VERSION ""

NS_ :

BS_:
BU_: Receiver ChassisBus VehicleBus PartyBus apb ui app aps bms gtwu odin cc cmp cp das dif dir di epas3p epas3s epbl epbr esp fc gtw hvp ibst ocs1p park pcs pmf pmr pm ptc radc rcm2 rcm sccm scm scs tas tpms umc vcfront vcleft vcright vcsec GTW

BO_ 905 ID389DAS_status2: 8 ChassisBus
   SG_ DAS_ACC_report : 26|5@1+ (1,0) [0|24] "" Receiver
   SG_ DAS_accSpeedLimit : 0|10@1+ (0.2,0) [0|204.6] "mph" Receiver
   SG_ DAS_activationFailureStatus : 14|2@1+ (1,0) [0|2] "" Receiver
   SG_ DAS_csaState : 32|2@1+ (1,0) [0|3] "" Receiver
   SG_ DAS_driverInteractionLevel : 38|2@1+ (1,0) [0|2] "" Receiver
   SG_ DAS_longCollisionWarning : 48|4@1+ (1,0) [0|15] "" Receiver
   SG_ DAS_pmmCameraFaultReason : 24|2@1+ (1,0) [0|2] "" Receiver
   SG_ DAS_pmmLoggingRequest : 13|1@1+ (1,0) [0|1] "" Receiver
   SG_ DAS_pmmObstacleSeverity : 10|3@1+ (1,0) [0|7] "" Receiver
   SG_ DAS_pmmRadarFaultReason : 19|2@1+ (1,0) [0|2] "" Receiver
   SG_ DAS_pmmSysFaultReason : 21|3@1+ (1,0) [0|7] "" Receiver
   SG_ DAS_pmmUltrasonicsFaultReason : 16|3@1+ (1,0) [0|4] "" Receiver
   SG_ DAS_ppOffsetDesiredRamp : 40|8@1+ (0.01,-1.28) [-1.28|1.27] "m" Receiver
   SG_ DAS_radarTelemetry : 34|2@1+ (1,0) [0|2] "" Receiver
   SG_ DAS_relaxCruiseLimits : 31|1@1+ (1,0) [0|1] "" Receiver
   SG_ DAS_robState : 36|2@1+ (1,0) [0|3] "" Receiver
   SG_ DAS_status2Checksum : 56|8@1+ (1,0) [0|255] "" Receiver
   SG_ DAS_status2Counter : 52|4@1+ (1,0) [0|15] "" Receiver

BO_ 921 ID399DAS_status: 8 ChassisBus
   SG_ DAS_autoLaneChangeState : 46|5@1+ (1,0) [0|31] "" Receiver
   SG_ DAS_autoParked : 25|1@1+ (1,0) [0|1] "" Receiver
   SG_ DAS_autoparkReady : 24|1@1+ (1,0) [0|1] "" Receiver
   SG_ DAS_autoparkWaitingForBrake : 26|1@1+ (1,0) [0|1] "" Receiver
   SG_ DAS_autopilotHandsOnState : 42|4@1+ (1,0) [0|15] "" Receiver
   SG_ DAS_autopilotState : 0|4@1+ (1,0) [0|15] "" Receiver
   SG_ DAS_blindSpotRearLeft : 4|2@1+ (1,0) [0|3] "" Receiver
   SG_ DAS_blindSpotRearRight : 6|2@1+ (1,0) [0|3] "" Receiver
   SG_ DAS_fleetSpeedState : 40|2@1+ (1,0) [0|3] "" Receiver
   SG_ DAS_forwardCollisionWarning : 22|2@1+ (1,0) [0|3] "" Receiver
   SG_ DAS_fusedSpeedLimit : 8|5@1+ (5,0) [0|150] "kph/mph" Receiver
   SG_ DAS_heaterState : 21|1@1+ (1,0) [0|1] "" Receiver
   SG_ DAS_laneDepartureWarning : 37|3@1+ (1,0) [0|5] "" Receiver
   SG_ DAS_lssState : 29|3@1+ (1,0) [0|7] "" Receiver
   SG_ DAS_sideCollisionAvoid : 32|2@1+ (1,0) [0|3] "" Receiver
   SG_ DAS_sideCollisionInhibit : 36|1@1+ (1,0) [0|1] "" Receiver
   SG_ DAS_sideCollisionWarning : 34|2@1+ (1,0) [0|3] "" Receiver
   SG_ DAS_statusChecksum : 56|8@1+ (1,0) [0|255] "" Receiver
   SG_ DAS_statusCounter : 52|4@1+ (1,0) [0|15] "" Receiver
   SG_ DAS_summonAvailable : 51|1@1+ (1,0) [0|1] "" Receiver
   SG_ DAS_summonClearedGate : 15|1@1+ (1,0) [0|1] "" Receiver
   SG_ DAS_summonFwdLeashReached : 27|1@1+ (1,0) [0|1] "" Receiver
   SG_ DAS_summonObstacle : 14|1@1+ (1,0) [0|1] "" Receiver
   SG_ DAS_summonRvsLeashReached : 28|1@1+ (1,0) [0|1] "" Receiver
   SG_ DAS_suppressSpeedWarning : 13|1@1+ (1,0) [0|1] "" Receiver
   SG_ DAS_visionOnlySpeedLimit : 16|5@1+ (5,0) [0|150] "kph/mph" Receiver

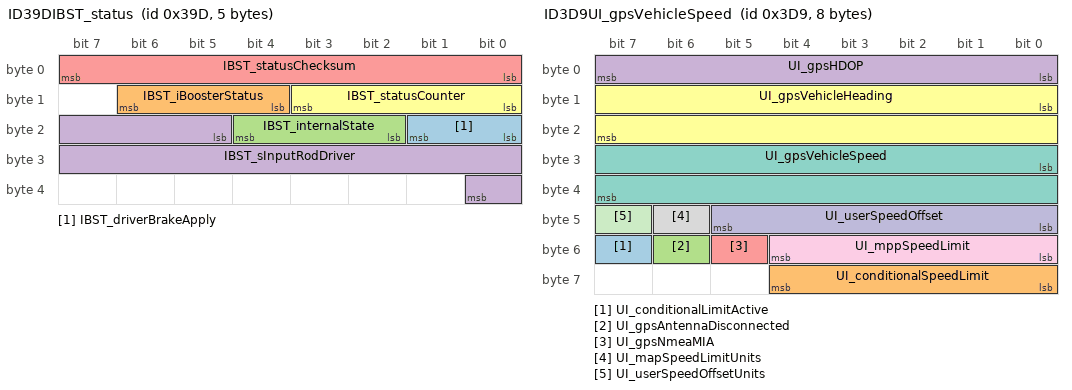
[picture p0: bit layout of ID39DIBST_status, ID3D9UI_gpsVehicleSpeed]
BO_ 925 ID39DIBST_status: 5 ChassisBus
   SG_ IBST_driverBrakeApply : 16|2@1+ (1,0) [0|3] "" Receiver
   SG_ IBST_iBoosterStatus : 12|3@1+ (1,0) [0|6] "" Receiver
   SG_ IBST_internalState : 18|3@1+ (1,0) [0|6] "" Receiver
   SG_ IBST_sInputRodDriver : 21|12@1+ (0.015625,-5) [-5|47] "mm" Receiver
   SG_ IBST_statusChecksum : 0|8@1+ (1,0) [0|255] "" Receiver
   SG_ IBST_statusCounter : 8|4@1+ (1,0) [0|15] "" Receiver

BO_ 929 ID3A1VCFRONT_vehicleStatus: 8 VehicleBus
   SG_ VCFRONT_12vStatusForDrive : 14|2@1+ (1,0) [0|2] "" Receiver
   SG_ VCFRONT_2RowCenterUnbuckled : 38|2@1+ (1,0) [0|2] "" Receiver
   SG_ VCFRONT_2RowLeftUnbuckled : 36|2@1+ (1,0) [0|2] "" Receiver
   SG_ VCFRONT_2RowRightUnbuckled : 40|2@1+ (1,0) [0|2] "" Receiver
   SG_ VCFRONT_APGlassHeaterState : 2|3@1+ (1,0) [0|4] "" Receiver
   SG_ VCFRONT_accPlusAvailable : 9|1@1+ (1,0) [0|1] "" Receiver
   SG_ VCFRONT_batterySupportRequest : 27|1@1+ (1,0) [0|1] "" Receiver
   SG_ VCFRONT_bmsHvChargeEnable : 0|1@1+ (1,0) [0|1] "" Receiver
   SG_ VCFRONT_diPowerOnState : 10|3@1+ (1,0) [0|4] "" Receiver
   SG_ VCFRONT_driverBuckleStatus : 30|1@1+ (1,0) [0|1] "" Receiver
   SG_ VCFRONT_driverDoorStatus : 31|1@1+ (1,0) [0|1] "" Receiver
   SG_ VCFRONT_driverIsLeaving : 28|1@1+ (1,0) [0|1] "" Receiver
   SG_ VCFRONT_driverIsLeavingAnySpeed : 13|1@1+ (1,0) [0|1] "" Receiver
   SG_ VCFRONT_driverPresent : 7|1@1+ (1,0) [0|1] "" Receiver
   SG_ VCFRONT_driverUnbuckled : 32|2@1+ (1,0) [0|2] "" Receiver
   SG_ VCFRONT_ota12VSupportRequest : 29|1@1+ (1,0) [0|1] "" Receiver
   SG_ VCFRONT_passengerPresent : 8|1@1+ (1,0) [0|1] "" Receiver
   SG_ VCFRONT_passengerUnbuckled : 34|2@1+ (1,0) [0|2] "" Receiver
   SG_ VCFRONT_pcs12vVoltageTarget : 16|11@1+ (0.01,0) [0|16] "V" Receiver
   SG_ VCFRONT_pcsEFuseVoltage : 42|10@1+ (0.1,0) [0|102.2] "V" Receiver
   SG_ VCFRONT_preconditionRequest : 1|1@1+ (1,0) [0|1] "" Receiver
   SG_ VCFRONT_standbySupplySupported : 6|1@1+ (1,0) [0|1] "" Receiver
   SG_ VCFRONT_thermalSystemType : 5|1@1+ (1,0) [0|1] "" Receiver
   SG_ VCFRONT_vehicleStatusChecksum : 56|8@1+ (1,0) [0|255] "" Receiver
   SG_ VCFRONT_vehicleStatusCounter : 52|4@1+ (1,0) [0|15] "" Receiver

BO_ 985 ID3D9UI_gpsVehicleSpeed: 8 ChassisBus
   SG_ UI_conditionalLimitActive : 55|1@1+ (1,0) [0|1] "" Receiver
   SG_ UI_conditionalSpeedLimit : 56|5@1+ (5,0) [0|155] "kph/mph" Receiver
   SG_ UI_gpsAntennaDisconnected : 54|1@1+ (1,0) [0|1] "" Receiver
   SG_ UI_gpsHDOP : 0|8@1+ (0.1,0) [0|25.5] "" Receiver
   SG_ UI_gpsNmeaMIA : 53|1@1+ (1,0) [0|1] "" Receiver
   SG_ UI_gpsVehicleHeading : 8|16@1+ (0.0078125,0) [0|511.992] "deg" Receiver
   SG_ UI_gpsVehicleSpeed : 24|16@1+ (0.00390625,0) [0|250.996] "kph" Receiver
   SG_ UI_mapSpeedLimitUnits : 46|1@1+ (1,0) [0|1] "" Receiver
   SG_ UI_mppSpeedLimit : 48|5@1+ (5,0) [0|155] "kph/mph" Receiver
   SG_ UI_userSpeedOffset : 40|6@1+ (1,-30) [-30|33] "kph/mph" Receiver
   SG_ UI_userSpeedOffsetUnits : 47|1@1+ (1,0) [0|1] "" Receiver

BO_ 994 ID3E2VCLEFT_lightStatus: 7 VehicleBus
   SG_ VCLEFT_FLMapLightStatus : 6|2@1+ (1,0) [0|3] "" Receiver
   SG_ VCLEFT_FLMapLightSwitchPressed : 14|1@1+ (1,0) [0|1] "" Receiver
   SG_ VCLEFT_FRMapLightStatus : 8|2@1+ (1,0) [0|3] "" Receiver
   SG_ VCLEFT_FRMapLightSwitchPressed : 15|1@1+ (1,0) [0|1] "" Receiver
   SG_ VCLEFT_RLMapLightStatus : 10|2@1+ (1,0) [0|3] "" Receiver
   SG_ VCLEFT_RLMapLightSwitchPressed : 16|1@1+ (1,0) [0|1] "" Receiver
   SG_ VCLEFT_RRMapLightStatus : 12|2@1+ (1,0) [0|3] "" Receiver
   SG_ VCLEFT_RRMapLightSwitchPressed : 17|1@1+ (1,0) [0|1] "" Receiver
   SG_ VCLEFT_brakeLightStatus : 0|2@1+ (1,0) [0|3] "" Receiver
   SG_ VCLEFT_brakeTrailerLightStatus : 22|2@1+ (1,0) [0|3] "" Receiver
   SG_ VCLEFT_dynamicBrakeLightStatus : 44|2@1+ (1,0) [0|2] "" Receiver
   SG_ VCLEFT_fogTrailerLightStatus : 26|2@1+ (1,0) [0|3] "" Receiver
   SG_ VCLEFT_frontRideHeight : 28|8@1- (1,0) [-127|127] "mm" Receiver
   SG_ VCLEFT_leftTurnTrailerLightStatu : 18|2@1+ (1,0) [0|3] "" Receiver
   SG_ VCLEFT_rearRideHeight : 36|8@1- (1,0) [-127|127] "mm" Receiver
   SG_ VCLEFT_reverseTrailerLightStatus : 49|2@1+ (1,0) [0|3] "" Receiver
   SG_ VCLEFT_rideHeightSensorFault : 48|1@1+ (1,0) [0|1] "" Receiver
   SG_ VCLEFT_rightTrnTrailerLightStatu : 20|2@1+ (1,0) [0|3] "" Receiver
   SG_ VCLEFT_tailLightStatus : 2|2@1+ (1,0) [0|3] "" Receiver
   SG_ VCLEFT_tailTrailerLightStatus : 24|2@1+ (1,0) [0|3] "" Receiver
   SG_ VCLEFT_trailerDetected : 46|2@1+ (1,0) [0|3] "" Receiver
   SG_ VCLEFT_turnSignalStatus : 4|2@1+ (1,0) [0|3] "" Receiver

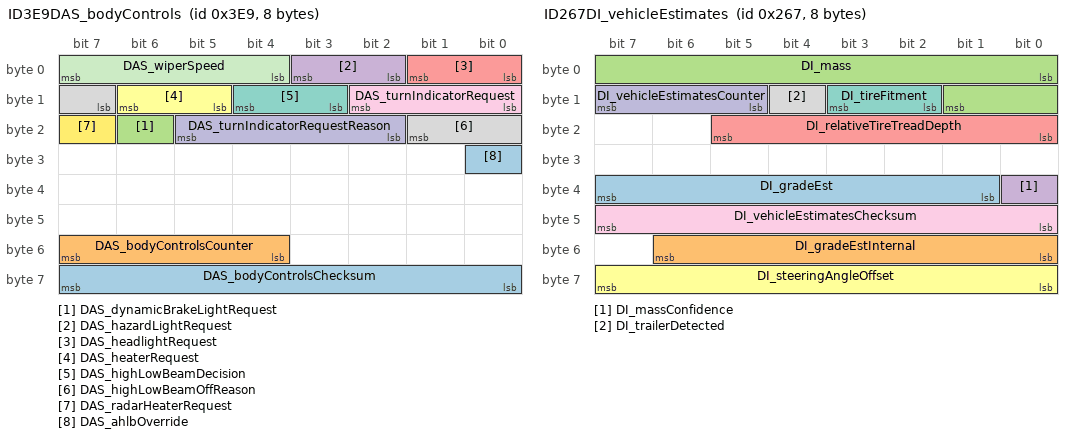
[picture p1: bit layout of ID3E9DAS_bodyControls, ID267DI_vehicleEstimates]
BO_ 1001 ID3E9DAS_bodyControls: 8 VehicleBus
   SG_ DAS_bodyControlsChecksum : 56|8@1+ (1,0) [0|255] "" Receiver
   SG_ DAS_bodyControlsCounter : 52|4@1+ (1,0) [0|15] "" Receiver
   SG_ DAS_dynamicBrakeLightRequest : 22|1@1+ (1,0) [0|1] "" Receiver
   SG_ DAS_hazardLightRequest : 2|2@1+ (1,0) [0|3] "" Receiver
   SG_ DAS_headlightRequest : 0|2@1+ (1,0) [0|3] "" Receiver
   SG_ DAS_heaterRequest : 13|2@1+ (1,0) [0|2] "" Receiver
   SG_ DAS_highLowBeamDecision : 11|2@1+ (1,0) [0|3] "" Receiver
   SG_ DAS_highLowBeamOffReason : 15|3@1+ (1,0) [0|5] "" Receiver
   SG_ DAS_turnIndicatorRequest : 8|3@1+ (1,0) [0|4] "" Receiver
   SG_ DAS_turnIndicatorRequestReason : 18|4@1+ (1,0) [0|12] "" Receiver
   SG_ DAS_wiperSpeed : 4|4@1+ (1,0) [0|15] "" Receiver
   SG_ DAS_radarHeaterRequest : 23|1@1+ (1,0) [0|1] "" Receiver
   SG_ DAS_ahlbOverride : 24|1@1+ (1,0) [0|1] "" Receiver

BO_ 1011 ID3F3UI_odo: 3 ChassisBus
   SG_ UI_odometer : 0|24@1+ (0.1,0) [0|1.67772e+06] "km" Receiver

BO_ 1013 ID3F5VCFRONT_lighting: 8 VehicleBus
   SG_ VCFRONT_DRLLeftStatus : 36|2@1+ (1,0) [0|3] "" Receiver
   SG_ VCFRONT_DRLRightStatus : 38|2@1+ (1,0) [0|3] "" Receiver
   SG_ VCFRONT_ambientLightingBrightnes : 8|8@1+ (0.5,0) [0|127] "%" Receiver
   SG_ VCFRONT_approachLightingRequest : 25|1@1+ (1,0) [0|1] "" Receiver
   SG_ VCFRONT_courtesyLightingRequest : 24|1@1+ (1,0) [0|1] "" Receiver
   SG_ VCFRONT_fogLeftStatus : 40|2@1+ (1,0) [0|3] "" Receiver
   SG_ VCFRONT_fogRightStatus : 42|2@1+ (1,0) [0|3] "" Receiver
   SG_ VCFRONT_hazardLightRequest : 4|4@1+ (1,0) [0|8] "" Receiver
   SG_ VCFRONT_hazardSwitchBacklight : 27|1@1+ (1,0) [0|1] "" Receiver
   SG_ VCFRONT_highBeamLeftStatus : 32|2@1+ (1,0) [0|3] "" Receiver
   SG_ VCFRONT_highBeamRightStatus : 34|2@1+ (1,0) [0|3] "" Receiver
   SG_ VCFRONT_highBeamSwitchActive : 58|1@1+ (1,0) [0|1] "" Receiver
   SG_ VCFRONT_indicatorLeftRequest : 0|2@1+ (1,0) [0|2] "" Receiver
   SG_ VCFRONT_indicatorRightRequest : 2|2@1+ (1,0) [0|2] "" Receiver
   SG_ VCFRONT_lowBeamLeftStatus : 28|2@1+ (1,0) [0|3] "" Receiver
   SG_ VCFRONT_lowBeamRightStatus : 30|2@1+ (1,0) [0|3] "" Receiver
   SG_ VCFRONT_lowBeamsCalibrated : 62|1@1+ (1,0) [0|1] "" Receiver
   SG_ VCFRONT_lowBeamsOnForDRL : 61|1@1+ (1,0) [0|1] "" Receiver
   SG_ VCFRONT_parkLeftStatus : 54|2@1+ (1,0) [0|3] "" Receiver
   SG_ VCFRONT_parkRightStatus : 56|2@1+ (1,0) [0|3] "" Receiver
   SG_ VCFRONT_seeYouHomeLightingReq : 26|1@1+ (1,0) [0|1] "" Receiver
   SG_ VCFRONT_sideMarkersStatus : 44|2@1+ (1,0) [0|3] "" Receiver
   SG_ VCFRONT_sideRepeaterLeftStatus : 46|2@1+ (1,0) [0|3] "" Receiver
   SG_ VCFRONT_sideRepeaterRightStatus : 48|2@1+ (1,0) [0|3] "" Receiver
   SG_ VCFRONT_simLatchingStalk : 59|2@1+ (1,0) [0|3] "" Receiver
   SG_ VCFRONT_switchLightingBrightness : 16|8@1+ (0.5,0) [0|127] "%" Receiver
   SG_ VCFRONT_turnSignalLeftStatus : 50|2@1+ (1,0) [0|3] "" Receiver
   SG_ VCFRONT_turnSignalRightStatus : 52|2@1+ (1,0) [0|3] "" Receiver

BO_ 1016 ID3F8UI_driverAssistControl: 8 ChassisBus
   SG_ UI_accFollowDistanceSetting : 45|3@1+ (1,0) [0|7] "" Receiver
   SG_ UI_adaptiveSetSpeedEnable : 39|1@1+ (1,0) [0|1] "" Receiver
   SG_ UI_alcOffHighwayEnable : 56|1@1+ (1,0) [0|1] "" Receiver
   SG_ UI_autoSummonEnable : 10|1@1+ (1,0) [0|1] "" Receiver
   SG_ UI_autopilotControlRequest : 0|1@1+ (1,0) [0|1] "" Receiver
   SG_ UI_coastToCoast : 9|1@1+ (1,0) [0|1] "" Receiver
   SG_ UI_curvSpeedAdaptDisable : 4|1@1+ (1,0) [0|1] "" Receiver
   SG_ UI_curvatureDatabaseOnly : 22|1@1+ (1,0) [0|1] "" Receiver
   SG_ UI_dasDeveloper : 5|1@1+ (1,0) [0|1] "" Receiver
   SG_ UI_driveOnMapsEnable : 13|1@1+ (1,0) [0|1] "" Receiver
   SG_ UI_drivingSide : 40|2@1+ (1,0) [0|2] "" Receiver
   SG_ UI_enableBrakeLightPulse : 63|1@1+ (1,0) [0|1] "" Receiver
   SG_ UI_enableClipTelemetry : 42|1@1+ (1,0) [0|1] "" Receiver
   SG_ UI_enableRoadSegmentTelemetry : 44|1@1+ (1,0) [0|1] "" Receiver
   SG_ UI_enableTripTelemetry : 43|1@1+ (1,0) [0|1] "" Receiver
   SG_ UI_enableVinAssociation : 6|1@1+ (1,0) [0|1] "" Receiver
   SG_ UI_enableVisionOnlyStops : 60|1@1+ (1,0) [0|1] "" Receiver
   SG_ UI_exceptionListEnable : 11|1@1+ (1,0) [0|1] "" Receiver
   SG_ UI_followNavRouteEnable : 49|1@1+ (1,0) [0|1] "" Receiver
   SG_ UI_fuseHPPDisable : 17|1@1+ (1,0) [0|1] "" Receiver
   SG_ UI_fuseLanesDisable : 16|1@1+ (1,0) [0|1] "" Receiver
   SG_ UI_fuseVehiclesDisable : 18|1@1+ (1,0) [0|1] "" Receiver
   SG_ UI_handsOnRequirementDisable : 14|1@1+ (1,0) [0|1] "" Receiver
   SG_ UI_hasDriveOnNav : 48|1@1+ (1,0) [0|1] "" Receiver
   SG_ UI_lssElkEnabled : 23|1@1+ (1,0) [0|1] "" Receiver
   SG_ UI_lssLdwEnabled : 8|1@1+ (1,0) [0|1] "" Receiver
   SG_ UI_lssLkaEnabled : 7|1@1+ (1,0) [0|1] "" Receiver
   SG_ UI_roadCheckDisable : 12|1@1+ (1,0) [0|1] "" Receiver
   SG_ UI_selfParkRequest : 28|4@1+ (1,0) [0|15] "" Receiver
   SG_ UI_smartSummonType : 58|2@1+ (1,0) [0|2] "" Receiver
   SG_ UI_source3D : 61|2@1+ (1,0) [0|2] "" Receiver
   SG_ UI_summonEntryType : 26|2@1+ (1,0) [0|3] "" Receiver
   SG_ UI_summonExitType : 24|2@1+ (1,0) [0|3] "" Receiver
   SG_ UI_summonHeartbeat : 2|2@1+ (1,0) [0|3] "" Receiver
   SG_ UI_summonReverseDist : 32|6@1+ (1,0) [0|63] "" Receiver
   SG_ UI_ulcBlindSpotConfig : 52|2@1+ (1,0) [0|2] "" Receiver
   SG_ UI_ulcOffHighway : 15|1@1+ (1,0) [0|1] "" Receiver
   SG_ UI_ulcSpeedConfig : 50|2@1+ (1,0) [0|3] "" Receiver
   SG_ UI_ulcStalkConfirm : 1|1@1+ (1,0) [0|1] "" Receiver
   SG_ UI_undertakeAssistEnable : 38|1@1+ (1,0) [0|1] "" Receiver
   SG_ UI_validationLoop : 57|1@1+ (1,0) [0|1] "" Receiver
   SG_ UI_visionSpeedType : 20|2@1+ (1,0) [0|3] "" Receiver

BO_ 1021 ID3FDUI_autopilotControl: 8 ChassisBus
   SG_ UI_autopilotControlIndex M : 0|3@1+ (1,0) [0|7] "" Receiver
   SG_ UI_apmv3Branch m1 : 40|3@1+ (1,0) [0|5] "" Receiver
   SG_ UI_applyEceR79 m1 : 19|1@1+ (1,0) [0|1] "" Receiver
   SG_ UI_blindspotDistance m0 : 15|3@1+ (1,0) [0|5] "" Receiver
   SG_ UI_blindspotMinSpeed m0 : 11|4@1+ (1,0) [0|10] "" Receiver
   SG_ UI_blindspotTTC m0 : 18|3@1+ (1,0) [0|7] "" Receiver
   SG_ UI_disableBackup m1 : 30|1@1+ (1,0) [0|1] "" Receiver
   SG_ UI_disableFisheye m1 : 25|1@1+ (1,0) [0|1] "" Receiver
   SG_ UI_disableLeftPillar m1 : 26|1@1+ (1,0) [0|1] "" Receiver
   SG_ UI_disableLeftRepeater m1 : 28|1@1+ (1,0) [0|1] "" Receiver
   SG_ UI_disableMain m1 : 23|1@1+ (1,0) [0|1] "" Receiver
   SG_ UI_disableNarrow m1 : 24|1@1+ (1,0) [0|1] "" Receiver
   SG_ UI_disableRadar m1 : 31|1@1+ (1,0) [0|1] "" Receiver
   SG_ UI_disableRightPillar m1 : 27|1@1+ (1,0) [0|1] "" Receiver
   SG_ UI_disableRightRepeater m1 : 29|1@1+ (1,0) [0|1] "" Receiver
   SG_ UI_donAlcProgGoreAbortThres m0 : 29|4@1+ (1,0) [0|9] "" Receiver
   SG_ UI_donDisableAutoWiperDuration m0 : 4|3@1+ (1,0) [0|6] "" Receiver
   SG_ UI_donDisableCutin m0 : 24|1@1+ (1,0) [0|1] "" Receiver
   SG_ UI_donDisableOnAutoWiperSpeed m0 : 7|4@1+ (1,0) [0|15] "" Receiver
   SG_ UI_donMinGoreWidthForAbortMap m0 : 25|4@1+ (1,0) [0|11] "" Receiver
   SG_ UI_donMinGoreWidthForAbortNotMap m0 : 33|4@1+ (1,0) [0|11] "" Receiver
   SG_ UI_donStopEndOfRampBuffer m0 : 21|3@1+ (1,0) [0|4] "" Receiver
   SG_ UI_driverMonitorConfirmation m1 : 17|1@1+ (1,0) [0|1] "" Receiver
   SG_ UI_enableAutopilotStopWarning m1 : 44|1@1+ (1,0) [0|1] "" Receiver
   SG_ UI_enableCabinCamera m1 : 43|1@1+ (1,0) [0|1] "" Receiver
   SG_ UI_enableCabinCameraTelemetry m1 : 48|1@1+ (1,0) [0|1] "" Receiver
   SG_ UI_enableMapStops m1 : 20|1@1+ (1,0) [0|1] "" Receiver
   SG_ UI_factorySummonEnable m1 : 39|1@1+ (1,0) [0|1] "" Receiver
   SG_ UI_fsdStopsControlEnabled m0 : 38|1@1+ (1,0) [0|1] "" Receiver
   SG_ UI_fsdVisualizationEnabled m0 : 37|1@1+ (1,0) [0|1] "" Receiver
   SG_ UI_hardCoreSummon m1 : 47|1@1+ (1,0) [0|1] "" Receiver
   SG_ UI_homelinkNearby m0 : 45|1@1+ (1,0) [0|1] "" Receiver
   SG_ UI_hovEnabled m0 : 3|1@1+ (1,0) [0|1] "" Receiver
   SG_ UI_noStalkConfirmAlertChime m1 : 37|1@1+ (1,0) [0|1] "" Receiver
   SG_ UI_noStalkConfirmAlertHaptic m1 : 32|1@1+ (1,0) [0|1] "" Receiver
   SG_ UI_showLaneGraph m1 : 45|1@1+ (1,0) [0|1] "" Receiver
   SG_ UI_showTrackLabels m1 : 46|1@1+ (1,0) [0|1] "" Receiver
   SG_ UI_ulcSnooze m1 : 36|1@1+ (1,0) [0|1] "" Receiver

BO_ 611 ID263VCRIGHT_logging10Hz: 8 VehicleBus
   SG_ VCRIGHT_logging10HzIndex M : 0|3@1+ (1,0) [0|4] "" Receiver
   SG_ VCRIGHT_EvapPulldownBias m3 : 8|8@1+ (0.4,0) [0|100] "%" Receiver
   SG_ VCRIGHT_EvapPulldownBiasActive m3 : 16|1@1+ (1,0) [0|1] "" Receiver
   SG_ VCRIGHT_hvacCabinHumidityLevel m2 : 55|8@1+ (1,0) [0|100] "%" Receiver
   SG_ VCRIGHT_hvacEstimateWindshieldRH m2 : 39|8@1+ (1,0) [0|150] "%" Receiver
   SG_ VCRIGHT_hvacFilterLifeDetectActi m2 : 3|1@1+ (1,0) [0|1] "" Receiver
   SG_ VCRIGHT_hvacFlashFoggingDetected m2 : 63|1@1+ (1,0) [0|1] "" Receiver
   SG_ VCRIGHT_hvacFoggingRiskLevel m2 : 47|8@1+ (1,0) [0|100] "%" Receiver
   SG_ VCRIGHT_hvacIntakeActuatorState m2 : 24|2@1+ (1,0) [0|2] "" Receiver
   SG_ VCRIGHT_hvacIntakeOperationMode m2 : 10|1@1+ (1,0) [0|1] "" Receiver
   SG_ VCRIGHT_hvacIntakePosition m1 : 56|8@1+ (0.4,0) [0|100] "%" Receiver
   SG_ VCRIGHT_hvacIntakeTarget m0 : 56|8@1+ (0.4,0) [0|100] "%" Receiver
   SG_ VCRIGHT_hvacLHBleedActuatorState m2 : 11|2@1+ (1,0) [0|2] "" Receiver
   SG_ VCRIGHT_hvacLHBleedOperationMode m2 : 4|1@1+ (1,0) [0|1] "" Receiver
   SG_ VCRIGHT_hvacLHBleedPosition m1 : 8|8@1+ (0.4,0) [0|100] "%" Receiver
   SG_ VCRIGHT_hvacLHBleedTarget m0 : 8|8@1+ (0.4,0) [0|100] "%" Receiver
   SG_ VCRIGHT_hvacLHVaneActuatorState m2 : 16|2@1+ (1,0) [0|2] "" Receiver
   SG_ VCRIGHT_hvacLHVaneOperationMode m2 : 6|1@1+ (1,0) [0|1] "" Receiver
   SG_ VCRIGHT_hvacLHVanePosition m1 : 24|8@1+ (0.4,0) [0|100] "%" Receiver
   SG_ VCRIGHT_hvacLHVaneTarget m0 : 24|8@1+ (0.4,0) [0|100] "%" Receiver
   SG_ VCRIGHT_hvacLowerModeActState m2 : 22|2@1+ (1,0) [0|2] "" Receiver
   SG_ VCRIGHT_hvacLowerModeOpMode m2 : 9|1@1+ (1,0) [0|1] "" Receiver
   SG_ VCRIGHT_hvacLowerModePosition m1 : 48|8@1+ (0.4,0) [0|100] "%" Receiver
   SG_ VCRIGHT_hvacLowerModeTarget m0 : 48|8@1+ (0.4,0) [0|100] "%" Receiver
   SG_ VCRIGHT_hvacRHBleedActuatorState m2 : 13|2@1+ (1,0) [0|2] "" Receiver
   SG_ VCRIGHT_hvacRHBleedOperationMode m2 : 5|1@1+ (1,0) [0|1] "" Receiver
   SG_ VCRIGHT_hvacRHBleedPosition m1 : 16|8@1+ (0.4,0) [0|100] "%" Receiver
   SG_ VCRIGHT_hvacRHBleedTarget m0 : 16|8@1+ (0.4,0) [0|100] "%" Receiver
   SG_ VCRIGHT_hvacRHVaneActuatorState m2 : 18|2@1+ (1,0) [0|2] "" Receiver
   SG_ VCRIGHT_hvacRHVaneOperationMode m2 : 7|1@1+ (1,0) [0|1] "" Receiver
   SG_ VCRIGHT_hvacRHVanePosition m1 : 32|8@1+ (0.4,0) [0|100] "%" Receiver
   SG_ VCRIGHT_hvacRHVaneTarget m0 : 32|8@1+ (0.4,0) [0|100] "%" Receiver
   SG_ VCRIGHT_hvacUpperModeActState m2 : 20|2@1+ (1,0) [0|2] "" Receiver
   SG_ VCRIGHT_hvacUpperModeOpMode m2 : 8|1@1+ (1,0) [0|1] "" Receiver
   SG_ VCRIGHT_hvacUpperModePosition m1 : 40|8@1+ (0.4,0) [0|100] "%" Receiver
   SG_ VCRIGHT_hvacUpperModeTarget m0 : 40|8@1+ (0.4,0) [0|100] "%" Receiver
   SG_ VCRIGHT_timeLeftToCabinModelInit m2 : 32|7@1+ (1,0) [0|127] "" Receiver

BO_ 615 ID267DI_vehicleEstimates: 8 VehicleBus
   SG_ DI_gradeEst : 33|7@1- (1,0) [-40|40] "%" Receiver
   SG_ DI_gradeEstInternal : 48|7@1- (1,0) [-40|40] "%" Receiver
   SG_ DI_mass : 0|10@1+ (5,1900) [1900|7010] "kg" Receiver
   SG_ DI_massConfidence : 32|1@1+ (1,0) [0|1] "" Receiver
   SG_ DI_relativeTireTreadDepth : 16|6@1- (0.2,0) [-6.2|6.2] "mm" Receiver
   SG_ DI_steeringAngleOffset : 56|8@1- (0.2,0) [-25.6|25.4] "Deg" Receiver
   SG_ DI_tireFitment : 10|2@1+ (1,0) [0|3] "" Receiver
   SG_ DI_trailerDetected : 12|1@1+ (1,0) [0|1] "" Receiver
   SG_ DI_vehicleEstimatesChecksum : 40|8@1+ (1,0) [0|255] "" Receiver
   SG_ DI_vehicleEstimatesCounter : 13|3@1+ (1,0) [0|7] "" Receiver

BO_ 642 ID282VCLEFT_hvacBlowerFeedback: 8 VehicleBus
   SG_ VCLEFT_blowerIndex M : 0|2@1+ (1,0) [0|1] "" Receiver
   SG_ VCLEFT_hvacBlowerCBCCtrlState m1 : 58|3@1+ (1,0) [0|4] "" Receiver
   SG_ VCLEFT_hvacBlowerCBCEstState m1 : 54|4@1+ (1,0) [0|14] "" Receiver
   SG_ VCLEFT_hvacBlowerEnabled m0 : 2|1@1+ (1,0) [0|1] "" Receiver
   SG_ VCLEFT_hvacBlowerFETTemp m0 : 44|7@1+ (1.5,-40) [-40|149] "C" Receiver
   SG_ VCLEFT_hvacBlowerFault m0 : 59|1@1+ (1,0) [0|1] "" Receiver
   SG_ VCLEFT_hvacBlowerIPhase0 m1 : 10|8@1+ (0.2,0) [0|50] "A" Receiver
   SG_ VCLEFT_hvacBlowerIPhase1 m1 : 18|8@1+ (0.2,0) [0|50] "A" Receiver
   SG_ VCLEFT_hvacBlowerIPhase2 m1 : 26|8@1+ (0.2,0) [0|50] "A" Receiver
   SG_ VCLEFT_hvacBlowerITerm m0 : 51|7@1+ (0.05,-1.5) [-1.5|4.5] "Nm" Receiver
   SG_ VCLEFT_hvacBlowerInitd m0 : 58|1@1+ (1,0) [0|1] "" Receiver
   SG_ VCLEFT_hvacBlowerLimitFETTemps m0 : 60|1@1+ (1,0) [0|1] "" Receiver
   SG_ VCLEFT_hvacBlowerOutputDuty m0 : 3|7@1+ (1,0) [0|100] "%" Receiver
   SG_ VCLEFT_hvacBlowerPowerOn m0 : 61|1@1+ (1,0) [0|1] "" Receiver
   SG_ VCLEFT_hvacBlowerRPMActual m0 : 20|10@1+ (10,0) [0|10000] "rpm" Receiver
   SG_ VCLEFT_hvacBlowerRPMTarget m0 : 10|10@1+ (10,0) [0|10000] "rpm" Receiver
   SG_ VCLEFT_hvacBlowerRs m1 : 2|8@1+ (0.25,0) [0|60] "mOhm" Receiver
   SG_ VCLEFT_hvacBlowerRsOnlineActive m1 : 61|1@1+ (1,0) [0|1] "" Receiver
   SG_ VCLEFT_hvacBlowerSpiError m0 : 62|1@1+ (1,0) [0|1] "" Receiver
   SG_ VCLEFT_hvacBlowerTorque m0 : 34|10@1+ (0.006,-1.5) [-1.5|4.5] "Nm" Receiver
   SG_ VCLEFT_hvacBlower_IO_CBC_HEAD m1 : 34|4@1+ (1,0) [0|15] "" Receiver
   SG_ VCLEFT_hvacBlower_IO_CBC_Status m1 : 43|1@1+ (1,0) [0|1] "" Receiver
   SG_ VCLEFT_hvacBlower_IO_CBC_TAIL m1 : 38|4@1+ (1,0) [0|15] "" Receiver
   SG_ VCLEFT_hvacBlower_IO_CBC_TAIL_va m1 : 42|1@1+ (1,0) [0|1] "" Receiver
   SG_ VCLEFT_hvacBlower_IO_CBC_numUart m1 : 46|8@1+ (1,0) [0|255] "" Receiver

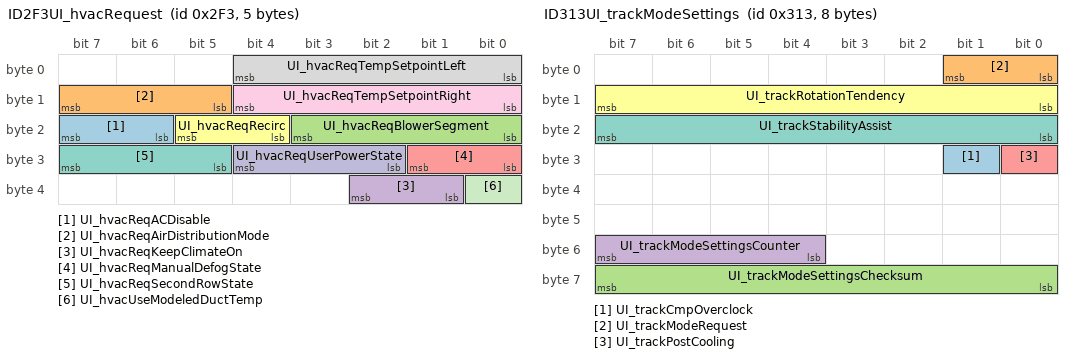
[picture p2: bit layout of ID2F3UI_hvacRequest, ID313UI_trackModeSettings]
BO_ 755 ID2F3UI_hvacRequest: 5 VehicleBus
   SG_ UI_hvacReqACDisable : 22|2@1+ (1,0) [0|2] "" Receiver
   SG_ UI_hvacReqAirDistributionMode : 13|3@1+ (1,0) [0|7] "" Receiver
   SG_ UI_hvacReqBlowerSegment : 16|4@1+ (1,0) [0|11] "" Receiver
   SG_ UI_hvacReqKeepClimateOn : 33|2@1+ (1,0) [0|3] "" Receiver
   SG_ UI_hvacReqManualDefogState : 24|2@1+ (1,0) [0|2] "" Receiver
   SG_ UI_hvacReqRecirc : 20|2@1+ (1,0) [0|2] "" Receiver
   SG_ UI_hvacReqSecondRowState : 29|3@1+ (1,0) [0|4] "" Receiver
   SG_ UI_hvacReqTempSetpointLeft : 0|5@1+ (0.5,15) [15|28] "C" Receiver
   SG_ UI_hvacReqTempSetpointRight : 8|5@1+ (0.5,15) [15|28] "C" Receiver
   SG_ UI_hvacReqUserPowerState : 26|3@1+ (1,0) [0|4] "" Receiver
   SG_ UI_hvacUseModeledDuctTemp : 32|1@1+ (1,0) [0|1] "" Receiver

BO_ 787 ID313UI_trackModeSettings: 8 VehicleBus
   SG_ UI_trackCmpOverclock : 25|1@1+ (1,0) [0|1] "" Receiver
   SG_ UI_trackModeRequest : 0|2@1+ (1,0) [0|2] "" Receiver
   SG_ UI_trackModeSettingsChecksum : 56|8@1+ (1,0) [0|255] "" Receiver
   SG_ UI_trackModeSettingsCounter : 52|4@1+ (1,0) [0|15] "" Receiver
   SG_ UI_trackPostCooling : 24|1@1+ (1,0) [0|1] "" Receiver
   SG_ UI_trackRotationTendency : 8|8@1+ (0.5,0) [0|100] "%" Receiver
   SG_ UI_trackStabilityAssist : 16|8@1+ (0.5,0) [0|100] "%" Receiver

BO_ 821 ID335RearDIinfo: 8 VehicleBus
   SG_ DIR_infoIndex M : 0|8@1+ (1,0) [0|255] "" Receiver
   SG_ DIR_FPGA_version m16 : 48|8@1+ (1,0) [0|255] "" Receiver
   SG_ DIR_appGitHash m17 : 8|56@1+ (1,0) [0|7.20576e+16] "" Receiver
   SG_ DIR_applicationCrc m13 : 32|32@1+ (1,0) [0|4.29497e+09] "" Receiver
   SG_ DIR_assemblyId m11 : 24|8@1+ (1,0) [0|255] "" Receiver
   SG_ DIR_bootGitHash m18 : 8|56@1+ (1,0) [0|7.20576e+16] "" Receiver
   SG_ DIR_bootloaderCrc m20 : 32|32@1+ (1,0) [0|4.29497e+09] "" Receiver
   SG_ DIR_buildConfigurationId m10 : 16|16@1+ (1,0) [0|65535] "" Receiver
   SG_ DIR_buildType m10 : 8|3@1+ (1,0) [0|4] "" Receiver
   SG_ DIR_componentId m10 : 48|16@1+ (1,0) [0|65535] "" Receiver
   SG_ DIR_hardwareId m10 : 32|8@1+ (1,0) [0|252] "" Receiver
   SG_ DIR_infoBootLdUdsProtocolVersion m20 : 8|8@1+ (1,0) [0|255] "" Receiver
   SG_ DIR_oilPumpAppCrc m16 : 16|32@1+ (1,0) [0|4.29497e+09] "" Receiver
   SG_ DIR_oilPumpBuildType m16 : 8|3@1+ (1,0) [0|4] "" Receiver
   SG_ DIR_pcbaId m11 : 16|8@1+ (1,0) [0|255] "" Receiver
   SG_ DIR_platformTyp m19 : 8|8@1+ (1,0) [0|255] "" Receiver
   SG_ DIR_subUsageId m11 : 48|16@1+ (1,0) [0|65535] "" Receiver
   SG_ DIR_subcomponentGitHash m31 : 8|56@1+ (1,0) [0|7.20576e+16] "" Receiver
   SG_ DIR_usageId m11 : 32|16@1+ (1,0) [0|65535] "" Receiver

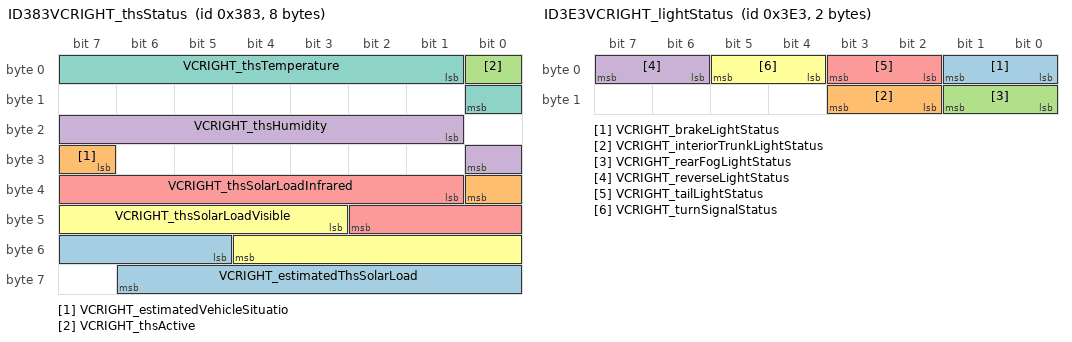
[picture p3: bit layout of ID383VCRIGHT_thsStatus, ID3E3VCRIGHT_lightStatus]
BO_ 899 ID383VCRIGHT_thsStatus: 8 VehicleBus
   SG_ VCRIGHT_estimatedThsSolarLoad : 53|10@1+ (1,0) [0|1022] "W/m2" Receiver
   SG_ VCRIGHT_estimatedVehicleSituatio : 31|2@1+ (1,0) [0|2] "" Receiver
   SG_ VCRIGHT_thsActive : 0|1@1+ (1,0) [0|1] "" Receiver
   SG_ VCRIGHT_thsHumidity : 17|8@1+ (1,0) [0|100] "%" Receiver
   SG_ VCRIGHT_thsSolarLoadInfrared : 33|10@1+ (1,0) [0|1022] "W/m2" Receiver
   SG_ VCRIGHT_thsSolarLoadVisible : 43|10@1+ (1,0) [0|1022] "W/m2" Receiver
   SG_ VCRIGHT_thsTemperature : 1|8@1- (1,-40) [-40|150] "C" Receiver

BO_ 915 ID393VCRIGHT_epbmDebug: 8 VehicleBus
   SG_ VCRIGHT_epbmDebugIndex M : 0|1@1+ (1,0) [0|1] "" Receiver
   SG_ VCRIGHT_cdpEnumDummy m1 : 24|2@1+ (1,0) [0|2] "" Receiver
   SG_ VCRIGHT_epbFaultStatus m0 : 58|2@1+ (1,0) [0|3] "" Receiver
   SG_ VCRIGHT_epbMotorCurrent m0 : 5|11@1+ (0.01,0) [0|20.47] "A" Receiver
   SG_ VCRIGHT_epbSummonState m0 : 45|3@1+ (1,0) [0|6] "" Receiver
   SG_ VCRIGHT_epbUnitStatus m0 : 51|5@1+ (1,0) [0|22] "" Receiver
   SG_ VCRIGHT_epbmApplyVoltage m0 : 16|11@1+ (0.01,0) [0|20.47] "A" Receiver
   SG_ VCRIGHT_epbmCaliperState m0 : 1|3@1+ (1,0) [0|6] "" Receiver
   SG_ VCRIGHT_epbmDynApplyingAllowed m1 : 9|1@1+ (1,0) [0|1] "" Receiver
   SG_ VCRIGHT_epbmDynamicAllowed m1 : 2|1@1+ (1,0) [0|1] "" Receiver
   SG_ VCRIGHT_epbmFaultAllowed m1 : 11|1@1+ (1,0) [0|1] "" Receiver
   SG_ VCRIGHT_epbmFaultStatus m0 : 56|2@1+ (1,0) [0|3] "" ui
   SG_ VCRIGHT_epbmMotorEnabled m0 : 4|1@1+ (1,0) [0|1] "" Receiver
   SG_ VCRIGHT_epbmOpenAllowed m1 : 1|1@1+ (1,0) [0|1] "" Receiver
   SG_ VCRIGHT_epbmParkAllowed m1 : 3|1@1+ (1,0) [0|1] "" Receiver
   SG_ VCRIGHT_epbmParkingAllowed m1 : 8|1@1+ (1,0) [0|1] "" Receiver
   SG_ VCRIGHT_epbmReleaseVoltage m0 : 27|11@1+ (0.01,0) [0|20.47] "A" Receiver
   SG_ VCRIGHT_epbmReleasingAllowed m1 : 10|1@1+ (1,0) [0|1] "" Receiver
   SG_ VCRIGHT_epbmServiceAllowed m1 : 5|1@1+ (1,0) [0|1] "" Receiver
   SG_ VCRIGHT_epbmStartAllowed m1 : 4|1@1+ (1,0) [0|1] "" Receiver
   SG_ VCRIGHT_epbmSummonAllowed m1 : 12|1@1+ (1,0) [0|1] "" Receiver
   SG_ VCRIGHT_epbmSummonParkAllowed m1 : 13|1@1+ (1,0) [0|1] "" Receiver
   SG_ VCRIGHT_epbmSummonReleaseAllowed m1 : 14|1@1+ (1,0) [0|1] "" Receiver
   SG_ VCRIGHT_epbmSummonState m0 : 48|3@1+ (1,0) [0|6] "" Receiver
   SG_ VCRIGHT_epbmSystemStatus m0 : 60|4@1+ (1,0) [0|8] "" Receiver
   SG_ VCRIGHT_epbmUnknownAllowed m1 : 16|1@1+ (1,0) [0|1] "" Receiver
   SG_ VCRIGHT_epbmWinchAllowed m1 : 6|1@1+ (1,0) [0|1] "" Receiver
   SG_ VCRIGHT_epbmWinchReleaseAllowed m1 : 7|1@1+ (1,0) [0|1] "" Receiver
   SG_ VCRIGHT_summonActiveAllowed m1 : 19|1@1+ (1,0) [0|1] "" Receiver
   SG_ VCRIGHT_summonArmedAllowed m1 : 18|1@1+ (1,0) [0|1] "" Receiver
   SG_ VCRIGHT_summonCompleteAllowed m1 : 20|1@1+ (1,0) [0|1] "" Receiver
   SG_ VCRIGHT_summonFaultAllowed m1 : 21|1@1+ (1,0) [0|1] "" Receiver
   SG_ VCRIGHT_summonFaultReason m0 : 40|5@1+ (1,0) [0|28] "" Receiver
   SG_ VCRIGHT_summonIdleAllowed m1 : 17|1@1+ (1,0) [0|1] "" Receiver
   SG_ VCRIGHT_summonInitAllowed m1 : 15|1@1+ (1,0) [0|1] "" Receiver
   SG_ VCRIGHT_summonUnavailableAllowed m1 : 22|1@1+ (1,0) [0|1] "" Receiver

BO_ 947 ID3B3UI_vehicleControl2: 4 VehicleBus
   SG_ UI_PINToDriveEnabled : 6|1@1+ (1,0) [0|1] "" Receiver
   SG_ UI_PINToDrivePassed : 7|1@1+ (1,0) [0|1] "" Receiver
   SG_ UI_UMCUpdateInhibit : 2|1@1+ (1,0) [0|1] "" Receiver
   SG_ UI_VCLEFTFeature1 : 15|1@1+ (1,0) [0|1] "" Receiver
   SG_ UI_VCSECFeature1 : 14|1@1+ (1,0) [0|1] "" Receiver
   SG_ UI_WCUpdateInhibit : 3|1@1+ (1,0) [0|1] "" Receiver
   SG_ UI_alarmTriggerRequest : 13|1@1+ (1,0) [0|1] "" Receiver
   SG_ UI_autoRollWindowsOnLockEnable : 29|1@1+ (1,0) [0|1] "" Receiver
   SG_ UI_autopilotPowerStateRequest : 25|2@1+ (1,0) [0|2] "" Receiver
   SG_ UI_batteryPreconditioningRequest : 23|1@1+ (1,0) [0|1] "" Receiver
   SG_ UI_coastDownMode : 24|1@1+ (1,0) [0|1] "" Receiver
   SG_ UI_efuseMXResistanceEstArmed : 30|1@1+ (1,0) [0|1] "" Receiver
   SG_ UI_freeRollModeRequest : 19|1@1+ (1,0) [0|1] "" Receiver
   SG_ UI_gloveboxRequest : 0|1@1+ (1,0) [0|1] "" Receiver
   SG_ UI_lightSwitch : 9|3@1+ (1,0) [0|4] "" Receiver
   SG_ UI_locksPanelActive : 5|1@1+ (1,0) [0|1] "" Receiver
   SG_ UI_readyToAddKey : 12|1@1+ (1,0) [0|1] "" Receiver
   SG_ UI_shorted12VCellTestMode : 27|2@1+ (1,0) [0|2] "" Receiver
   SG_ UI_soundHornOnLock : 4|1@1+ (1,0) [0|1] "" Receiver
   SG_ UI_summonState : 16|2@1+ (1,0) [0|3] "" Receiver
   SG_ UI_trunkRequest : 1|1@1+ (1,0) [0|1] "" Receiver
   SG_ UI_userPresent : 18|1@1+ (1,0) [0|1] "" Receiver
   SG_ UI_windowRequest : 20|3@1+ (1,0) [0|4] "" Receiver

BO_ 963 ID3C3VCRIGHT_switchStatus: 7 VehicleBus
   SG_ VCRIGHT_2RowSeatReclineSwitch : 54|1@1+ (1,0) [0|1] "" Receiver
   SG_ VCRIGHT_btnWindowAutoDownRF : 27|1@1+ (1,0) [0|1] "" Receiver
   SG_ VCRIGHT_btnWindowAutoDownRR : 31|1@1+ (1,0) [0|1] "" Receiver
   SG_ VCRIGHT_btnWindowAutoUpRF : 25|1@1+ (1,0) [0|1] "" Receiver
   SG_ VCRIGHT_btnWindowAutoUpRR : 29|1@1+ (1,0) [0|1] "" Receiver
   SG_ VCRIGHT_btnWindowDownRF : 26|1@1+ (1,0) [0|1] "" Receiver
   SG_ VCRIGHT_btnWindowDownRR : 30|1@1+ (1,0) [0|1] "" Receiver
   SG_ VCRIGHT_btnWindowSwPackAutoDwnLF : 35|1@1+ (1,0) [0|1] "" Receiver
   SG_ VCRIGHT_btnWindowSwPackAutoDwnLR : 39|1@1+ (1,0) [0|1] "" Receiver
   SG_ VCRIGHT_btnWindowSwPackAutoDwnRR : 52|1@1+ (1,0) [0|1] "" Receiver
   SG_ VCRIGHT_btnWindowSwPackAutoUpLF : 33|1@1+ (1,0) [0|1] "" Receiver
   SG_ VCRIGHT_btnWindowSwPackAutoUpLR : 37|1@1+ (1,0) [0|1] "" Receiver
   SG_ VCRIGHT_btnWindowSwPackAutoUpRR : 50|1@1+ (1,0) [0|1] "" Receiver
   SG_ VCRIGHT_btnWindowSwPackDownLF : 34|1@1+ (1,0) [0|1] "" Receiver
   SG_ VCRIGHT_btnWindowSwPackDownLR : 38|1@1+ (1,0) [0|1] "" Receiver
   SG_ VCRIGHT_btnWindowSwPackDownRR : 51|1@1+ (1,0) [0|1] "" Receiver
   SG_ VCRIGHT_btnWindowSwPackUpLF : 32|1@1+ (1,0) [0|1] "" Receiver
   SG_ VCRIGHT_btnWindowSwPackUpLR : 36|1@1+ (1,0) [0|1] "" Receiver
   SG_ VCRIGHT_btnWindowSwPackUpRR : 49|1@1+ (1,0) [0|1] "" Receiver
   SG_ VCRIGHT_btnWindowUpRF : 24|1@1+ (1,0) [0|1] "" Receiver
   SG_ VCRIGHT_btnWindowUpRR : 28|1@1+ (1,0) [0|1] "" Receiver
   SG_ VCRIGHT_frontBuckleSwitch : 40|2@1+ (1,0) [0|3] "" Receiver
   SG_ VCRIGHT_frontOccupancySwitch : 42|2@1+ (1,0) [0|3] "" Receiver
   SG_ VCRIGHT_frontSeatBackrestBack : 12|2@1+ (1,0) [0|3] "" Receiver
   SG_ VCRIGHT_frontSeatBackrestForward : 14|2@1+ (1,0) [0|3] "" Receiver
   SG_ VCRIGHT_frontSeatLiftDown : 8|2@1+ (1,0) [0|3] "" Receiver
   SG_ VCRIGHT_frontSeatLiftUp : 10|2@1+ (1,0) [0|3] "" Receiver
   SG_ VCRIGHT_frontSeatLumbarDown : 16|2@1+ (1,0) [0|3] "" Receiver
   SG_ VCRIGHT_frontSeatLumbarIn : 20|2@1+ (1,0) [0|3] "" Receiver
   SG_ VCRIGHT_frontSeatLumbarOut : 22|2@1+ (1,0) [0|3] "" Receiver
   SG_ VCRIGHT_frontSeatLumbarUp : 18|2@1+ (1,0) [0|3] "" Receiver
   SG_ VCRIGHT_frontSeatTiltDown : 4|2@1+ (1,0) [0|3] "" Receiver
   SG_ VCRIGHT_frontSeatTiltUp : 6|2@1+ (1,0) [0|3] "" Receiver
   SG_ VCRIGHT_frontSeatTrackBack : 0|2@1+ (1,0) [0|3] "" Receiver
   SG_ VCRIGHT_frontSeatTrackForward : 2|2@1+ (1,0) [0|3] "" Receiver
   SG_ VCRIGHT_liftgateShutfaceSwitchPr : 53|1@1+ (1,0) [0|1] "" Receiver
   SG_ VCRIGHT_rearCenterBuckleSwitch : 44|2@1+ (1,0) [0|3] "" Receiver
   SG_ VCRIGHT_rearRightBuckleSwitch : 46|2@1+ (1,0) [0|3] "" Receiver
   SG_ VCRIGHT_trunkExtReleasePressed : 48|1@1+ (1,0) [0|1] "" Receiver

BO_ 995 ID3E3VCRIGHT_lightStatus: 2 VehicleBus
   SG_ VCRIGHT_brakeLightStatus : 0|2@1+ (1,0) [0|3] "" Receiver
   SG_ VCRIGHT_interiorTrunkLightStatus : 10|2@1+ (1,0) [0|3] "" Receiver
   SG_ VCRIGHT_rearFogLightStatus : 8|2@1+ (1,0) [0|3] "" Receiver
   SG_ VCRIGHT_reverseLightStatus : 6|2@1+ (1,0) [0|3] "" Receiver
   SG_ VCRIGHT_tailLightStatus : 2|2@1+ (1,0) [0|3] "" Receiver
   SG_ VCRIGHT_turnSignalStatus : 4|2@1+ (1,0) [0|3] "" Receiver

BO_ 1622 ID656FrontDIinfo: 8 VehicleBus
   SG_ DIF_infoIndex M : 0|8@1+ (1,0) [0|255] "" Receiver
   SG_ DIF_FPGA_version m16 : 48|8@1+ (1,0) [0|255] "" Receiver
   SG_ DIF_appGitHash m17 : 8|56@1+ (1,0) [0|7.20576e+16] "" Receiver
   SG_ DIF_applicationCrc m13 : 32|32@1+ (1,0) [0|4.29497e+09] "" Receiver
   SG_ DIF_assemblyId m11 : 24|8@1+ (1,0) [0|255] "" Receiver
   SG_ DIF_bootGitHash m18 : 8|56@1+ (1,0) [0|7.20576e+16] "" Receiver
   SG_ DIF_bootloaderCrc m20 : 32|32@1+ (1,0) [0|4.29497e+09] "" Receiver
   SG_ DIF_buildConfigurationId m10 : 16|16@1+ (1,0) [0|65535] "" Receiver
   SG_ DIF_buildType m10 : 8|3@1+ (1,0) [0|4] "" Receiver
   SG_ DIF_componentId m10 : 48|16@1+ (1,0) [0|65535] "" Receiver
   SG_ DIF_hardwareId m10 : 32|8@1+ (1,0) [0|252] "" Receiver
   SG_ DIF_infoBootLdUdsProtocolVersion m20 : 8|8@1+ (1,0) [0|255] "" Receiver
   SG_ DIF_oilPumpAppCrc m16 : 16|32@1+ (1,0) [0|4.29497e+09] "" Receiver
   SG_ DIF_oilPumpBuildType m16 : 8|3@1+ (1,0) [0|4] "" Receiver
   SG_ DIF_pcbaId m11 : 16|8@1+ (1,0) [0|255] "" Receiver
   SG_ DIF_platformTyp m19 : 8|8@1+ (1,0) [0|255] "" Receiver
   SG_ DIF_subUsageId m11 : 48|16@1+ (1,0) [0|65535] "" Receiver
   SG_ DIF_subcomponentGitHash m31 : 8|56@1+ (1,0) [0|7.20576e+16] "" Receiver
   SG_ DIF_usageId m11 : 32|16@1+ (1,0) [0|65535] "" Receiver

BO_ 768 ID300BMS_info: 8 VehicleBus
   SG_ BMS_infoIndex M : 0|8@1+ (1,0) [0|255] "" Receiver
   SG_ BMS_appCrc m13 : 32|32@1+ (1,0) [0|4.29497e+09] "" Receiver
   SG_ BMS_appGitHash m17 : 8|56@1+ (1,0) [0|7.20576e+16] "" Receiver
   SG_ BMS_assemblyId m11 : 24|8@1+ (1,0) [0|255] "" Receiver
   SG_ BMS_bootCrc m20 : 32|32@1+ (1,0) [0|4.29497e+09] "" Receiver
   SG_ BMS_bootGitHash m18 : 8|56@1+ (1,0) [0|7.20576e+16] "" Receiver
   SG_ BMS_bootUdsProtoVersion m20 : 8|8@1+ (1,0) [0|255] "" Receiver
   SG_ BMS_buildConfigId m10 : 16|16@1+ (1,0) [0|65535] "" Receiver
   SG_ BMS_buildType m10 : 8|3@1+ (1,0) [0|4] "" Receiver
   SG_ BMS_componentId m10 : 48|16@1+ (1,0) [0|65535] "" Receiver
   SG_ BMS_hardwareId m10 : 32|16@1+ (1,0) [0|65535] "" Receiver
   SG_ BMS_pcbaId m11 : 16|8@1+ (1,0) [0|255] "" Receiver
   SG_ BMS_platformType m13 : 8|8@1+ (1,0) [0|255] "" Receiver
   SG_ BMS_subUsageId m11 : 48|16@1+ (1,0) [0|65535] "" Receiver
   SG_ BMS_usageId m11 : 32|16@1+ (1,0) [0|65535] "" Receiver

BO_ 530 ID212BMS_status: 8 VehicleBus
   SG_ BMS_activeHeatingWorthwhile : 5|1@1+ (1,0) [0|1] "" Receiver
   SG_ BMS_chargeRequest : 29|1@1+ (1,0) [0|1] "" Receiver
   SG_ BMS_chargeRetryCount : 51|3@1+ (1,0) [0|7] "" Receiver
   SG_ BMS_chgPowerAvailable : 40|11@1+ (0.125,0) [0|255.75] "kW" Receiver
   SG_ BMS_contactorState : 8|3@1+ (1,0) [0|6] "" Receiver
   SG_ BMS_cpMiaOnHvs : 6|1@1+ (1,0) [0|1] "" Receiver
   SG_ BMS_diLimpRequest : 36|1@1+ (1,0) [0|1] "" Receiver
   SG_ BMS_ecuLogUploadRequest : 14|2@1+ (1,0) [0|3] "" Receiver
   SG_ BMS_hvState : 16|3@1+ (1,0) [0|6] "" Receiver
   SG_ BMS_hvacPowerRequest : 0|1@1+ (1,0) [0|1] "" Receiver
   SG_ BMS_isolationResistance : 19|10@1+ (10,0) [0|10000] "kOhm" Receiver
   SG_ BMS_keepWarmRequest : 30|1@1+ (1,0) [0|1] "" Receiver
   SG_ BMS_notEnoughPowerForDrive : 1|1@1+ (1,0) [0|1] "" Receiver
   SG_ BMS_notEnoughPowerForSupport : 2|1@1+ (1,0) [0|1] "" Receiver
   SG_ BMS_okToShipByAir : 37|1@1+ (1,0) [0|1] "" Receiver
   SG_ BMS_okToShipByLand : 38|1@1+ (1,0) [0|1] "" Receiver
   SG_ BMS_pcsPwmEnabled : 7|1@1+ (1,0) [0|1] "" Receiver
   SG_ BMS_preconditionAllowed : 3|1@1+ (1,0) [0|1] "" Receiver
   SG_ BMS_smStateRequest : 56|4@1+ (1,0) [0|9] "" Receiver
   SG_ BMS_state : 32|4@1+ (1,0) [0|10] "" Receiver
   SG_ BMS_uiChargeStatus : 11|3@1+ (1,0) [0|5] "" Receiver
   SG_ BMS_updateAllowed : 4|1@1+ (1,0) [0|1] "" Receiver

BO_ 946 ID3B2BMS_log2: 8 VehicleBus
   SG_ BMS_log2MuxId M : 0|5@1+ (1,0) [0|25] "" Receiver
   SG_ BMS_100HzTask_avgExecTime m9 : 6|14@1+ (1,0) [0|16383] "us" Receiver
   SG_ BMS_100HzTask_maxExecTime m9 : 32|14@1+ (1,0) [0|16383] "us" Receiver
   SG_ BMS_10HzTask_avgExecTime m8 : 6|17@1+ (1,0) [0|131071] "us" Receiver
   SG_ BMS_10HzTask_maxExecTime m8 : 32|17@1+ (1,0) [0|131071] "us" Receiver
   SG_ BMS_1HzTask_avgExecTime m7 : 6|20@1+ (1,0) [0|1.04858e+06] "us" Receiver
   SG_ BMS_1HzTask_maxExecTime m7 : 32|20@1+ (1,0) [0|1.04858e+06] "us" Receiver
   SG_ BMS_1kHzTask_avgExecTime m9 : 20|11@1+ (1,0) [0|2047] "us" Receiver
   SG_ BMS_1kHzTask_maxExecTime m9 : 48|11@1+ (1,0) [0|2047] "us" Receiver
   SG_ BMS_ahChargeTotal m6 : 8|24@1+ (0.1,0) [0|1.67772e+06] "Ah" Receiver
   SG_ BMS_ahDischargeTotal m6 : 32|24@1+ (0.1,0) [0|1.67772e+06] "Ah" Receiver
   SG_ BMS_cacAvg m0 : 6|13@1+ (0.1,0) [0|819.1] "Ah" Receiver
   SG_ BMS_cacMax m0 : 40|13@1+ (0.1,0) [0|819.1] "Ah" Receiver
   SG_ BMS_cacMaxBrickId m0 : 56|7@1+ (1,1) [1|128] "" Receiver
   SG_ BMS_cacMaxKalmanError m1 : 44|10@1+ (0.01,0) [0|10] "Ah" Receiver
   SG_ BMS_cacMin m0 : 19|13@1+ (0.1,0) [0|819.1] "Ah" Receiver
   SG_ BMS_cacMinBrickId m0 : 32|7@1+ (1,1) [1|128] "" Receiver
   SG_ BMS_cacMinDeltaAh m23 : 26|11@1- (0.5,0) [-512|511.5] "Ah" Receiver
   SG_ BMS_cacMinLowerBoundEst m1 : 5|13@1+ (0.1,0) [0|819.1] "Ah" Receiver
   SG_ BMS_cacMinRawEstimate m1 : 18|13@1+ (0.1,0) [0|819.1] "Ah" Receiver
   SG_ BMS_cacMinSocByOcvEnd m23 : 16|10@1+ (0.1,0) [0|100] "%" Receiver
   SG_ BMS_cacMinSocByOcvStart m23 : 6|10@1+ (0.1,0) [0|100] "%" Receiver
   SG_ BMS_cacMinUpdateAhError m23 : 37|9@1- (0.05,0) [-12.8|12.75] "Ah" Receiver
   SG_ BMS_cacMinUpperBoundEst m1 : 31|13@1+ (0.1,0) [0|819.1] "Ah" Receiver
   SG_ BMS_capacityImbalancePct m1 : 54|10@1+ (0.1,0) [0|102.3] "%" Receiver
   SG_ BMS_chargeCurrentLimitMode m5 : 32|3@1+ (1,0) [0|6] "" Receiver
   SG_ BMS_chargeNeededReason m5 : 35|3@1+ (1,0) [0|6] "" Receiver
   SG_ BMS_chgEndBatteryChargeRequest m3 : 28|1@1+ (1,0) [0|1] "" Receiver
   SG_ BMS_chgEndBmsHvChargeStatus m3 : 16|3@1+ (1,0) [0|7] "" Receiver
   SG_ BMS_chgEndChargeState m3 : 12|3@1+ (1,0) [0|7] "" Receiver
   SG_ BMS_chgEndCpHvChargeStatus m3 : 19|3@1+ (1,0) [0|6] "" Receiver
   SG_ BMS_chgEndCpShutdownRequest m3 : 24|2@1+ (1,0) [0|2] "" Receiver
   SG_ BMS_chgEndDcEvseCompatible m3 : 29|1@1+ (1,0) [0|1] "" Receiver
   SG_ BMS_chgEndDisableUnderFailure m3 : 30|1@1+ (1,0) [0|1] "" Receiver
   SG_ BMS_chgEndEvseChargeType m3 : 6|2@1+ (1,0) [0|2] "" Receiver
   SG_ BMS_chgEndPcsHvChargeStatus m3 : 22|2@1+ (1,0) [0|3] "" Receiver
   SG_ BMS_chgEndPcsShutdownRequest m3 : 26|2@1+ (1,0) [0|2] "" Receiver
   SG_ BMS_chgRequestTerminatedCount m3 : 8|4@1+ (1,0) [0|15] "" Receiver
   SG_ BMS_cpChargeStatus m5 : 60|3@1+ (1,0) [0|5] "" Receiver
   SG_ BMS_currentReg_targetI m5 : 49|11@1+ (0.5,0) [0|1023.5] "A" Receiver
   SG_ BMS_dynamicEnergyBuffer m22 : 30|10@1+ (0.1,0) [0|102.2] "KWh" Receiver
   SG_ BMS_energyReserveAvg m20 : 48|16@1+ (0.001,0) [0|65.535] "V" Receiver
   SG_ BMS_energyReserveMax m20 : 32|16@1+ (0.001,0) [0|65.535] "V" Receiver
   SG_ BMS_energyReserveMin m20 : 16|16@1+ (0.001,0) [0|65.535] "V" Receiver
   SG_ BMS_fcLinkTestDecayTime m21 : 8|10@1+ (2,0) [0|2044] "mS" Receiver
   SG_ BMS_fcLinkTestTimeSinceLastRun m21 : 18|12@1+ (0.0175824,0) [0|71.99] "Hours" Receiver
   SG_ BMS_floodPortState1 m2 : 10|3@1+ (1,0) [0|4] "" Receiver
   SG_ BMS_floodPortState2 m2 : 13|3@1+ (1,0) [0|4] "" Receiver
   SG_ BMS_floodPortV1 m2 : 16|16@1+ (0.001,0) [0|65.535] "V" Receiver
   SG_ BMS_floodPortV2 m2 : 32|16@1+ (0.001,0) [0|65.535] "V" Receiver
   SG_ BMS_hvChain_iLimit m19 : 9|14@1+ (0.128,0) [0|2096.9] "A" Receiver
   SG_ BMS_hvChain_limitingState m19 : 24|5@1+ (1,0) [0|31] "" Receiver
   SG_ BMS_hvChain_limitingStateTempera m19 : 32|16@1- (0.01,0) [-327.68|327.67] "C" Receiver
   SG_ BMS_hvChain_useLeakyBucket m19 : 8|1@1+ (1,0) [0|1] "" Receiver
   SG_ BMS_idealEnergyFloor m22 : 20|10@1+ (0.1,0) [0|102.2] "KWh" Receiver
   SG_ BMS_loadReg_output m5 : 6|11@1- (0.1,0) [-102.4|102.3] "A" Receiver
   SG_ BMS_maxDcCurrentAvailable m5 : 38|11@1+ (0.5,0) [0|1023.5] "A" Receiver
   SG_ BMS_negCtrCommonModeRejError m18 : 6|13@1- (2.44259e-05,0) [-0.1|0.1] "-" Receiver
   SG_ BMS_negCtrCommonModeRejErrorConf m18 : 19|13@1+ (1.221,0) [0|10000] "-" Receiver
   SG_ BMS_negCtrDeviationConfidenceMax m15 : 45|13@1+ (0.0001221,0) [0|1] "-" Receiver
   SG_ BMS_negCtrDeviationConfidenceMin m15 : 32|13@1+ (0.0001221,0) [0|1] "-" Receiver
   SG_ BMS_negCtrDeviationFiltConfMax m16 : 45|13@1+ (0.0001221,0) [0|1] "-" Receiver
   SG_ BMS_negCtrDeviationFiltConfMin m16 : 32|13@1+ (0.0001221,0) [0|1] "-" Receiver
   SG_ BMS_negCtrDeviationFiltMax m16 : 19|13@1- (0.0012213,0) [-5|5] "V" Receiver
   SG_ BMS_negCtrDeviationFiltMin m16 : 6|13@1- (0.0012213,0) [-5|5] "V" Receiver
   SG_ BMS_negCtrDeviationMax m15 : 19|13@1- (0.0012213,0) [-5|5] "V" Receiver
   SG_ BMS_negCtrDeviationMin m15 : 6|13@1- (0.0012213,0) [-5|5] "V" Receiver
   SG_ BMS_negCtrDropCorrectedFiltMax m17 : 45|13@1- (0.0012213,0) [-5|5] "V" Receiver
   SG_ BMS_negCtrDropCorrectedFiltMin m17 : 32|13@1- (0.0012213,0) [-5|5] "V" Receiver
   SG_ BMS_negCtrDropCorrectedMax m17 : 19|13@1- (0.0012213,0) [-5|5] "V" Receiver
   SG_ BMS_negCtrDropCorrectedMin m17 : 6|13@1- (0.0012213,0) [-5|5] "V" Receiver
   SG_ BMS_negCtrOffsetError m18 : 32|13@1- (0.0012213,0) [-5|5] "V" Receiver
   SG_ BMS_negCtrOffsetErrorConf m18 : 45|13@1+ (0.0001221,0) [0|1] "-" Receiver
   SG_ BMS_negCtrResistance m10 : 32|13@1- (2.4426e-06,0) [-0.01|0.01] "Ohm" Receiver
   SG_ BMS_negCtrResistanceConfidence m10 : 45|13@1+ (12.21,0) [0|100000] "-" Receiver
   SG_ BMS_offsetReg_output m5 : 17|14@1- (0.1,0) [-819.2|819.1] "A" Receiver
   SG_ BMS_packRestTime m22 : 8|12@1+ (0.0175824,0) [0|71.99] "Hours" Receiver
   SG_ BMS_pcsPrechargeRequestActive m21 : 30|1@1+ (1,0) [0|1] "" Receiver
   SG_ BMS_pcsPrechargeTargetVoltage m21 : 32|16@1- (0.1,0) [-3276.8|3276.7] "V" Receiver
   SG_ BMS_posCtrCommonModeRejError m14 : 6|13@1- (2.4426e-05,0) [-0.1|0.1] "-" Receiver
   SG_ BMS_posCtrCommonModeRejErrorConf m14 : 19|13@1+ (1.221,0) [0|10000] "-" Receiver
   SG_ BMS_posCtrDeviationConfidenceMax m11 : 45|13@1+ (0.0001221,0) [0|1] "-" Receiver
   SG_ BMS_posCtrDeviationConfidenceMin m11 : 32|13@1+ (0.0001221,0) [0|1] "-" Receiver
   SG_ BMS_posCtrDeviationFiltConfMax m12 : 45|13@1+ (0.0001221,0) [0|1] "-" Receiver
   SG_ BMS_posCtrDeviationFiltConfMin m12 : 32|13@1+ (0.0001221,0) [0|1] "-" Receiver
   SG_ BMS_posCtrDeviationFiltMax m12 : 19|13@1- (0.0012213,0) [-5|5] "V" Receiver
   SG_ BMS_posCtrDeviationFiltMin m12 : 6|13@1- (0.0012213,0) [-5|5] "V" Receiver
   SG_ BMS_posCtrDeviationMax m11 : 19|13@1- (0.0012213,0) [-5|5] "V" Receiver
   SG_ BMS_posCtrDeviationMin m11 : 6|13@1- (0.0012213,0) [-5|5] "V" Receiver
   SG_ BMS_posCtrDropCorrectedFiltMax m13 : 45|13@1- (0.0012213,0) [-5|5] "V" Receiver
   SG_ BMS_posCtrDropCorrectedFiltMin m13 : 32|13@1- (0.0012213,0) [-5|5] "V" Receiver
   SG_ BMS_posCtrDropCorrectedMax m13 : 19|13@1- (0.0012213,0) [-5|5] "V" Receiver
   SG_ BMS_posCtrDropCorrectedMin m13 : 6|13@1- (0.0012213,0) [-5|5] "V" Receiver
   SG_ BMS_posCtrOffsetError m14 : 32|13@1- (0.0012213,0) [-5|5] "V" Receiver
   SG_ BMS_posCtrOffsetErrorConf m14 : 45|13@1+ (0.0001221,0) [0|1] "-" Receiver
   SG_ BMS_posCtrResistance m10 : 6|13@1- (2.4426e-06,0) [-0.01|0.01] "Ohm" Receiver
   SG_ BMS_posCtrResistanceConfidence m10 : 19|13@1+ (12.21,0) [0|100000] "-" Receiver
   SG_ BMS_vChangeWindowChangeInitV m24 : 38|12@1+ (0.002,0) [0|5] "V" Receiver
   SG_ BMS_vChangeWindowChangeIsOutlier m24 : 50|1@1+ (1,0) [0|1] "" Receiver
   SG_ BMS_vChangeWindowMaxVChange m24 : 25|6@1+ (0.0025,0) [0|0.15] "V" Receiver
   SG_ BMS_vChangeWindowMaxVChangeId m24 : 31|7@1+ (1,1) [1|128] "" Receiver
   SG_ BMS_vChangeWindowMinBrickV m24 : 6|12@1+ (0.002,0) [0|5] "V" Receiver
   SG_ BMS_vChangeWindowMinBrickVId m24 : 18|7@1+ (1,1) [1|128] "" Receiver
   SG_ BMS_vChangeWindowNumOutlierChang m24 : 58|6@1+ (1,0) [0|63] "" Receiver
   SG_ BMS_vChangeWindowTimeAfterWake m24 : 51|7@1+ (0.1,0) [0|12] "sec" Receiver
   SG_ BMS_vshTestMaxDeltaV m4 : 16|8@1+ (0.002,0) [0|0.5] "V" Receiver
   SG_ BMS_vshTestMaxDeltaVBrickID m4 : 24|7@1+ (1,1) [1|128] "" Receiver
   SG_ BMS_vshTestMinDeltaV m4 : 32|8@1+ (0.002,0) [0|0.5] "V" Receiver
   SG_ BMS_vshTestMinDeltaVBrickID m4 : 40|7@1+ (1,1) [1|128] "" Receiver
   SG_ BMS_maxSocChange m25 : 5|11@1- (0.1,0) [-100|100] "%" Receiver
   SG_ BMS_maxSocChangeBrickId m25 : 16|7@1+ (1,1) [1|108] "" Receiver
   SG_ BMS_socChangeSocByOcvMax m25 : 34|10@1+ (0.1,0) [0|100] "%" Receiver
   SG_ BMS_socChangeSocByOcvMin m25 : 24|10@1+ (0.1,0) [0|100] "%" Receiver

BO_ 800 ID320BMS_alertMatrix: 8 VehicleBus
   SG_ BMS_matrixIndex M : 0|4@1+ (1,0) [0|15] "" Receiver
   SG_ BMS_a001_Pack_Config_Mismatch m0 : 4|1@1+ (1,0) [0|1] "" Receiver
   SG_ BMS_a007_SW_Slowed_Chg_Batt_Cold m0 : 10|1@1+ (1,0) [0|1] "" Receiver
   SG_ BMS_a016_Pack_Module_Id_Mismatch m0 : 19|1@1+ (1,0) [0|1] "" Receiver
   SG_ BMS_a017_SW_Brick_OV m0 : 20|1@1+ (1,0) [0|1] "" Receiver
   SG_ BMS_a018_SW_Brick_UV m0 : 21|1@1+ (1,0) [0|1] "" Receiver
   SG_ BMS_a019_SW_Module_OT m0 : 22|1@1+ (1,0) [0|1] "" Receiver
   SG_ BMS_a021_SW_Dr_Limits_Regulation m0 : 24|1@1+ (1,0) [0|1] "" Receiver
   SG_ BMS_a022_SW_Over_Current m0 : 25|1@1+ (1,0) [0|1] "" Receiver
   SG_ BMS_a023_SW_Stack_OV m0 : 26|1@1+ (1,0) [0|1] "" Receiver
   SG_ BMS_a024_SW_Islanded_Brick m0 : 27|1@1+ (1,0) [0|1] "" Receiver
   SG_ BMS_a025_SW_PwrBalance_Anomaly m0 : 28|1@1+ (1,0) [0|1] "" Receiver
   SG_ BMS_a026_SW_HFCurrent_Anomaly m0 : 29|1@1+ (1,0) [0|1] "" Receiver
   SG_ BMS_a034_SW_Passive_Isolation m0 : 37|1@1+ (1,0) [0|1] "" Receiver
   SG_ BMS_a035_SW_Isolation m0 : 38|1@1+ (1,0) [0|1] "" Receiver
   SG_ BMS_a036_SW_HvpHvilFault m0 : 39|1@1+ (1,0) [0|1] "" Receiver
   SG_ BMS_a037_SW_Flood_Port_Open m0 : 40|1@1+ (1,0) [0|1] "" Receiver
   SG_ BMS_a039_SW_DC_Link_Over_Voltage m0 : 42|1@1+ (1,0) [0|1] "" Receiver
   SG_ BMS_a040_SW_Watch_Dog_HW_Trigger m0 : 43|1@1+ (1,0) [0|1] "" Receiver
   SG_ BMS_a041_SW_Destructive_Reset_So m0 : 44|1@1+ (1,0) [0|1] "" Receiver
   SG_ BMS_a042_SW_MPU_Error m0 : 45|1@1+ (1,0) [0|1] "" Receiver
   SG_ BMS_a043_SW_Watch_Dog_Reset m0 : 46|1@1+ (1,0) [0|1] "" Receiver
   SG_ BMS_a044_SW_Assertion m0 : 47|1@1+ (1,0) [0|1] "" Receiver
   SG_ BMS_a045_SW_Exception m0 : 48|1@1+ (1,0) [0|1] "" Receiver
   SG_ BMS_a046_SW_Task_Stack_Usage m0 : 49|1@1+ (1,0) [0|1] "" Receiver
   SG_ BMS_a047_SW_Task_Stack_Overflow m0 : 50|1@1+ (1,0) [0|1] "" Receiver
   SG_ BMS_a048_SW_Log_Upload_Request m0 : 51|1@1+ (1,0) [0|1] "" Receiver
   SG_ BMS_a050_SW_Brick_Voltage_MIA m0 : 53|1@1+ (1,0) [0|1] "" Receiver
   SG_ BMS_a051_SW_HVC_Vref_Bad m0 : 54|1@1+ (1,0) [0|1] "" Receiver
   SG_ BMS_a052_SW_PCS_MIA m0 : 55|1@1+ (1,0) [0|1] "" Receiver
   SG_ BMS_a054_SW_Ver_Supply_Fault m0 : 57|1@1+ (1,0) [0|1] "" Receiver
   SG_ BMS_a055_SW_HvChain_Model_Fault m0 : 58|1@1+ (1,0) [0|1] "" Receiver
   SG_ BMS_a056_SW_Standby_Supply_Fault m0 : 59|1@1+ (1,0) [0|1] "" Receiver
   SG_ BMS_a057_SW_Bandolier_Model_Warn m0 : 60|1@1+ (1,0) [0|1] "" Receiver
   SG_ BMS_a058_SW_Bandolier_Model_Rese m0 : 61|1@1+ (1,0) [0|1] "" Receiver
   SG_ BMS_a059_SW_Pack_Voltage_Sensing m0 : 62|1@1+ (1,0) [0|1] "" Receiver
   SG_ BMS_a060_SW_Leakage_Test_Failure m0 : 63|1@1+ (1,0) [0|1] "" Receiver
   SG_ BMS_a061_SW_BrickV_Change m1 : 4|1@1+ (1,0) [0|1] "" Receiver
   SG_ BMS_a062_SW_BrickV_Imbalance m1 : 5|1@1+ (1,0) [0|1] "" Receiver
   SG_ BMS_a063_SW_ChargePort_Fault m1 : 6|1@1+ (1,0) [0|1] "" Receiver
   SG_ BMS_a064_SW_SOC_Imbalance m1 : 7|1@1+ (1,0) [0|1] "" Receiver
   SG_ BMS_a065_SW_CAC_Imbalance m1 : 8|1@1+ (1,0) [0|1] "" Receiver
   SG_ BMS_a069_SW_Low_Power m1 : 12|1@1+ (1,0) [0|1] "" Receiver
   SG_ BMS_a071_SW_SM_TransCon_Not_Met m1 : 14|1@1+ (1,0) [0|1] "" Receiver
   SG_ BMS_a075_SW_Chg_Disable_Failure m1 : 18|1@1+ (1,0) [0|1] "" Receiver
   SG_ BMS_a076_SW_Dch_While_Charging m1 : 19|1@1+ (1,0) [0|1] "" Receiver
   SG_ BMS_a077_SW_Charger_Regulation m1 : 20|1@1+ (1,0) [0|1] "" Receiver
   SG_ BMS_a080_SW_Pack_Ctr_Impedance m1 : 23|1@1+ (1,0) [0|1] "" Receiver
   SG_ BMS_a081_SW_Ctr_Close_Blocked m1 : 24|1@1+ (1,0) [0|1] "" Receiver
   SG_ BMS_a082_SW_Ctr_Force_Open m1 : 25|1@1+ (1,0) [0|1] "" Receiver
   SG_ BMS_a083_SW_Ctr_Close_Failure m1 : 26|1@1+ (1,0) [0|1] "" Receiver
   SG_ BMS_a084_SW_Sleep_Wake_Aborted m1 : 27|1@1+ (1,0) [0|1] "" Receiver
   SG_ BMS_a087_SW_Feim_Test_Blocked m1 : 30|1@1+ (1,0) [0|1] "" Receiver
   SG_ BMS_a088_SW_VcFront_MIA_InDrive m1 : 31|1@1+ (1,0) [0|1] "" Receiver
   SG_ BMS_a089_SW_VcFront_MIA m1 : 32|1@1+ (1,0) [0|1] "" Receiver
   SG_ BMS_a090_SW_Gateway_MIA m1 : 33|1@1+ (1,0) [0|1] "" Receiver
   SG_ BMS_a091_SW_ChargePort_MIA m1 : 34|1@1+ (1,0) [0|1] "" Receiver
   SG_ BMS_a092_SW_ChargePort_Mia_On_Hv m1 : 35|1@1+ (1,0) [0|1] "" Receiver
   SG_ BMS_a094_SW_Drive_Inverter_MIA m1 : 37|1@1+ (1,0) [0|1] "" Receiver
   SG_ BMS_a098_SW_BMB_Data_Integrity_L m1 : 41|1@1+ (1,0) [0|1] "" Receiver
   SG_ BMS_a099_SW_BMB_Communication m1 : 42|1@1+ (1,0) [0|1] "" Receiver
   SG_ BMS_a105_SW_One_Module_Tsense m1 : 48|1@1+ (1,0) [0|1] "" Receiver
   SG_ BMS_a106_SW_All_Module_Tsense m1 : 49|1@1+ (1,0) [0|1] "" Receiver
   SG_ BMS_a107_SW_Stack_Voltage_MIA m1 : 50|1@1+ (1,0) [0|1] "" Receiver
   SG_ BMS_a121_SW_NVRAM_Config_Error m2 : 4|1@1+ (1,0) [0|1] "" Receiver
   SG_ BMS_a122_SW_BMS_Therm_Irrational m2 : 5|1@1+ (1,0) [0|1] "" Receiver
   SG_ BMS_a123_SW_Internal_Isolation m2 : 6|1@1+ (1,0) [0|1] "" Receiver
   SG_ BMS_a126_SW_Thermistor_Failure m2 : 9|1@1+ (1,0) [0|1] "" Receiver
   SG_ BMS_a127_SW_shunt_SNA m2 : 10|1@1+ (1,0) [0|1] "" Receiver
   SG_ BMS_a128_SW_shunt_MIA m2 : 11|1@1+ (1,0) [0|1] "" Receiver
   SG_ BMS_a129_SW_VSH_Failure m2 : 12|1@1+ (1,0) [0|1] "" Receiver
   SG_ BMS_a130_IO_CAN_Error m2 : 13|1@1+ (1,0) [0|1] "" Receiver
   SG_ BMS_a131_Bleed_FET_Failure m2 : 14|1@1+ (1,0) [0|1] "" Receiver
   SG_ BMS_a132_HW_BMB_OTP_Uncorrctbl m2 : 15|1@1+ (1,0) [0|1] "" Receiver
   SG_ BMS_a134_SW_Delayed_Ctr_Off m2 : 17|1@1+ (1,0) [0|1] "" Receiver
   SG_ BMS_a135_HW_BMB_Diagnostics_Fail m2 : 18|1@1+ (1,0) [0|1] "" Receiver
   SG_ BMS_a136_SW_Module_OT_Warning m2 : 19|1@1+ (1,0) [0|1] "" Receiver
   SG_ BMS_a137_SW_Brick_UV_Warning m2 : 20|1@1+ (1,0) [0|1] "" Receiver
   SG_ BMS_a138_SW_Brick_OV_Warning m2 : 21|1@1+ (1,0) [0|1] "" Receiver
   SG_ BMS_a139_SW_DC_Link_V_Irrational m2 : 22|1@1+ (1,0) [0|1] "" Receiver
   SG_ BMS_a141_SW_BMB_Status_Warning m2 : 24|1@1+ (1,0) [0|1] "" Receiver
   SG_ BMS_a143_SW_CAC_Change m2 : 26|1@1+ (1,0) [0|1] "" Receiver
   SG_ BMS_a144_Hvp_Config_Mismatch m2 : 27|1@1+ (1,0) [0|1] "" Receiver
   SG_ BMS_a145_SW_SOC_Change m2 : 28|1@1+ (1,0) [0|1] "" Receiver
   SG_ BMS_a146_SW_Brick_Overdischarged m2 : 29|1@1+ (1,0) [0|1] "" Receiver
   SG_ BMS_a149_SW_Missing_Config_Block m2 : 32|1@1+ (1,0) [0|1] "" Receiver
   SG_ BMS_a151_SW_external_isolation m2 : 34|1@1+ (1,0) [0|1] "" Receiver
   SG_ BMS_a155_SW_Weak_short_impedence m2 : 38|1@1+ (1,0) [0|1] "" Receiver
   SG_ BMS_a156_SW_BMB_Vref_bad m2 : 39|1@1+ (1,0) [0|1] "" Receiver
   SG_ BMS_a158_SW_HVP_HVI_Comms m2 : 41|1@1+ (1,0) [0|1] "" Receiver
   SG_ BMS_a159_SW_HVP_ECU_Error m2 : 42|1@1+ (1,0) [0|1] "" Receiver
   SG_ BMS_a160_SW_FC_Ctr_Clean_Failed m2 : 43|1@1+ (1,0) [0|1] "" Receiver
   SG_ BMS_a161_SW_DI_Open_Request m2 : 44|1@1+ (1,0) [0|1] "" Receiver
   SG_ BMS_a162_SW_No_Power_For_Support m2 : 45|1@1+ (1,0) [0|1] "" Receiver
   SG_ BMS_a163_SW_Contactor_Mismatch m2 : 46|1@1+ (1,0) [0|1] "" Receiver
   SG_ BMS_a164_SW_Uncontrolled_Regen m2 : 47|1@1+ (1,0) [0|1] "" Receiver
   SG_ BMS_a165_SW_Pack_Partial_Weld m2 : 48|1@1+ (1,0) [0|1] "" Receiver
   SG_ BMS_a166_SW_Pack_Full_Weld m2 : 49|1@1+ (1,0) [0|1] "" Receiver
   SG_ BMS_a167_SW_FC_Partial_Weld m2 : 50|1@1+ (1,0) [0|1] "" Receiver
   SG_ BMS_a168_SW_FC_Full_Weld m2 : 51|1@1+ (1,0) [0|1] "" Receiver
   SG_ BMS_a169_SW_FC_Pack_Weld m2 : 52|1@1+ (1,0) [0|1] "" Receiver
   SG_ BMS_a170_SW_Limp_Mode m2 : 53|1@1+ (1,0) [0|1] "" Receiver
   SG_ BMS_a171_SW_Stack_Voltage_Sense m2 : 54|1@1+ (1,0) [0|1] "" Receiver
   SG_ BMS_a174_SW_Charge_Failure m2 : 57|1@1+ (1,0) [0|1] "" Receiver
   SG_ BMS_a176_SW_GracefulPowerOff m2 : 59|1@1+ (1,0) [0|1] "" Receiver
   SG_ BMS_a178_SW_Uncontrolled_Regen_P m2 : 61|1@1+ (1,0) [0|1] "" Receiver
   SG_ BMS_a179_SW_Hvp_12V_Fault m2 : 62|1@1+ (1,0) [0|1] "" Receiver
   SG_ BMS_a180_SW_ECU_reset_blocked m2 : 63|1@1+ (1,0) [0|1] "" Receiver

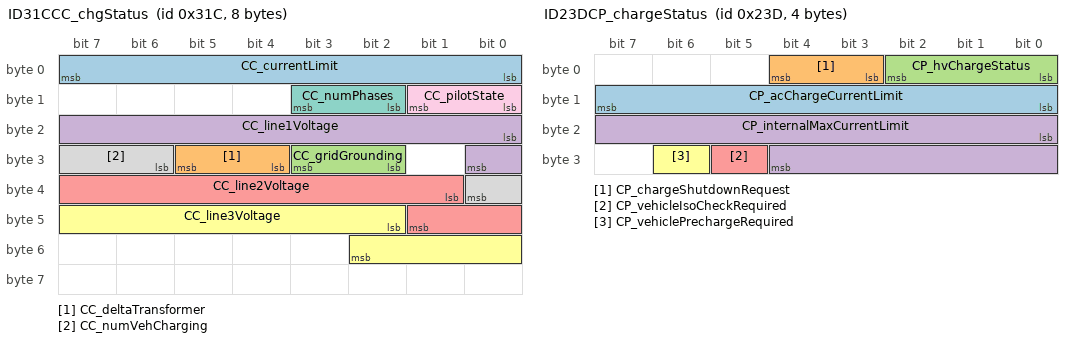
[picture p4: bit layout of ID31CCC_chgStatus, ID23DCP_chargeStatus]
BO_ 796 ID31CCC_chgStatus: 8 VehicleBus
   SG_ CC_currentLimit : 0|8@1+ (0.5,0) [0|127.5] "A" Receiver
   SG_ CC_deltaTransformer : 28|2@1+ (1,0) [0|3] "" Receiver
   SG_ CC_gridGrounding : 26|2@1+ (1,0) [0|2] "" Receiver
   SG_ CC_line1Voltage : 16|9@1+ (1,0) [0|511] "V" Receiver
   SG_ CC_line2Voltage : 33|9@1+ (1,0) [0|511] "V" Receiver
   SG_ CC_line3Voltage : 42|9@1+ (1,0) [0|511] "V" Receiver
   SG_ CC_numPhases : 10|2@1+ (1,0) [0|3] "" Receiver
   SG_ CC_numVehCharging : 30|3@1+ (1,0) [0|7] "" Receiver
   SG_ CC_pilotState : 8|2@1+ (1,0) [0|3] "" Receiver

BO_ 797 ID31DCC_chgStatus2: 8 VehicleBus
   SG_ CC_chgStatus2Index M : 0|8@1+ (1,0) [0|0] "" Receiver
   SG_ CC_buttonState m0 : 8|1@1+ (1,0) [0|1] "" Receiver

BO_ 812 ID32CCC_logData: 8 VehicleBus
   SG_ CC_logIndex M : 0|8@1+ (1,0) [0|13] "" Receiver
   SG_ CC_activeConnectorID m0 : 8|8@1+ (1,0) [0|255] "" Receiver
   SG_ CC_conn1Current m1 : 8|8@1+ (0.5,0) [0|127.5] "A" Receiver
   SG_ CC_conn2Current m2 : 8|8@1+ (0.5,0) [0|127.5] "A" Receiver
   SG_ CC_conn3Current m3 : 8|8@1+ (0.5,0) [0|127.5] "A" Receiver
   SG_ CC_conn4Current m4 : 8|8@1+ (0.5,0) [0|127.5] "A" Receiver
   SG_ CC_contactor1Closed m0 : 40|2@1+ (1,0) [0|3] "" Receiver
   SG_ CC_contactor2Closed m0 : 42|2@1+ (1,0) [0|3] "" Receiver
   SG_ CC_lifetimeAlertCount m12 : 8|28@1+ (1,0) [0|2.68435e+08] "" Receiver
   SG_ CC_lifetimeAvgStartupTemp m13 : 36|28@1- (0.1,0) [-1.34218e+07|1.34218e+07] "C" Receiver
   SG_ CC_lifetimeCtrCycles m11 : 8|28@1+ (1,0) [0|2.68435e+08] "" Receiver
   SG_ CC_lifetimeCtrCyclesLoaded m11 : 36|28@1+ (1,0) [0|2.68435e+08] "" Receiver
   SG_ CC_lifetimeThermalFoldbacks m12 : 36|28@1+ (1,0) [0|2.68435e+08] "" Receiver
   SG_ CC_lifetimei2t m10 : 32|32@1+ (0.1,0) [0|4.29497e+08] "A2h" Receiver
   SG_ CC_temperature1 m0 : 16|8@1- (1,88) [-40|215] "C" Receiver
   SG_ CC_temperature2 m0 : 24|8@1- (1,88) [-40|215] "C" Receiver
   SG_ CC_temperature3 m0 : 32|8@1- (1,88) [-40|215] "C" Receiver
   SG_ CC_temperature4 m0 : 44|8@1- (1,88) [-40|215] "C" Receiver

BO_ 573 ID23DCP_chargeStatus: 4 VehicleBus
   SG_ CP_acChargeCurrentLimit : 8|8@1+ (0.5,0) [0|127.5] "A" Receiver
   SG_ CP_chargeShutdownRequest : 3|2@1+ (1,0) [0|2] "" Receiver
   SG_ CP_hvChargeStatus : 0|3@1+ (1,0) [0|6] "" Receiver
   SG_ CP_internalMaxCurrentLimit : 16|13@1+ (0.146502,0) [0|1200] "A" Receiver
   SG_ CP_vehicleIsoCheckRequired : 29|1@1+ (1,0) [0|1] "" Receiver
   SG_ CP_vehiclePrechargeRequired : 30|1@1+ (1,0) [0|1] "" Receiver

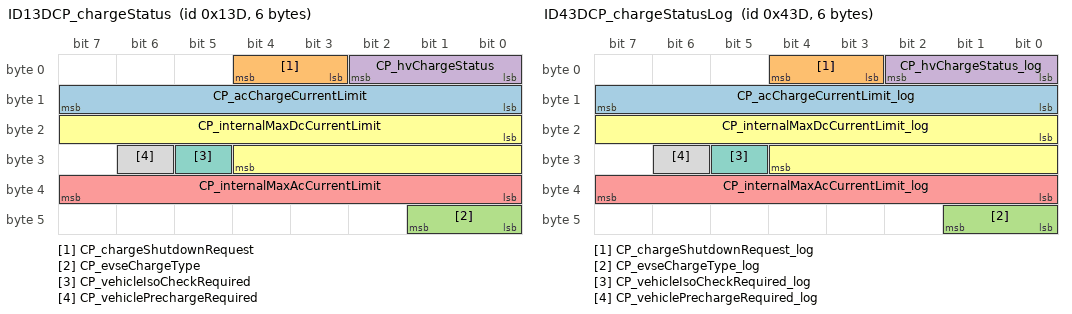
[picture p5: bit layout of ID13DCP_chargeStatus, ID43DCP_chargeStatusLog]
BO_ 317 ID13DCP_chargeStatus: 6 VehicleBus
   SG_ CP_acChargeCurrentLimit : 8|8@1+ (0.5,0) [0|127.5] "A" Receiver
   SG_ CP_chargeShutdownRequest : 3|2@1+ (1,0) [0|2] "" Receiver
   SG_ CP_evseChargeType : 40|2@1+ (1,0) [0|2] "" Receiver
   SG_ CP_hvChargeStatus : 0|3@1+ (1,0) [0|6] "" Receiver
   SG_ CP_internalMaxAcCurrentLimit : 32|8@1+ (0.5,0) [0|127.5] "A" Receiver
   SG_ CP_internalMaxDcCurrentLimit : 16|13@1+ (0.146502,0) [0|1200] "A" Receiver
   SG_ CP_vehicleIsoCheckRequired : 29|1@1+ (1,0) [0|1] "" Receiver
   SG_ CP_vehiclePrechargeRequired : 30|1@1+ (1,0) [0|1] "" Receiver

BO_ 1085 ID43DCP_chargeStatusLog: 6 VehicleBus
   SG_ CP_acChargeCurrentLimit_log : 8|8@1+ (0.5,0) [0|127.5] "A" Receiver
   SG_ CP_chargeShutdownRequest_log : 3|2@1+ (1,0) [0|2] "" Receiver
   SG_ CP_evseChargeType_log : 40|2@1+ (1,0) [0|2] "" Receiver
   SG_ CP_hvChargeStatus_log : 0|3@1+ (1,0) [0|6] "" Receiver
   SG_ CP_internalMaxAcCurrentLimit_log : 32|8@1+ (0.5,0) [0|127.5] "A" Receiver
   SG_ CP_internalMaxDcCurrentLimit_log : 16|13@1+ (0.146502,0) [0|1200] "A" Receiver
   SG_ CP_vehicleIsoCheckRequired_log : 29|1@1+ (1,0) [0|1] "" Receiver
   SG_ CP_vehiclePrechargeRequired_log : 30|1@1+ (1,0) [0|1] "" Receiver

BO_ 541 ID21DCP_evseStatus: 8 VehicleBus
   SG_ CP_acChargeState : 53|3@1+ (1,0) [0|6] "" Receiver
   SG_ CP_acNumRetries : 40|2@1+ (1,0) [0|3] "" Receiver
   SG_ CP_cableCurrentLimit : 24|7@1+ (1,0) [0|127] "A" Receiver
   SG_ CP_cableType : 16|3@1+ (1,0) [0|4] "" Receiver
   SG_ CP_digitalCommsAttempts : 32|2@1+ (1,0) [0|3] "" Receiver
   SG_ CP_digitalCommsEstablished : 37|1@1+ (1,0) [0|1] "" Receiver
   SG_ CP_evseAccept : 0|1@1+ (1,0) [0|1] "" Receiver
   SG_ CP_evseChargeType_UI : 38|2@1+ (1,0) [0|2] "" Receiver
   SG_ CP_evseRequest : 1|1@1+ (1,0) [0|1] "" Receiver
   SG_ CP_gbState : 42|4@1+ (1,0) [0|15] "" Receiver
   SG_ CP_gbdcChargeAttempts : 51|2@1+ (1,0) [0|3] "" Receiver
   SG_ CP_gbdcFailureReason : 49|2@1+ (1,0) [0|3] "" Receiver
   SG_ CP_gbdcStopChargeReason : 46|3@1+ (1,0) [0|7] "" Receiver
   SG_ CP_iecComboState : 60|4@1+ (1,0) [0|12] "" Receiver
   SG_ CP_pilot : 4|3@1+ (1,0) [0|7] "" Receiver
   SG_ CP_pilotCurrent : 8|8@1+ (0.5,0) [0|127.5] "A" Receiver
   SG_ CP_proximity : 2|2@1+ (1,0) [0|3] "" Receiver
   SG_ CP_teslaDcState : 56|4@1+ (1,0) [0|10] "" Receiver
   SG_ CP_teslaSwcanState : 34|3@1+ (1,0) [0|6] "" Receiver

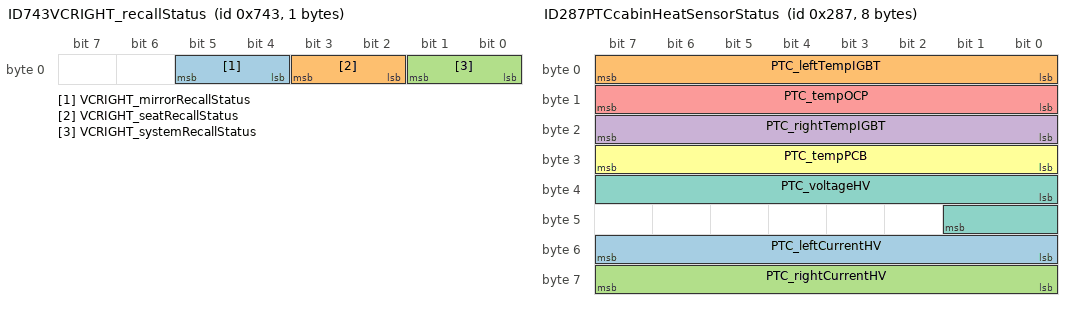
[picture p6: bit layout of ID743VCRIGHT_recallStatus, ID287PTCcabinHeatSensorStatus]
BO_ 1859 ID743VCRIGHT_recallStatus: 1 VehicleBus
   SG_ VCRIGHT_mirrorRecallStatus : 4|2@1+ (1,0) [0|3] "" Receiver
   SG_ VCRIGHT_seatRecallStatus : 2|2@1+ (1,0) [0|3] "" Receiver
   SG_ VCRIGHT_systemRecallStatus : 0|2@1+ (1,0) [0|3] "" Receiver

BO_ 1885 ID75DCP_sensorData: 8 VehicleBus
   SG_ CP_sensorDataSelect M : 0|4@1+ (1,0) [0|12] "" Receiver
   SG_ CP_UHF_chipState m6 : 4|3@1+ (1,0) [0|7] "" Receiver
   SG_ CP_UHF_fifoData m6 : 32|8@1+ (1,0) [0|255] "" Receiver
   SG_ CP_UHF_rssi m6 : 8|8@1+ (1,0) [0|255] "" Receiver
   SG_ CP_UHF_rxNumBytes m6 : 24|8@1+ (1,0) [0|255] "" Receiver
   SG_ CP_UHF_rxOverflow m6 : 16|1@1+ (1,0) [0|1] "" Receiver
   SG_ CP_UHF_selfTestRssi m6 : 40|8@1+ (1,0) [0|255] "" Receiver
   SG_ CP_backCover2Counts m5 : 32|16@1+ (0.0015259,0) [0|100] "%" Receiver
   SG_ CP_backCoverCounts m5 : 16|16@1+ (0.0015259,0) [0|100] "%" Receiver
   SG_ CP_boardTemperature m1 : 32|8@1+ (1.29412,-50) [-50|280] "C" Receiver
   SG_ CP_doorCountsDebounced m0 : 24|16@1+ (0.0015259,0) [0|100] "%" Receiver
   SG_ CP_doorCountsFiltered m0 : 8|16@1+ (0.0015259,0) [0|100] "%" Receiver
   SG_ CP_doorI m2 : 16|12@1+ (0.0025,0) [0|10.2375] "A" Receiver
   SG_ CP_doorLastRequestMaxI m2 : 28|12@1+ (0.0025,0) [0|10.2375] "A" Receiver
   SG_ CP_doorPot m2 : 4|12@1+ (0.025,0) [0|100] "%" Receiver
   SG_ CP_faultLineV m5 : 4|12@1+ (0.00114,0) [0|4.65524] "V" Receiver
   SG_ CP_inductiveSensor_raw m4 : 4|28@1+ (1,0) [0|2.68435e+08] "" Receiver
   SG_ CP_inlet1HarnessIdState m12 : 4|2@1+ (1,0) [0|2] "" Receiver
   SG_ CP_inlet1HarnessIdValue m12 : 8|3@1+ (1,0) [0|7] "" Receiver
   SG_ CP_inlet1HarnessV m12 : 16|14@1+ (0.001,0) [0|13.3] "V" Receiver
   SG_ CP_inlet2HarnessIdState m12 : 30|2@1+ (1,0) [0|2] "" Receiver
   SG_ CP_inlet2HarnessIdValue m12 : 32|3@1+ (1,0) [0|7] "" Receiver
   SG_ CP_inlet2HarnessV m12 : 40|14@1+ (0.001,0) [0|13.3] "V" Receiver
   SG_ CP_latch2I m3 : 16|12@1+ (0.0025,0) [0|10.2375] "A" Receiver
   SG_ CP_latchI m3 : 4|12@1+ (0.0025,0) [0|10.2375] "A" Receiver
   SG_ CP_pilotHighValue m9 : 40|12@1- (0.01,0) [-20.48|20.47] "V" Receiver
   SG_ CP_pilotHighValue_intervalMax10s m10 : 28|12@1- (0.01,0) [-20.48|20.47] "V" Receiver
   SG_ CP_pilotHighValue_intervalMin10s m10 : 40|12@1- (0.01,0) [-20.48|20.47] "V" Receiver
   SG_ CP_pilotLowValue m9 : 28|12@1- (0.01,0) [-20.48|20.47] "V" Receiver
   SG_ CP_pilotLowValue_intervalMax10s m10 : 4|12@1- (0.01,0) [-20.48|20.47] "V" Receiver
   SG_ CP_pilotLowValue_intervalMin10s m10 : 16|12@1- (0.01,0) [-20.48|20.47] "V" Receiver
   SG_ CP_pilotPeriod m9 : 16|12@1+ (1,0) [0|4095] "" Receiver
   SG_ CP_pilotPulseWidth m9 : 4|12@1+ (1,0) [0|4095] "" Receiver
   SG_ CP_pinTemperature1 m1 : 8|8@1+ (0.803922,-55) [-55|149.99] "C" Receiver
   SG_ CP_pinTemperature2 m1 : 16|8@1+ (0.803922,-55) [-55|149.99] "C" Receiver
   SG_ CP_pinTemperature3 m1 : 24|8@1+ (0.803922,-55) [-55|149.99] "C" Receiver
   SG_ CP_proxConn1Sense m8 : 56|1@1+ (1,0) [0|1] "" Receiver
   SG_ CP_proxEn m8 : 57|1@1+ (1,0) [0|1] "" Receiver
   SG_ CP_proximityV m8 : 8|16@1+ (0.0001,0) [0|6.5535] "V" Receiver
   SG_ CP_proximityV_GBCC1 m11 : 8|14@1+ (0.001,0) [0|13.3] "V" Receiver
   SG_ CP_proximityV_GBCC2 m11 : 24|14@1+ (0.001,0) [0|13.3] "V" Receiver
   SG_ CP_proximityV_intervalMax10s m8 : 40|16@1+ (0.0001,0) [0|6.5535] "V" Receiver
   SG_ CP_proximityV_intervalMin10s m8 : 24|16@1+ (0.0001,0) [0|6.5535] "V" Receiver
   SG_ CP_refVoltage m7 : 8|8@1+ (0.00705882,0) [0|1.8] "V" Receiver

BO_ 1962 ID7AAHVP_debugMessage: 8 VehicleBus
   SG_ HVP_debugMessageMultiplexer M : 0|4@1+ (1,0) [0|6] "" Receiver
   SG_ HVP_auxCurrentMia m0 : 57|1@1+ (1,0) [0|1] "" Receiver
   SG_ HVP_battery12V m5 : 36|12@1+ (0.1,0) [0|30] "V" Receiver
   SG_ HVP_currentSenseMia m0 : 58|1@1+ (1,0) [0|1] "" Receiver
   SG_ HVP_dcLinkNegativeV m3 : 8|16@1- (0.1,0) [-550|550] "V" Receiver
   SG_ HVP_dcLinkPositiveV m3 : 24|16@1- (0.1,0) [-550|550] "V" Receiver
   SG_ HVP_dcLinkVoltage m1 : 8|16@1- (0.1,0) [-3276.8|3276.7] "V" Receiver
   SG_ HVP_fcContCoilCurrent m4 : 4|12@1+ (0.1,0) [0|7.5] "A" Receiver
   SG_ HVP_fcContVoltage m4 : 16|12@1+ (0.1,0) [0|30] "V" Receiver
   SG_ HVP_fcLinkNegativeV m3 : 40|16@1- (0.1,0) [-550|550] "V" Receiver
   SG_ HVP_fcLinkPositiveV m5 : 8|16@1- (0.1,0) [-550|550] "V" Receiver
   SG_ HVP_fcLinkVoltage m1 : 40|16@1- (0.1,0) [-3276.8|3276.7] "V" Receiver
   SG_ HVP_gpioBmsEout m0 : 15|1@1+ (1,0) [0|1] "" Receiver
   SG_ HVP_gpioCpFaultIn m0 : 6|1@1+ (1,0) [0|1] "" Receiver
   SG_ HVP_gpioCpFaultOut m0 : 16|1@1+ (1,0) [0|1] "" Receiver
   SG_ HVP_gpioCpLatchEnable m0 : 21|1@1+ (1,0) [0|1] "" Receiver
   SG_ HVP_gpioCrashSignal m0 : 11|1@1+ (1,0) [0|1] "" Receiver
   SG_ HVP_gpioFcContNegAux m0 : 14|1@1+ (1,0) [0|1] "" Receiver
   SG_ HVP_gpioFcContPosAux m0 : 13|1@1+ (1,0) [0|1] "" Receiver
   SG_ HVP_gpioFcContPowerEnable m0 : 25|1@1+ (1,0) [0|1] "" Receiver
   SG_ HVP_gpioHvCablesOk m0 : 8|1@1+ (1,0) [0|1] "" Receiver
   SG_ HVP_gpioHvilEnable m0 : 26|1@1+ (1,0) [0|1] "" Receiver
   SG_ HVP_gpioHvpSelfEnable m0 : 9|1@1+ (1,0) [0|1] "" Receiver
   SG_ HVP_gpioHvpVerEn m0 : 19|1@1+ (1,0) [0|1] "" Receiver
   SG_ HVP_gpioLed m0 : 10|1@1+ (1,0) [0|1] "" Receiver
   SG_ HVP_gpioPackContPowerEn m0 : 7|1@1+ (1,0) [0|1] "" Receiver
   SG_ HVP_gpioPackCoontPosFlywheel m0 : 20|1@1+ (1,0) [0|1] "" Receiver
   SG_ HVP_gpioPassivePyroDepl m0 : 4|1@1+ (1,0) [0|1] "" Receiver
   SG_ HVP_gpioPcsChargePwmEnable m0 : 24|1@1+ (1,0) [0|1] "" Receiver
   SG_ HVP_gpioPcsDcdcPwmEnable m0 : 23|1@1+ (1,0) [0|1] "" Receiver
   SG_ HVP_gpioPcsEnable m0 : 22|1@1+ (1,0) [0|1] "" Receiver
   SG_ HVP_gpioPyroIsoEn m0 : 5|1@1+ (1,0) [0|1] "" Receiver
   SG_ HVP_gpioPyroPor m0 : 17|1@1+ (1,0) [0|1] "" Receiver
   SG_ HVP_gpioSecDrdy m0 : 27|1@1+ (1,0) [0|1] "" Receiver
   SG_ HVP_gpioShuntDataReady m0 : 12|1@1+ (1,0) [0|1] "" Receiver
   SG_ HVP_gpioShuntEn m0 : 18|1@1+ (1,0) [0|1] "" Receiver
   SG_ HVP_hvilInVoltage m4 : 28|12@1+ (0.1,0) [0|30] "V" Receiver
   SG_ HVP_hvilOutVoltage m4 : 40|12@1+ (0.1,0) [0|30] "V" Receiver
   SG_ HVP_hvp1v5Ref m0 : 28|12@1+ (0.1,0) [0|3] "V" Receiver
   SG_ HVP_packContCoilCurrent m5 : 24|12@1+ (0.1,0) [0|7.5] "A" Receiver
   SG_ HVP_packContVoltage m2 : 4|12@1+ (0.1,0) [0|30] "V" Receiver
   SG_ HVP_packCurrentMia m0 : 56|1@1+ (1,0) [0|1] "" Receiver
   SG_ HVP_packNegativeV m2 : 16|16@1- (0.1,0) [-550|550] "V" Receiver
   SG_ HVP_packPositiveV m2 : 32|16@1- (0.1,0) [-550|550] "V" Receiver
   SG_ HVP_packVoltage m1 : 24|16@1- (0.1,0) [-3276.8|3276.7] "V" Receiver
   SG_ HVP_pyroAnalog m2 : 48|12@1+ (0.1,0) [0|3] "V" Receiver
   SG_ HVP_shuntAsicTempDbg m6 : 40|16@1- (0.01,0) [-327.67|327.67] "C" Receiver
   SG_ HVP_shuntAsicTempStatus m6 : 60|2@1+ (1,0) [0|3] "" Receiver
   SG_ HVP_shuntAuxCurrentDbg m6 : 8|16@1- (0.1,0) [-3276.8|3276.7] "A" Receiver
   SG_ HVP_shuntAuxCurrentStatus m6 : 56|2@1+ (1,0) [0|3] "" Receiver
   SG_ HVP_shuntBarTempDbg m6 : 24|16@1- (0.01,0) [-327.67|327.67] "C" Receiver
   SG_ HVP_shuntBarTempStatus m6 : 58|2@1+ (1,0) [0|3] "" Receiver
   SG_ HVP_shuntCurrentDebug m0 : 40|16@1- (0.1,0) [-3276.8|3276.7] "A" Receiver
   SG_ HVP_shuntHwMia m0 : 61|1@1+ (1,0) [0|1] "" Receiver
   SG_ HVP_shuntRefVoltageDbg m5 : 48|16@1- (0.001,0) [-32.768|32.767] "V" Receiver
   SG_ HVP_shuntRefVoltageMismatch m0 : 59|1@1+ (1,0) [0|1] "" Receiver
   SG_ HVP_shuntThermistorMia m0 : 60|1@1+ (1,0) [0|1] "" Receiver

BO_ 647 ID287PTCcabinHeatSensorStatus: 8 VehicleBus
   SG_ PTC_leftCurrentHV : 48|8@1+ (0.2,0) [0|50] "A" Receiver
   SG_ PTC_leftTempIGBT : 0|8@1+ (1,-40) [-40|200] "C" Receiver
   SG_ PTC_rightCurrentHV : 56|8@1+ (0.2,0) [0|50] "A" Receiver
   SG_ PTC_rightTempIGBT : 16|8@1+ (1,-40) [-40|200] "C" Receiver
   SG_ PTC_tempOCP : 8|8@1+ (1,-40) [-40|200] "C" Receiver
   SG_ PTC_tempPCB : 24|8@1+ (1,-40) [-40|200] "C" Receiver
   SG_ PTC_voltageHV : 32|10@1+ (0.5,0) [0|511.5] "V" Receiver

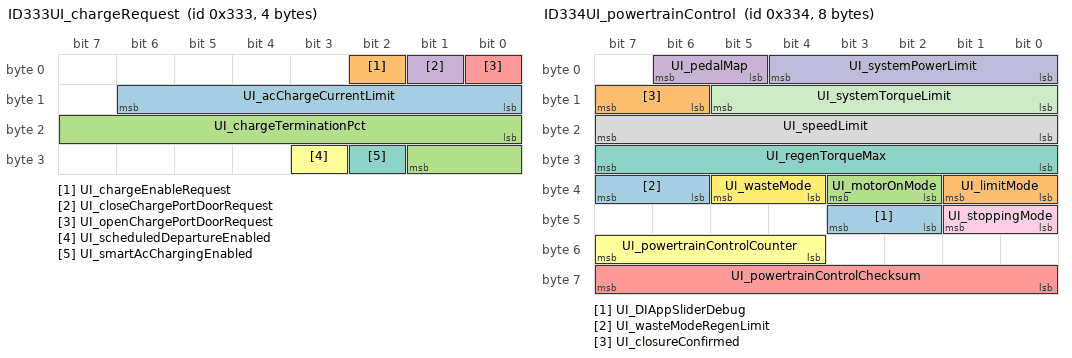
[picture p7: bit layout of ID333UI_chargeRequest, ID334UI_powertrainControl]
BO_ 819 ID333UI_chargeRequest: 4 VehicleBus
   SG_ UI_acChargeCurrentLimit : 8|7@1+ (1,0) [0|127] "A" Receiver
   SG_ UI_chargeEnableRequest : 2|1@1+ (1,0) [0|1] "" Receiver
   SG_ UI_chargeTerminationPct : 16|10@1+ (0.1,0) [25|100] "%" Receiver
   SG_ UI_closeChargePortDoorRequest : 1|1@1+ (1,0) [0|1] "" Receiver
   SG_ UI_openChargePortDoorRequest : 0|1@1+ (1,0) [0|1] "" Receiver
   SG_ UI_scheduledDepartureEnabled : 27|1@1+ (1,0) [0|1] "" Receiver
   SG_ UI_smartAcChargingEnabled : 26|1@1+ (1,0) [0|1] "" Receiver

BO_ 820 ID334UI_powertrainControl: 8 VehicleBus
   SG_ UI_DIAppSliderDebug : 42|2@1+ (1,0) [0|3] "" Receiver
   SG_ UI_limitMode : 32|2@1+ (1,0) [0|3] "" Receiver
   SG_ UI_motorOnMode : 34|2@1+ (1,0) [0|2] "" Receiver
   SG_ UI_pedalMap : 5|2@1+ (1,0) [0|2] "" Receiver
   SG_ UI_powertrainControlChecksum : 56|8@1+ (1,0) [0|255] "" Receiver
   SG_ UI_powertrainControlCounter : 52|4@1+ (1,0) [0|15] "" Receiver
   SG_ UI_regenTorqueMax : 24|8@1+ (0.5,0) [0|100] "%" Receiver
   SG_ UI_speedLimit : 16|8@1+ (1,50) [50|285] "kph" Receiver
   SG_ UI_stoppingMode : 40|2@1+ (1,0) [0|2] "" Receiver
   SG_ UI_systemPowerLimit : 0|5@1+ (20,20) [20|640] "kW" Receiver
   SG_ UI_systemTorqueLimit : 8|6@1+ (100,4000) [4000|10300] "Nm" Receiver
   SG_ UI_wasteMode : 36|2@1+ (1,0) [0|2] "" Receiver
   SG_ UI_wasteModeRegenLimit : 38|2@1+ (1,0) [0|3] "" Receiver
   SG_ UI_closureConfirmed : 14|2@1+ (1,0) [0|2] "" Receiver

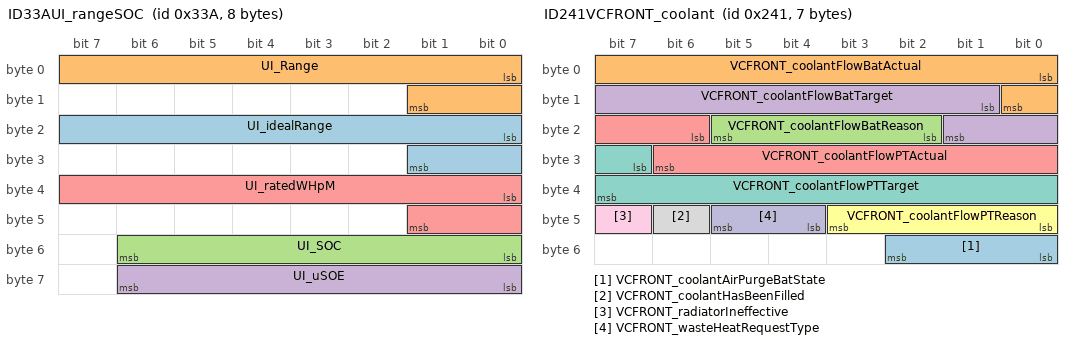
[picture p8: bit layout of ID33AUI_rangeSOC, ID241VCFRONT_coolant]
BO_ 826 ID33AUI_rangeSOC: 8 VehicleBus
   SG_ UI_idealRange : 16|10@1+ (1,0) [0|1023] "mi" Receiver
   SG_ UI_Range : 0|10@1+ (1,0) [0|1023] "mi" Receiver
   SG_ UI_SOC : 48|7@1+ (1,0) [0|127] "%" Receiver
   SG_ UI_uSOE : 56|7@1+ (1,0) [0|127] "%" Receiver
   SG_ UI_ratedWHpM : 32|10@1+ (1,0) [0|1023] "WHpM" Receiver

BO_ 577 ID241VCFRONT_coolant: 7 VehicleBus
   SG_ VCFRONT_coolantAirPurgeBatState : 48|3@1+ (1,0) [0|4] "" Receiver
   SG_ VCFRONT_coolantFlowBatActual : 0|9@1+ (0.1,0) [0|40] "LPM" Receiver
   SG_ VCFRONT_coolantFlowBatReason : 18|4@1+ (1,0) [0|14] "" Receiver
   SG_ VCFRONT_coolantFlowBatTarget : 9|9@1+ (0.1,0) [0|40] "LPM" Receiver
   SG_ VCFRONT_coolantFlowPTActual : 22|9@1+ (0.1,0) [0|40] "LPM" Receiver
   SG_ VCFRONT_coolantFlowPTReason : 40|4@1+ (1,0) [0|14] "" Receiver
   SG_ VCFRONT_coolantFlowPTTarget : 31|9@1+ (0.1,0) [0|40] "LPM" Receiver
   SG_ VCFRONT_coolantHasBeenFilled : 46|1@1+ (1,0) [0|1] "" Receiver
   SG_ VCFRONT_radiatorIneffective : 47|1@1+ (1,0) [0|1] "" Receiver
   SG_ VCFRONT_wasteHeatRequestType : 44|2@1+ (1,0) [0|2] "" Receiver

BO_ 708 ID2C4PCS_logging: 8 VehicleBus
   SG_ PCS_logMessageSelect M : 0|5@1+ (1,0) [0|26] "" Receiver
   SG_ PCS_1V2Max10s m9 : 43|11@1+ (0.001,0) [0|2.047] "V" Receiver
   SG_ PCS_1V2Min10s m9 : 32|11@1+ (0.001,0) [0|2.047] "V" Receiver
   SG_ PCS_1V5Max10s m9 : 19|11@1+ (0.001,0) [0|2.047] "V" Receiver
   SG_ PCS_1V5Min10s m9 : 8|11@1+ (0.001,0) [0|2.047] "V" Receiver
   SG_ PCS_5VNMax10s m9 : 54|10@1+ (0.01,0) [0|10.23] "V" Receiver
   SG_ PCS_acChargeSelfTestState m9 : 7|1@1+ (1,0) [0|1] "" Receiver
   SG_ PCS_chg5VL1Enable m5 : 61|1@1+ (1,0) [0|1] "" Receiver
   SG_ PCS_chgAcpwHeartbeatState m20 : 42|3@1+ (1,0) [0|4] "" Receiver
   SG_ PCS_chgCurrentSensorOutOfBandUs m20 : 32|10@1+ (0.01,0) [0|10.23] "us" Receiver
   SG_ PCS_chgInputFrequencyL1N m4 : 5|12@1+ (0.01,40) [40|80.95] "Hz" Receiver
   SG_ PCS_chgInputFrequencyL2N m4 : 17|12@1+ (0.01,40) [40|80.95] "Hz" Receiver
   SG_ PCS_chgInputFrequencyL3N m4 : 29|12@1+ (0.01,40) [40|80.95] "Hz" Receiver
   SG_ PCS_chgInputL1L2Vdc m21 : 36|10@1- (1,0) [-512|511] "V" Receiver
   SG_ PCS_chgInputL1L2Vrms m3 : 41|12@1+ (0.2,0) [0|819] "V" Receiver
   SG_ PCS_chgInputL1NVdc m21 : 5|10@1- (1,0) [-512|511] "V" Receiver
   SG_ PCS_chgInputL1NVrms m3 : 5|12@1+ (0.2,0) [0|819] "V" Receiver
   SG_ PCS_chgInputL2NVdc m21 : 16|10@1- (1,0) [-512|511] "V" Receiver
   SG_ PCS_chgInputL2NVrms m3 : 17|12@1+ (0.2,0) [0|819] "V" Receiver
   SG_ PCS_chgInputL3NVdc m21 : 26|10@1- (1,0) [-512|511] "V" Receiver
   SG_ PCS_chgInputL3NVrms m3 : 29|12@1+ (0.2,0) [0|819] "V" Receiver
   SG_ PCS_chgInputNGVdc m21 : 46|10@1- (1,0) [-512|511] "V" Receiver
   SG_ PCS_chgInputNGVrms m3 : 53|9@1+ (1,0) [0|511] "V" Receiver
   SG_ PCS_chgInternalPhaseConfig m4 : 41|4@1+ (1,0) [0|9] "" Receiver
   SG_ PCS_chgKwhLostByFreqDroop m20 : 48|8@1+ (0.1,0) [0|25.5] "kWh" Receiver
   SG_ PCS_chgL1L2PllLocked m5 : 57|1@1+ (1,0) [0|1] "" Receiver
   SG_ PCS_chgL1NPllLocked m5 : 54|1@1+ (1,0) [0|1] "" Receiver
   SG_ PCS_chgL2NPllLocked m5 : 55|1@1+ (1,0) [0|1] "" Receiver
   SG_ PCS_chgL3NPllLocked m5 : 56|1@1+ (1,0) [0|1] "" Receiver
   SG_ PCS_chgNgPllLocked m5 : 58|1@1+ (1,0) [0|1] "" Receiver
   SG_ PCS_chgOutputV m4 : 51|12@1+ (0.146484,0) [0|599.854] "V" Receiver
   SG_ PCS_chgPHAInputVPeak10s m13 : 5|9@1+ (1,0) [0|511] "V" Receiver
   SG_ PCS_chgPHBInputVPeak10s m13 : 14|9@1+ (1,0) [0|511] "V" Receiver
   SG_ PCS_chgPHCInputVPeak10s m13 : 23|9@1+ (1,0) [0|511] "V" Receiver
   SG_ PCS_chgPhAInputFreqWobbleCnt m13 : 32|8@1- (1,0) [-128|127] "s" Receiver
   SG_ PCS_chgPhAInputIrms m0 : 5|9@1+ (0.1,0) [0|51.1] "A" Receiver
   SG_ PCS_chgPhAIntBusV m0 : 14|9@1+ (1,0) [0|511] "V" Receiver
   SG_ PCS_chgPhAIntBusVMax10s m10 : 14|9@1+ (1,0) [0|511] "V" Receiver
   SG_ PCS_chgPhAIntBusVMin10s m10 : 5|9@1+ (1,0) [0|511] "V" Receiver
   SG_ PCS_chgPhAIntBusVTarget m0 : 23|9@1+ (1,0) [0|511] "V" Receiver
   SG_ PCS_chgPhALastShutdownReason m5 : 17|5@1+ (1,0) [0|17] "" Receiver
   SG_ PCS_chgPhALifetimekWh m10 : 31|24@1+ (0.01,0) [0|167772] "kWh" Receiver
   SG_ PCS_chgPhAMachineEnabled m23 : 5|1@1+ (1,0) [0|1] "" Receiver
   SG_ PCS_chgPhAMachineRotorFreqDroop m23 : 6|10@1- (0.01,0) [-5.12|5.11] "Hz" Receiver
   SG_ PCS_chgPhAMachineStatorCurrent m23 : 16|8@1- (0.2,0) [-25.6|25.4] "A" Receiver
   SG_ PCS_chgPhANoFlowBucket m20 : 5|9@1+ (0.01,0) [0|5.11] "-" Receiver
   SG_ PCS_chgPhAOutputI m0 : 32|8@1+ (0.1,0) [0|25.5] "A" Receiver
   SG_ PCS_chgPhAPchgVoltDeltaMax10s m10 : 23|8@1+ (0.5,0) [0|127.5] "V" Receiver
   SG_ PCS_chgPhARetryCount m5 : 32|3@1+ (1,0) [0|7] "" Receiver
   SG_ PCS_chgPhAState m5 : 5|4@1+ (1,0) [0|6] "" Receiver
   SG_ PCS_chgPhATransientRetryCount m10 : 55|9@1+ (0.1,0) [0|51.1] "-" Receiver
   SG_ PCS_chgPhBInputFreqWobbleCnt m13 : 40|8@1- (1,0) [-128|127] "s" Receiver
   SG_ PCS_chgPhBInputIrms m1 : 5|9@1+ (0.1,0) [0|51.1] "A" Receiver
   SG_ PCS_chgPhBIntBusV m1 : 14|9@1+ (1,0) [0|511] "V" Receiver
   SG_ PCS_chgPhBIntBusVMax10s m11 : 14|9@1+ (1,0) [0|511] "V" Receiver
   SG_ PCS_chgPhBIntBusVMin10s m11 : 5|9@1+ (1,0) [0|511] "V" Receiver
   SG_ PCS_chgPhBIntBusVTarget m1 : 23|9@1+ (1,0) [0|511] "V" Receiver
   SG_ PCS_chgPhBLastShutdownReason m5 : 22|5@1+ (1,0) [0|17] "" Receiver
   SG_ PCS_chgPhBLifetimekWh m11 : 31|24@1+ (0.01,0) [0|167772] "kWh" Receiver
   SG_ PCS_chgPhBMachineEnabled m23 : 24|1@1+ (1,0) [0|1] "" Receiver
   SG_ PCS_chgPhBMachineRotorFreqDroop m23 : 25|10@1- (0.01,0) [-5.12|5.11] "Hz" Receiver
   SG_ PCS_chgPhBMachineStatorCurrent m23 : 35|8@1- (0.2,0) [-25.6|25.4] "A" Receiver
   SG_ PCS_chgPhBNoFlowBucket m20 : 14|9@1+ (0.01,0) [0|5.11] "-" Receiver
   SG_ PCS_chgPhBOutputI m1 : 32|8@1+ (0.1,0) [0|25.5] "A" Receiver
   SG_ PCS_chgPhBPchgVoltDeltaMax10s m11 : 23|8@1+ (0.5,0) [0|127.5] "V" Receiver
   SG_ PCS_chgPhBRetryCount m5 : 35|3@1+ (1,0) [0|7] "" Receiver
   SG_ PCS_chgPhBState m5 : 9|4@1+ (1,0) [0|6] "" Receiver
   SG_ PCS_chgPhBTransientRetryCount m11 : 55|9@1+ (0.1,0) [0|51.1] "-" Receiver
   SG_ PCS_chgPhCInputFreqWobbleCnt m13 : 48|8@1- (1,0) [-128|127] "s" Receiver
   SG_ PCS_chgPhCInputIrms m2 : 5|9@1+ (0.1,0) [0|51.1] "A" Receiver
   SG_ PCS_chgPhCIntBusV m2 : 14|9@1+ (1,0) [0|511] "V" Receiver
   SG_ PCS_chgPhCIntBusVMax10s m12 : 14|9@1+ (1,0) [0|511] "V" Receiver
   SG_ PCS_chgPhCIntBusVMin10s m12 : 5|9@1+ (1,0) [0|511] "V" Receiver
   SG_ PCS_chgPhCIntBusVTarget m2 : 23|9@1+ (1,0) [0|511] "V" Receiver
   SG_ PCS_chgPhCLastShutdownReason m5 : 27|5@1+ (1,0) [0|17] "" Receiver
   SG_ PCS_chgPhCLifetimekWh m12 : 31|24@1+ (0.01,0) [0|167772] "kWh" Receiver
   SG_ PCS_chgPhCMachineEnabled m23 : 43|1@1+ (1,0) [0|1] "" Receiver
   SG_ PCS_chgPhCMachineRotorFreqDroop m23 : 44|10@1- (0.01,0) [-5.12|5.11] "Hz" Receiver
   SG_ PCS_chgPhCMachineStatorCurrent m23 : 54|8@1- (0.2,0) [-25.6|25.4] "A" Receiver
   SG_ PCS_chgPhCNoFlowBucket m20 : 23|9@1+ (0.01,0) [0|5.11] "-" Receiver
   SG_ PCS_chgPhCOutputI m2 : 32|8@1+ (0.1,0) [0|25.5] "A" Receiver
   SG_ PCS_chgPhCPchgVoltDeltaMax10s m12 : 23|8@1+ (0.5,0) [0|127.5] "V" Receiver
   SG_ PCS_chgPhCRetryCount m5 : 38|3@1+ (1,0) [0|7] "" Receiver
   SG_ PCS_chgPhCState m5 : 13|4@1+ (1,0) [0|6] "" Receiver
   SG_ PCS_chgPhCTransientRetryCount m12 : 55|9@1+ (0.1,0) [0|51.1] "-" Receiver
   SG_ PCS_chgPhManCurrentToDist m5 : 44|10@1+ (0.1,0) [0|100] "A" Receiver
   SG_ PCS_chgPhManOptimalPhsToUse m5 : 59|2@1+ (1,0) [0|3] "" Receiver
   SG_ PCS_chgPhasesPriority m4 : 45|6@1+ (1,0) [0|36] "" Receiver
   SG_ PCS_chgPwmEnableLineErrorCount m22 : 32|10@1+ (1,0) [0|1023] "" Receiver
   SG_ PCS_chgReqKwhLostByFreqDroop m20 : 56|8@1+ (0.1,0) [0|25.5] "kWh" Receiver
   SG_ PCS_chgRetryCount m5 : 41|3@1+ (1,0) [0|7] "" Receiver
   SG_ PCS_cpu2BootState m9 : 5|2@1+ (1,0) [0|3] "" Receiver
   SG_ PCS_dLogPhAChannel1Content m14 : 5|2@1+ (1,0) [0|3] "" Receiver
   SG_ PCS_dLogPhAChannel1Data m14 : 16|16@1- (0.02,0) [-655.36|655.34] "-" Receiver
   SG_ PCS_dLogPhAChannel2Content m15 : 5|2@1+ (1,0) [0|3] "" Receiver
   SG_ PCS_dLogPhAChannel2Data m15 : 16|16@1- (0.02,0) [-655.36|655.34] "-" Receiver
   SG_ PCS_dLogPhAChannel3Content m16 : 5|2@1+ (1,0) [0|3] "" Receiver
   SG_ PCS_dLogPhAChannel3Data m16 : 16|16@1- (0.02,0) [-655.36|655.34] "-" Receiver
   SG_ PCS_dLogPhAChannel4Content m17 : 5|2@1+ (1,0) [0|3] "" Receiver
   SG_ PCS_dLogPhAChannel4Data m17 : 16|16@1- (0.02,0) [-655.36|655.34] "-" Receiver
   SG_ PCS_dLogPhBChannel1Content m14 : 8|2@1+ (1,0) [0|3] "" Receiver
   SG_ PCS_dLogPhBChannel1Data m14 : 32|16@1- (0.02,0) [-655.36|655.34] "-" Receiver
   SG_ PCS_dLogPhBChannel2Content m15 : 8|2@1+ (1,0) [0|3] "" Receiver
   SG_ PCS_dLogPhBChannel2Data m15 : 32|16@1- (0.02,0) [-655.36|655.34] "-" Receiver
   SG_ PCS_dLogPhBChannel3Content m16 : 8|2@1+ (1,0) [0|3] "" Receiver
   SG_ PCS_dLogPhBChannel3Data m16 : 32|16@1- (0.02,0) [-655.36|655.34] "-" Receiver
   SG_ PCS_dLogPhBChannel4Content m17 : 8|2@1+ (1,0) [0|3] "" Receiver
   SG_ PCS_dLogPhBChannel4Data m17 : 32|16@1- (0.02,0) [-655.36|655.34] "-" Receiver
   SG_ PCS_dLogPhCChannel1Content m14 : 10|2@1+ (1,0) [0|3] "" Receiver
   SG_ PCS_dLogPhCChannel1Data m14 : 48|16@1- (0.02,0) [-655.36|655.34] "-" Receiver
   SG_ PCS_dLogPhCChannel2Content m15 : 10|2@1+ (1,0) [0|3] "" Receiver
   SG_ PCS_dLogPhCChannel2Data m15 : 48|16@1- (0.02,0) [-655.36|655.34] "-" Receiver
   SG_ PCS_dLogPhCChannel3Content m16 : 10|2@1+ (1,0) [0|3] "" Receiver
   SG_ PCS_dLogPhCChannel3Data m16 : 48|16@1- (0.02,0) [-655.36|655.34] "-" Receiver
   SG_ PCS_dLogPhCChannel4Content m17 : 10|2@1+ (1,0) [0|3] "" Receiver
   SG_ PCS_dLogPhCChannel4Data m17 : 48|16@1- (0.02,0) [-655.36|655.34] "-" Receiver
   SG_ PCS_dcdc12vSupportLifetimekWh m22 : 8|24@1+ (0.01,0) [0|167772] "kWh" Receiver
   SG_ PCS_dcdcCLAControllerOutput m7 : 16|10@1+ (0.001,0) [0|1] "1" Receiver
   SG_ PCS_dcdcClaCurrentFreq m7 : 48|12@1+ (0.0976563,0) [0|399.9] "kHz" Receiver
   SG_ PCS_dcdcCurrentLimit m6 : 20|12@1+ (0.1,0) [0|400] "A" Receiver
   SG_ PCS_dcdcHalfPeriodUs m8 : 40|16@1+ (0.000488281,0) [0|31.9995] "us" Receiver
   SG_ PCS_dcdcHvBusEstimated_C_uF m25 : 5|10@1+ (7.82014,0) [0|8000] "uF" Receiver
   SG_ PCS_dcdcHvBusEstimated_R_kOhm m25 : 16|10@1+ (0.0488759,0) [0|50] "kOhm" Receiver
   SG_ PCS_dcdcIntervalMaxFrequency m18 : 8|12@1+ (1,0) [0|400] "kHz" Receiver
   SG_ PCS_dcdcIntervalMaxHvBusVolt m18 : 24|13@1+ (0.1,0) [0|600] "V" Receiver
   SG_ PCS_dcdcIntervalMaxLvBusVolt m18 : 37|9@1+ (0.1,0) [0|40] "V" Receiver
   SG_ PCS_dcdcIntervalMaxLvOutputCurr m18 : 48|12@1+ (1,0) [0|400] "A" Receiver
   SG_ PCS_dcdcIntervalMinFrequency m19 : 8|12@1+ (1,0) [0|400] "kHz" Receiver
   SG_ PCS_dcdcIntervalMinHvBusVolt m19 : 24|13@1+ (0.1,0) [0|600] "V" Receiver
   SG_ PCS_dcdcIntervalMinLvBusVolt m19 : 37|9@1+ (0.1,0) [0|40] "V" Receiver
   SG_ PCS_dcdcIntervalMinLvOutputCurr m19 : 48|12@1+ (1,0) [0|400] "A" Receiver
   SG_ PCS_dcdcLvOutputCurrentTempLimit m6 : 32|12@1+ (0.1,0) [0|400] "A" Receiver
   SG_ PCS_dcdcMaxLvOutputCurrent m6 : 8|12@1+ (0.1,0) [0|400] "A" Receiver
   SG_ PCS_dcdcPchgStartHvBusVolt m24 : 16|12@1+ (0.146484,0) [0|599.854] "V" Receiver
   SG_ PCS_dcdcPchgStartLvBusVolt m24 : 5|10@1+ (0.0390625,0) [0|39.9609] "V" Receiver
   SG_ PCS_dcdcPwmEnableLineErrorCount m22 : 42|10@1+ (1,0) [0|1023] "" Receiver
   SG_ PCS_dcdcShortTimeUs m8 : 24|16@1+ (0.000488281,0) [0|31.9995] "us" Receiver
   SG_ PCS_dcdcTCommMeasured m8 : 8|16@1- (0.00195313,0) [-64|63.998] "us" Receiver
   SG_ PCS_dcdcTankVoltage m7 : 26|11@1- (1,0) [-1024|1023] "V" Receiver
   SG_ PCS_dcdcTankVoltageTarget m7 : 37|10@1+ (1,0) [0|1023] "V" Receiver
   SG_ PCS_dcdcUnifiedCommand m7 : 5|10@1+ (0.001,0) [0|1] "1" Receiver
   SG_ PCS_numAlertsSet m22 : 56|7@1+ (1,0) [0|127] "" Receiver

BO_ 955 ID3BBUI_power: 2 VehicleBus
   SG_ UI_powerExpected : 0|8@1+ (1,0) [0|100] "kW" Receiver
   SG_ UI_powerIdeal : 8|8@1+ (1,0) [0|100] "kW" Receiver

BO_ 1493 ID5D5RearDItemps: 5 VehicleBus
   SG_ DI_ph1Temp : 0|8@1+ (1,-40) [-40|120] "C" Receiver
   SG_ DI_ph2Temp : 8|8@1+ (1,-40) [-40|120] "C" Receiver
   SG_ DI_ph3Temp : 16|8@1+ (1,-40) [-40|120] "C" Receiver
   SG_ DI_pcbTemp2 : 24|8@1+ (1,-40) [-40|150] "C" Receiver
   SG_ DI_IGBTJunctTemp : 32|8@1+ (1,-40) [-40|200] "C" Receiver
   SG_ DI_lashAngle : 40|10@1+ (0.06,0) [0|60] "Deg" Receiver
   SG_ DI_lashCheckCount : 50|6@1+ (1,0) [0|63] "" Receiver
   SG_ DI_torqueWearTotal : 56|8@1+ (0.02,0) [0|5.08] "1" Receiver

BO_ 1366 ID556FrontDItemps: 5 VehicleBus
   SG_ DIF_ph1Temp : 0|8@1+ (1,-40) [-40|120] "C" Receiver
   SG_ DIF_ph2Temp : 8|8@1+ (1,-40) [-40|120] "C" Receiver
   SG_ DIF_ph3Temp : 16|8@1+ (1,-40) [-40|120] "C" Receiver
   SG_ DIF_pcbTemp2 : 24|8@1+ (1,-40) [-40|150] "C" Receiver
   SG_ DIF_IGBTJunctTemp : 32|8@1+ (1,-40) [-40|200] "C" Receiver
   SG_ DIF_lashAngle : 40|10@1+ (0.06,0) [0|60] "Deg" Receiver
   SG_ DIF_lashCheckCount : 50|6@1+ (1,0) [0|63] "" Receiver
   SG_ DIF_torqueWearTotal : 56|8@1+ (0.02,0) [0|5.08] "1" Receiver

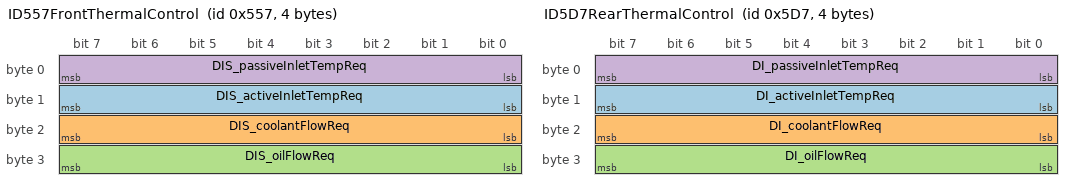
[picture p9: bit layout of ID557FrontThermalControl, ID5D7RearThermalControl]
BO_ 1367 ID557FrontThermalControl: 4 VehicleBus
   SG_ DIS_activeInletTempReq : 8|8@1+ (1,-40) [-40|120] "C" Receiver
   SG_ DIS_coolantFlowReq : 16|8@1+ (0.2,0) [0|50] "LPM" Receiver
   SG_ DIS_oilFlowReq : 24|8@1+ (0.06,0) [0|15] "LPM" Receiver
   SG_ DIS_passiveInletTempReq : 0|8@1+ (1,-40) [-40|120] "C" Receiver

BO_ 1495 ID5D7RearThermalControl: 4 VehicleBus
   SG_ DI_activeInletTempReq : 8|8@1+ (1,-40) [-40|120] "C" Receiver
   SG_ DI_coolantFlowReq : 16|8@1+ (0.2,0) [0|50] "LPM" Receiver
   SG_ DI_oilFlowReq : 24|8@1+ (0.06,0) [0|15] "LPM" Receiver
   SG_ DI_passiveInletTempReq : 0|8@1+ (1,-40) [-40|120] "C" Receiver

BO_ 2005 ID7D5DIR_debug: 8 VehicleBus
   SG_ DIR_debugSelector M : 0|8@1+ (1,0) [0|255] "" Receiver
   SG_ DIR_aebCancelReason m45 : 32|8@1+ (1,0) [0|255] "" Receiver
   SG_ DIR_aebFaultReason m45 : 16|4@1+ (1,0) [0|15] "" Receiver
   SG_ DIR_aebUnavailableReason m45 : 24|4@1+ (1,0) [0|10] "" Receiver
   SG_ DIR_brakeCpScale m2 : 16|9@1- (0.01,0.5) [-1|2] "N/N" Receiver
   SG_ DIR_brakeSwitchNC m42 : 63|1@1+ (1,0) [0|1] "" Receiver
   SG_ DIR_brakeSwitchNO m42 : 62|1@1+ (1,0) [0|1] "" Receiver
   SG_ DIR_brkStState m50 : 24|3@1+ (1,0) [0|6] "" Receiver
   SG_ DIR_busbarTemp m64 : 16|8@1+ (1,-40) [-40|215] "C" Receiver
   SG_ DIR_controlStack m67 : 56|8@1+ (0.4,0) [0|100] "%" Receiver
   SG_ DIR_cpu100HzAvg m66 : 48|8@1+ (0.4,0) [0|102] "%" Receiver
   SG_ DIR_cpu100HzMax m66 : 40|8@1+ (0.4,0) [0|102] "%" Receiver
   SG_ DIR_cpu100HzMin m66 : 32|8@1+ (0.4,0) [0|102] "%" Receiver
   SG_ DIR_cpu10HzAvg m66 : 24|8@1+ (0.4,0) [0|102] "%" Receiver
   SG_ DIR_cpu10HzMax m66 : 16|8@1+ (0.4,0) [0|102] "%" Receiver
   SG_ DIR_cpu10HzMin m66 : 8|8@1+ (0.4,0) [0|102] "%" Receiver
   SG_ DIR_cpu1HzAvg m128 : 32|8@1+ (0.4,0) [0|102] "%" Receiver
   SG_ DIR_cpu1HzMax m128 : 24|8@1+ (0.4,0) [0|102] "%" Receiver
   SG_ DIR_cpu1HzMin m128 : 16|8@1+ (0.4,0) [0|102] "%" Receiver
   SG_ DIR_cpu1kHzAvg m67 : 24|8@1+ (0.4,0) [0|102] "%" Receiver
   SG_ DIR_cpu1kHzMax m67 : 16|8@1+ (0.4,0) [0|102] "%" Receiver
   SG_ DIR_cpu1kHzMin m67 : 8|8@1+ (0.4,0) [0|102] "%" Receiver
   SG_ DIR_cpu20kHzAvg m67 : 48|8@1+ (0.4,0) [0|102] "%" Receiver
   SG_ DIR_cpu20kHzMax m67 : 40|8@1+ (0.4,0) [0|102] "%" Receiver
   SG_ DIR_cpu20kHzMin m67 : 32|8@1+ (0.4,0) [0|102] "%" Receiver
   SG_ DIR_cpuIDWord0 m131 : 16|16@1+ (1,0) [0|65535] "" Receiver
   SG_ DIR_cpuIDWord1 m132 : 16|16@1+ (1,0) [0|65535] "" Receiver
   SG_ DIR_cpuIDWord2 m132 : 32|16@1+ (1,0) [0|65535] "" Receiver
   SG_ DIR_cpuIDWord3 m132 : 48|16@1+ (1,0) [0|65535] "" Receiver
   SG_ DIR_crc m131 : 32|32@1+ (1,0) [0|4.29497e+09] "" Receiver
   SG_ DIR_currentLimit m41 : 32|16@1+ (0.1,0) [0|6553.5] "A" Receiver
   SG_ DIR_dcCableCurrentEst m37 : 16|16@1- (0.1,0) [-3276.8|3276.7] "A" Receiver
   SG_ DIR_dcCableHeat m47 : 32|16@1+ (0.001,0) [0|65.535] "kA2s" Receiver
   SG_ DIR_dcCapTemp m64 : 8|8@1+ (1,-40) [-40|215] "C" Receiver
   SG_ DIR_dcLinkCapTemp m70 : 32|8@1+ (1,-40) [-40|215] "C" Receiver
   SG_ DIR_decodeHardwareStack m68 : 24|8@1+ (0.4,0) [0|100] "%" Receiver
   SG_ DIR_driveUnitOdometer m69 : 32|32@1+ (10,0) [0|4.29497e+10] "rev" Receiver
   SG_ DIR_eepromStack m68 : 32|8@1+ (0.4,0) [0|100] "%" Receiver
   SG_ DIR_fluxState m42 : 16|4@1+ (1,0) [0|10] "" Receiver
   SG_ DIR_gainScale m37 : 8|8@1+ (0.01,0) [0|2.55] "scale" Receiver
   SG_ DIR_gateDriveState m50 : 10|3@1+ (1,0) [0|4] "" Receiver
   SG_ DIR_gateDriveSupplyState m50 : 8|2@1+ (1,0) [0|3] "" Receiver
   SG_ DIR_hvDcCableTemp m70 : 40|8@1+ (1,-40) [-40|215] "C" Receiver
   SG_ DIR_hwFaultCount m69 : 8|4@1+ (1,0) [0|15] "" Receiver
   SG_ DIR_idleStack m68 : 16|8@1+ (0.4,0) [0|100] "%" Receiver
   SG_ DIR_immobilizerCondition m64 : 63|1@1+ (1,0) [0|1] "" Receiver
   SG_ DIR_immobilizerStack m68 : 56|8@1+ (0.4,0) [0|100] "%" Receiver
   SG_ DIR_internalAngleFilt m37 : 48|16@1+ (0.0003,0) [0|8] "rad" Receiver
   SG_ DIR_llrScale m42 : 32|8@1+ (0.015,0) [0|3.825] "scale" Receiver
   SG_ DIR_llsScale m42 : 24|8@1+ (0.004,0) [0|1.02] "scale" Receiver
   SG_ DIR_lmScale m36 : 8|8@1+ (0.004,0) [0|1.02] "scale" Receiver
   SG_ DIR_loadAngle m42 : 40|16@1- (0.0003,0) [-4|4] "rad" Receiver
   SG_ DIR_loadAngleMargin m37 : 32|16@1- (0.0003,0) [-4|4] "rad" Receiver
   SG_ DIR_locCheckSpeedRef m75 : 54|8@1+ (1,0) [0|250] "kph" Receiver
   SG_ DIR_locFeedFwTrq m75 : 44|10@1- (10,0) [-5000|5000] "Nm" Receiver
   SG_ DIR_locTargetAccel m75 : 8|8@1- (0.08,-4.72) [-15|5.4] "m/s^2" Receiver
   SG_ DIR_locTargetSpeed m75 : 16|8@1+ (1,0) [0|250] "kph" Receiver
   SG_ DIR_locUi m75 : 34|10@1- (10,0) [-5000|5000] "Nm" Receiver
   SG_ DIR_locUp m75 : 24|10@1- (10,0) [-5000|5000] "Nm" Receiver
   SG_ DIR_magnetTempEst m47 : 48|8@1+ (1,-40) [-40|180] "C" Receiver
   SG_ DIR_module10HzStack m66 : 56|8@1+ (0.4,0) [0|100] "%" Receiver
   SG_ DIR_motorIA m32 : 16|16@1+ (0.1,0) [0|6553.5] "A" Receiver
   SG_ DIR_motorIAavg m38 : 32|16@1- (0.1,0) [-3276.8|3276.7] "A" Receiver
   SG_ DIR_motorIB m32 : 32|16@1+ (0.1,0) [0|6553.5] "A" Receiver
   SG_ DIR_motorIBavg m38 : 48|16@1- (0.1,0) [-3276.8|3276.7] "A" Receiver
   SG_ DIR_motorIC m32 : 48|16@1+ (0.1,0) [0|6553.5] "A" Receiver
   SG_ DIR_motorType m128 : 8|5@1+ (1,0) [0|28] "" Receiver
   SG_ DIR_motorV m34 : 48|16@1+ (2e-05,0) [0|1.3107] "mindex" Receiver
   SG_ DIR_muSurfHigh m2 : 8|8@1+ (0.005,0) [0|1.2] "N/N" Receiver
   SG_ DIR_negDcBusbarTemp m70 : 48|8@1+ (1,-40) [-40|215] "C" Receiver
   SG_ DIR_offsetA m32 : 8|8@1- (0.1,0) [-12.8|12.7] "A" Receiver
   SG_ DIR_offsetB m33 : 8|8@1- (0.1,0) [-12.8|12.7] "A" Receiver
   SG_ DIR_oilPumpMotorSpeed m46 : 8|8@1+ (40,0) [0|10200] "RPM" Receiver
   SG_ DIR_oilPumpPhaseVoltage m46 : 16|8@1+ (0.1,0) [0|25.4] "V" Receiver
   SG_ DIR_oilPumpPressureEstimateMax m46 : 24|8@1+ (2,0) [0|500] "kPa" Receiver
   SG_ DIR_oilPumpPressureExpectedMin m46 : 32|8@1+ (2,0) [0|500] "kPa" Receiver
   SG_ DIR_opdUnavailableReason m45 : 40|4@1+ (1,0) [0|15] "" Receiver
   SG_ DIR_pcsTemp m64 : 24|8@1+ (1,-40) [-40|215] "C" Receiver
   SG_ DIR_peakFlux m36 : 48|16@1+ (0.0001,0) [0|6.5535] "Wb" Receiver
   SG_ DIR_peakIQref m38 : 16|16@1+ (0.1,0) [0|6553.5] "A" Receiver
   SG_ DIR_pedalPosFilt m2 : 32|8@1+ (0.4,0) [0|100] "%" Receiver
   SG_ DIR_phaseOutBusbarTemp m70 : 8|8@1+ (1,-40) [-40|215] "C" Receiver
   SG_ DIR_phaseOutBusbarWeldTemp m70 : 16|8@1+ (1,-40) [-40|215] "C" Receiver
   SG_ DIR_phaseOutLugTemp m70 : 24|8@1+ (1,-40) [-40|215] "C" Receiver
   SG_ DIR_posDcBusbarTemp m70 : 56|8@1+ (1,-40) [-40|215] "C" Receiver
   SG_ DIR_powerStageSafeState m50 : 13|2@1+ (1,0) [0|3] "" Receiver
   SG_ DIR_pwrSatChargeCurrent m42 : 8|8@1+ (0.4,0) [0|102] "%" Receiver
   SG_ DIR_pwrSatDischargeCurrent m40 : 8|8@1+ (0.4,0) [0|102] "%" Receiver
   SG_ DIR_pwrSatMaxBusVoltage m39 : 48|8@1+ (0.4,0) [0|102] "%" Receiver
   SG_ DIR_pwrSatMaxDischargePower m39 : 16|8@1+ (0.4,0) [0|102] "%" Receiver
   SG_ DIR_pwrSatMaxRegenPower m39 : 24|8@1+ (0.4,0) [0|102] "%" Receiver
   SG_ DIR_pwrSatMinBusVoltage m39 : 56|8@1+ (0.4,0) [0|102] "%" Receiver
   SG_ DIR_resolverClaMIA m48 : 43|1@1+ (1,0) [0|1] "" Receiver
   SG_ DIR_resolverCommonGain m48 : 32|8@1+ (0.025,0) [0|5] "1" Receiver
   SG_ DIR_resolverCosFiltered m52 : 32|8@1- (0.01,0) [-1|1] "1" Receiver
   SG_ DIR_resolverCosRmsSquared m52 : 16|8@1+ (0.005,0) [0|1] "1" Receiver
   SG_ DIR_resolverErrorRmsSquared m52 : 48|8@1+ (0.005,0) [0|1] "1" Receiver
   SG_ DIR_resolverNoCarrier m48 : 41|1@1+ (1,0) [0|1] "" Receiver
   SG_ DIR_resolverNoPhaseLock m48 : 42|1@1+ (1,0) [0|1] "" Receiver
   SG_ DIR_resolverOffsetCos m48 : 8|8@1+ (0.015,0) [0|3.3] "V" Receiver
   SG_ DIR_resolverOffsetSin m48 : 16|8@1+ (0.015,0) [0|3.3] "V" Receiver
   SG_ DIR_resolverPhaseOffset m48 : 24|8@1+ (0.1,7.5) [7.5|32.5] "us" Receiver
   SG_ DIR_resolverReady m48 : 40|1@1+ (1,0) [0|1] "" Receiver
   SG_ DIR_resolverSinFiltered m52 : 40|8@1- (0.01,0) [-1|1] "1" Receiver
   SG_ DIR_resolverSinRmsSquared m52 : 24|8@1+ (0.005,0) [0|1] "1" Receiver
   SG_ DIR_rotorFlux m47 : 16|16@1+ (0.0001,0) [0|6.5535] "Wb" Receiver
   SG_ DIR_rotorMaxMagnetTemp m72 : 16|8@1+ (1,-40) [-40|215] "C" Receiver
   SG_ DIR_rotorOffsetEst m43 : 8|12@1- (0.01,0) [-20|20] "deg" Receiver
   SG_ DIR_rotorOffsetLearningState m63 : 8|4@1+ (1,0) [0|9] "" Receiver
   SG_ DIR_rotorOffsetMean m43 : 20|12@1- (0.01,0) [-20|20] "deg" Receiver
   SG_ DIR_rsScale m34 : 8|8@1+ (0.01,0) [0|2.55] "scale" Receiver
   SG_ DIR_soptMaxCurrentMagSqrd m49 : 40|16@1+ (100,0) [0|6.5535e+06] "A2" Receiver
   SG_ DIR_soptTimeToOff m49 : 24|11@1+ (0.05,0) [0|100] "ms" Receiver
   SG_ DIR_soptTimeToTrip m49 : 8|8@1+ (0.05,0) [0|10] "ms" Receiver
   SG_ DIR_soptTripDelay m49 : 16|8@1+ (0.05,0) [0|10] "ms" Receiver
   SG_ DIR_ssmState m38 : 8|4@1+ (1,0) [0|8] "" Receiver
   SG_ DIR_statorEndWindingTemp m72 : 8|8@1+ (1,-40) [-40|215] "C" Receiver
   SG_ DIR_statorFluxFdb m35 : 32|16@1+ (0.0001,0) [0|6.5535] "Wb" Receiver
   SG_ DIR_statorFluxRef m35 : 16|16@1+ (0.0001,0) [0|6.5535] "Wb" Receiver
   SG_ DIR_statorIDfdb m33 : 32|16@1- (0.1,0) [-3276.8|3276.7] "A" Receiver
   SG_ DIR_statorIDref m33 : 16|16@1- (0.1,0) [-3276.8|3276.7] "A" Receiver
   SG_ DIR_statorIQfdb m34 : 32|16@1- (0.1,0) [-3276.8|3276.7] "A" Receiver
   SG_ DIR_statorIQref m34 : 16|16@1- (0.1,0) [-3276.8|3276.7] "A" Receiver
   SG_ DIR_statorTemp1 m64 : 32|8@1+ (1,-40) [-40|215] "C" Receiver
   SG_ DIR_statorTemp2 m64 : 40|8@1+ (1,-40) [-40|215] "C" Receiver
   SG_ DIR_statorVD m36 : 32|16@1- (4e-05,0) [-1.31072|1.31068] "mindex" Receiver
   SG_ DIR_statorVDFiltered m63 : 16|16@1- (4e-05,0) [-1.31072|1.31068] "mindex" Receiver
   SG_ DIR_statorVQ m36 : 16|16@1- (4e-05,0) [-1.31072|1.31068] "mindex" Receiver
   SG_ DIR_statorVQFiltered m63 : 32|16@1- (4e-05,0) [-1.31072|1.31068] "mindex" Receiver
   SG_ DIR_sysHeatPowerOptimal m50 : 16|8@1+ (0.08,0) [0|20] "kW" Receiver
   SG_ DIR_sysPedalMaxTorque m44 : 22|14@1+ (0.1,0) [0|1638.3] "Nm" Receiver
   SG_ DIR_sysPedalMinTorque m44 : 8|14@1+ (0.1,-1638.3) [-1638.3|0] "Nm" Receiver
   SG_ DIR_sysPostPedalMaxTorque m44 : 50|14@1+ (0.1,0) [0|1638.3] "Nm" Receiver
   SG_ DIR_sysPostPedalMinTorque m44 : 36|14@1+ (0.1,-1638.3) [-1638.3|0] "Nm" Receiver
   SG_ DIR_systemStack m68 : 8|8@1+ (0.4,0) [0|100] "%" Receiver
   SG_ DIR_systemTorqueCommand m35 : 48|16@1- (0.035,0) [-1146.88|1146.85] "Nm" Receiver
   SG_ DIR_tcMaxRequest m40 : 16|8@1+ (5,0) [0|1275] "Nm" Receiver
   SG_ DIR_tcMinRequest m40 : 24|8@1+ (5,0) [0|1275] "Nm" Receiver
   SG_ DIR_torquePerAmp m33 : 48|16@1+ (0.0001,0) [0|6.5535] "Nm/A" Receiver
   SG_ DIR_tqSatMotorCurrent m39 : 40|8@1+ (0.4,0) [0|102] "%" Receiver
   SG_ DIR_tqSatMotorVoltage m39 : 32|8@1+ (0.4,0) [0|102] "%" Receiver
   SG_ DIR_tqSatThermal m39 : 8|8@1+ (0.4,0) [0|102] "%" Receiver
   SG_ DIR_tqSatUiDriveTorque m40 : 32|8@1+ (0.4,0) [0|102] "%" Receiver
   SG_ DIR_tqSatUiRegenTorque m40 : 40|8@1+ (0.4,0) [0|102] "%" Receiver
   SG_ DIR_tqScaleDifferential m35 : 8|8@1+ (0.4,0) [0|102] "%" Receiver
   SG_ DIR_tqScaleMaxMotorSpeed m40 : 48|8@1+ (0.4,0) [0|102] "%" Receiver
   SG_ DIR_tqScaleShift m40 : 56|8@1+ (0.4,0) [0|102] "%" Receiver
   SG_ DIR_udsStack m68 : 40|8@1+ (0.4,0) [0|100] "%" Receiver
   SG_ DIR_usmState m38 : 12|3@1+ (1,0) [0|7] "" Receiver
   SG_ DIR_veMassInvRaw m41 : 8|12@1+ (1e-07,0.0001) [0.0001|0.0005] "1/kg" Receiver
   SG_ DIR_veResForce m41 : 20|12@1- (0.0005,0) [-1.024|1.0235] "G" Receiver
   SG_ DIR_velocityEstimatorState m65 : 8|3@1+ (1,0) [0|4] "" Receiver
   SG_ DIR_wasteCurrentLimit m41 : 48|16@1+ (0.1,0) [0|6553.5] "A" Receiver
   SG_ DIR_xcpStack m68 : 48|8@1+ (0.4,0) [0|100] "%" Receiver

BO_ 1879 ID757DIF_debug: 8 VehicleBus
   SG_ DIF_debugSelector M : 0|8@1+ (1,0) [0|255] "" Receiver
   SG_ DIF_aebCancelReason m45 : 32|8@1+ (1,0) [0|255] "" Receiver
   SG_ DIF_aebFaultReason m45 : 16|4@1+ (1,0) [0|15] "" Receiver
   SG_ DIF_aebUnavailableReason m45 : 24|4@1+ (1,0) [0|10] "" Receiver
   SG_ DIF_brakeCpScale m2 : 16|9@1- (0.01,0.5) [-1|2] "N/N" Receiver
   SG_ DIF_brakeSwitchNC m42 : 63|1@1+ (1,0) [0|1] "" Receiver
   SG_ DIF_brakeSwitchNO m42 : 62|1@1+ (1,0) [0|1] "" Receiver
   SG_ DIF_brkStState m50 : 24|3@1+ (1,0) [0|6] "" Receiver
   SG_ DIF_busbarTemp m64 : 16|8@1+ (1,-40) [-40|215] "C" Receiver
   SG_ DIF_controlStack m67 : 56|8@1+ (0.4,0) [0|100] "%" Receiver
   SG_ DIF_cpu100HzAvg m66 : 48|8@1+ (0.4,0) [0|102] "%" Receiver
   SG_ DIF_cpu100HzMax m66 : 40|8@1+ (0.4,0) [0|102] "%" Receiver
   SG_ DIF_cpu100HzMin m66 : 32|8@1+ (0.4,0) [0|102] "%" Receiver
   SG_ DIF_cpu10HzAvg m66 : 24|8@1+ (0.4,0) [0|102] "%" Receiver
   SG_ DIF_cpu10HzMax m66 : 16|8@1+ (0.4,0) [0|102] "%" Receiver
   SG_ DIF_cpu10HzMin m66 : 8|8@1+ (0.4,0) [0|102] "%" Receiver
   SG_ DIF_cpu1HzAvg m128 : 32|8@1+ (0.4,0) [0|102] "%" Receiver
   SG_ DIF_cpu1HzMax m128 : 24|8@1+ (0.4,0) [0|102] "%" Receiver
   SG_ DIF_cpu1HzMin m128 : 16|8@1+ (0.4,0) [0|102] "%" Receiver
   SG_ DIF_cpu1kHzAvg m67 : 24|8@1+ (0.4,0) [0|102] "%" Receiver
   SG_ DIF_cpu1kHzMax m67 : 16|8@1+ (0.4,0) [0|102] "%" Receiver
   SG_ DIF_cpu1kHzMin m67 : 8|8@1+ (0.4,0) [0|102] "%" Receiver
   SG_ DIF_cpu20kHzAvg m67 : 48|8@1+ (0.4,0) [0|102] "%" Receiver
   SG_ DIF_cpu20kHzMax m67 : 40|8@1+ (0.4,0) [0|102] "%" Receiver
   SG_ DIF_cpu20kHzMin m67 : 32|8@1+ (0.4,0) [0|102] "%" Receiver
   SG_ DIF_cpuIDWord0 m131 : 16|16@1+ (1,0) [0|65535] "" Receiver
   SG_ DIF_cpuIDWord1 m132 : 16|16@1+ (1,0) [0|65535] "" Receiver
   SG_ DIF_cpuIDWord2 m132 : 32|16@1+ (1,0) [0|65535] "" Receiver
   SG_ DIF_cpuIDWord3 m132 : 48|16@1+ (1,0) [0|65535] "" Receiver
   SG_ DIF_crc m131 : 32|32@1+ (1,0) [0|4.29497e+09] "" Receiver
   SG_ DIF_currentLimit m41 : 32|16@1+ (0.1,0) [0|6553.5] "A" Receiver
   SG_ DIF_dcCableCurrentEst m37 : 16|16@1- (0.1,0) [-3276.8|3276.7] "A" Receiver
   SG_ DIF_dcCableHeat m47 : 32|16@1+ (0.001,0) [0|65.535] "kA2s" Receiver
   SG_ DIF_dcCapTemp m64 : 8|8@1+ (1,-40) [-40|215] "C" Receiver
   SG_ DIF_dcLinkCapTemp m70 : 32|8@1+ (1,-40) [-40|215] "C" Receiver
   SG_ DIF_decodeHardwareStack m68 : 24|8@1+ (0.4,0) [0|100] "%" Receiver
   SG_ DIF_driveUnitOdometer m69 : 32|32@1+ (10,0) [0|4.29497e+10] "rev" Receiver
   SG_ DIF_eepromStack m68 : 32|8@1+ (0.4,0) [0|100] "%" Receiver
   SG_ DIF_fluxState m42 : 16|4@1+ (1,0) [0|10] "" Receiver
   SG_ DIF_gainScale m37 : 8|8@1+ (0.01,0) [0|2.55] "scale" Receiver
   SG_ DIF_gateDriveState m50 : 10|3@1+ (1,0) [0|4] "" Receiver
   SG_ DIF_gateDriveSupplyState m50 : 8|2@1+ (1,0) [0|3] "" Receiver
   SG_ DIF_hvDcCableTemp m70 : 40|8@1+ (1,-40) [-40|215] "C" Receiver
   SG_ DIF_hwFaultCount m69 : 8|4@1+ (1,0) [0|15] "" Receiver
   SG_ DIF_idleStack m68 : 16|8@1+ (0.4,0) [0|100] "%" Receiver
   SG_ DIF_immobilizerCondition m64 : 63|1@1+ (1,0) [0|1] "" Receiver
   SG_ DIF_immobilizerStack m68 : 56|8@1+ (0.4,0) [0|100] "%" Receiver
   SG_ DIF_internalAngleFilt m37 : 48|16@1+ (0.0003,0) [0|8] "rad" Receiver
   SG_ DIF_llrScale m42 : 32|8@1+ (0.015,0) [0|3.825] "scale" Receiver
   SG_ DIF_llsScale m42 : 24|8@1+ (0.004,0) [0|1.02] "scale" Receiver
   SG_ DIF_lmScale m36 : 8|8@1+ (0.004,0) [0|1.02] "scale" Receiver
   SG_ DIF_loadAngle m42 : 40|16@1- (0.0003,0) [-4|4] "rad" Receiver
   SG_ DIF_loadAngleMargin m37 : 32|16@1- (0.0003,0) [-4|4] "rad" Receiver
   SG_ DIF_locCheckSpeedRef m75 : 54|8@1+ (1,0) [0|250] "kph" Receiver
   SG_ DIF_locFeedFwTrq m75 : 44|10@1- (10,0) [-5000|5000] "Nm" Receiver
   SG_ DIF_locTargetAccel m75 : 8|8@1- (0.08,-4.72) [-15|5.4] "m/s^2" Receiver
   SG_ DIF_locTargetSpeed m75 : 16|8@1+ (1,0) [0|250] "kph" Receiver
   SG_ DIF_locUi m75 : 34|10@1- (10,0) [-5000|5000] "Nm" Receiver
   SG_ DIF_locUp m75 : 24|10@1- (10,0) [-5000|5000] "Nm" Receiver
   SG_ DIF_magnetTempEst m47 : 48|8@1+ (1,-40) [-40|180] "C" Receiver
   SG_ DIF_module10HzStack m66 : 56|8@1+ (0.4,0) [0|100] "%" Receiver
   SG_ DIF_motorIA m32 : 16|16@1+ (0.1,0) [0|6553.5] "A" Receiver
   SG_ DIF_motorIAavg m38 : 32|16@1- (0.1,0) [-3276.8|3276.7] "A" Receiver
   SG_ DIF_motorIB m32 : 32|16@1+ (0.1,0) [0|6553.5] "A" Receiver
   SG_ DIF_motorIBavg m38 : 48|16@1- (0.1,0) [-3276.8|3276.7] "A" Receiver
   SG_ DIF_motorIC m32 : 48|16@1+ (0.1,0) [0|6553.5] "A" Receiver
   SG_ DIF_motorType m128 : 8|5@1+ (1,0) [0|28] "" Receiver
   SG_ DIF_motorV m34 : 48|16@1+ (2e-05,0) [0|1.3107] "mindex" Receiver
   SG_ DIF_muSurfHigh m2 : 8|8@1+ (0.005,0) [0|1.2] "N/N" Receiver
   SG_ DIF_negDcBusbarTemp m70 : 48|8@1+ (1,-40) [-40|215] "C" Receiver
   SG_ DIF_offsetA m32 : 8|8@1- (0.1,0) [-12.8|12.7] "A" Receiver
   SG_ DIF_offsetB m33 : 8|8@1- (0.1,0) [-12.8|12.7] "A" Receiver
   SG_ DIF_oilPumpMotorSpeed m46 : 8|8@1+ (40,0) [0|10200] "RPM" Receiver
   SG_ DIF_oilPumpPhaseVoltage m46 : 16|8@1+ (0.1,0) [0|25.4] "V" Receiver
   SG_ DIF_oilPumpPressureEstimateMax m46 : 24|8@1+ (2,0) [0|500] "kPa" Receiver
   SG_ DIF_oilPumpPressureExpectedMin m46 : 32|8@1+ (2,0) [0|500] "kPa" Receiver
   SG_ DIF_opdUnavailableReason m45 : 40|4@1+ (1,0) [0|15] "" Receiver
   SG_ DIF_pcsTemp m64 : 24|8@1+ (1,-40) [-40|215] "C" Receiver
   SG_ DIF_peakFlux m36 : 48|16@1+ (0.0001,0) [0|6.5535] "Wb" Receiver
   SG_ DIF_peakIQref m38 : 16|16@1+ (0.1,0) [0|6553.5] "A" Receiver
   SG_ DIF_pedalPosFilt m2 : 32|8@1+ (0.4,0) [0|100] "%" Receiver
   SG_ DIF_phaseOutBusbarTemp m70 : 8|8@1+ (1,-40) [-40|215] "C" Receiver
   SG_ DIF_phaseOutBusbarWeldTemp m70 : 16|8@1+ (1,-40) [-40|215] "C" Receiver
   SG_ DIF_phaseOutLugTemp m70 : 24|8@1+ (1,-40) [-40|215] "C" Receiver
   SG_ DIF_posDcBusbarTemp m70 : 56|8@1+ (1,-40) [-40|215] "C" Receiver
   SG_ DIF_powerStageSafeState m50 : 13|2@1+ (1,0) [0|3] "" Receiver
   SG_ DIF_pwrSatChargeCurrent m42 : 8|8@1+ (0.4,0) [0|102] "%" Receiver
   SG_ DIF_pwrSatDischargeCurrent m40 : 8|8@1+ (0.4,0) [0|102] "%" Receiver
   SG_ DIF_pwrSatMaxBusVoltage m39 : 48|8@1+ (0.4,0) [0|102] "%" Receiver
   SG_ DIF_pwrSatMaxDischargePower m39 : 16|8@1+ (0.4,0) [0|102] "%" Receiver
   SG_ DIF_pwrSatMaxRegenPower m39 : 24|8@1+ (0.4,0) [0|102] "%" Receiver
   SG_ DIF_pwrSatMinBusVoltage m39 : 56|8@1+ (0.4,0) [0|102] "%" Receiver
   SG_ DIF_resolverClaMIA m48 : 43|1@1+ (1,0) [0|1] "" Receiver
   SG_ DIF_resolverCommonGain m48 : 32|8@1+ (0.025,0) [0|5] "1" Receiver
   SG_ DIF_resolverCosFiltered m52 : 32|8@1- (0.01,0) [-1|1] "1" Receiver
   SG_ DIF_resolverCosRmsSquared m52 : 16|8@1+ (0.005,0) [0|1] "1" Receiver
   SG_ DIF_resolverErrorRmsSquared m52 : 48|8@1+ (0.005,0) [0|1] "1" Receiver
   SG_ DIF_resolverNoCarrier m48 : 41|1@1+ (1,0) [0|1] "" Receiver
   SG_ DIF_resolverNoPhaseLock m48 : 42|1@1+ (1,0) [0|1] "" Receiver
   SG_ DIF_resolverOffsetCos m48 : 8|8@1+ (0.015,0) [0|3.3] "V" Receiver
   SG_ DIF_resolverOffsetSin m48 : 16|8@1+ (0.015,0) [0|3.3] "V" Receiver
   SG_ DIF_resolverPhaseOffset m48 : 24|8@1+ (0.1,7.5) [7.5|32.5] "us" Receiver
   SG_ DIF_resolverReady m48 : 40|1@1+ (1,0) [0|1] "" Receiver
   SG_ DIF_resolverSinFiltered m52 : 40|8@1- (0.01,0) [-1|1] "1" Receiver
   SG_ DIF_resolverSinRmsSquared m52 : 24|8@1+ (0.005,0) [0|1] "1" Receiver
   SG_ DIF_rotorFlux m47 : 16|16@1+ (0.0001,0) [0|6.5535] "Wb" Receiver
   SG_ DIF_rotorMaxMagnetTemp m72 : 16|8@1+ (1,-40) [-40|215] "C" Receiver
   SG_ DIF_rotorOffsetEst m43 : 8|12@1- (0.01,0) [-20|20] "deg" Receiver
   SG_ DIF_rotorOffsetLearningState m63 : 8|4@1+ (1,0) [0|9] "" Receiver
   SG_ DIF_rotorOffsetMean m43 : 20|12@1- (0.01,0) [-20|20] "deg" Receiver
   SG_ DIF_rsScale m34 : 8|8@1+ (0.01,0) [0|2.55] "scale" Receiver
   SG_ DIF_soptMaxCurrentMagSqrd m49 : 40|16@1+ (100,0) [0|6.5535e+06] "A2" Receiver
   SG_ DIF_soptTimeToOff m49 : 24|11@1+ (0.05,0) [0|100] "ms" Receiver
   SG_ DIF_soptTimeToTrip m49 : 8|8@1+ (0.05,0) [0|10] "ms" Receiver
   SG_ DIF_soptTripDelay m49 : 16|8@1+ (0.05,0) [0|10] "ms" Receiver
   SG_ DIF_ssmState m38 : 8|4@1+ (1,0) [0|8] "" Receiver
   SG_ DIF_statorEndWindingTemp m72 : 8|8@1+ (1,-40) [-40|215] "C" Receiver
   SG_ DIF_statorFluxFdb m35 : 32|16@1+ (0.0001,0) [0|6.5535] "Wb" Receiver
   SG_ DIF_statorFluxRef m35 : 16|16@1+ (0.0001,0) [0|6.5535] "Wb" Receiver
   SG_ DIF_statorIDfdb m33 : 32|16@1- (0.1,0) [-3276.8|3276.7] "A" Receiver
   SG_ DIF_statorIDref m33 : 16|16@1- (0.1,0) [-3276.8|3276.7] "A" Receiver
   SG_ DIF_statorIQfdb m34 : 32|16@1- (0.1,0) [-3276.8|3276.7] "A" Receiver
   SG_ DIF_statorIQref m34 : 16|16@1- (0.1,0) [-3276.8|3276.7] "A" Receiver
   SG_ DIF_statorTemp1 m64 : 32|8@1+ (1,-40) [-40|215] "C" Receiver
   SG_ DIF_statorTemp2 m64 : 40|8@1+ (1,-40) [-40|215] "C" Receiver
   SG_ DIF_statorVD m36 : 32|16@1- (4e-05,0) [-1.31072|1.31068] "mindex" Receiver
   SG_ DIF_statorVDFiltered m63 : 16|16@1- (4e-05,0) [-1.31072|1.31068] "mindex" Receiver
   SG_ DIF_statorVQ m36 : 16|16@1- (4e-05,0) [-1.31072|1.31068] "mindex" Receiver
   SG_ DIF_statorVQFiltered m63 : 32|16@1- (4e-05,0) [-1.31072|1.31068] "mindex" Receiver
   SG_ DIF_sysHeatPowerOptimal m50 : 16|8@1+ (0.08,0) [0|20] "kW" Receiver
   SG_ DIF_sysPedalMaxTorque m44 : 22|14@1+ (0.1,0) [0|1638.3] "Nm" Receiver
   SG_ DIF_sysPedalMinTorque m44 : 8|14@1+ (0.1,-1638.3) [-1638.3|0] "Nm" Receiver
   SG_ DIF_sysPostPedalMaxTorque m44 : 50|14@1+ (0.1,0) [0|1638.3] "Nm" Receiver
   SG_ DIF_sysPostPedalMinTorque m44 : 36|14@1+ (0.1,-1638.3) [-1638.3|0] "Nm" Receiver
   SG_ DIF_systemStack m68 : 8|8@1+ (0.4,0) [0|100] "%" Receiver
   SG_ DIF_systemTorqueCommand m35 : 48|16@1- (0.035,0) [-1146.88|1146.85] "Nm" Receiver
   SG_ DIF_tcMaxRequest m40 : 16|8@1+ (5,0) [0|1275] "Nm" Receiver
   SG_ DIF_tcMinRequest m40 : 24|8@1+ (5,0) [0|1275] "Nm" Receiver
   SG_ DIF_torquePerAmp m33 : 48|16@1+ (0.0001,0) [0|6.5535] "Nm/A" Receiver
   SG_ DIF_tqSatMotorCurrent m39 : 40|8@1+ (0.4,0) [0|102] "%" Receiver
   SG_ DIF_tqSatMotorVoltage m39 : 32|8@1+ (0.4,0) [0|102] "%" Receiver
   SG_ DIF_tqSatThermal m39 : 8|8@1+ (0.4,0) [0|102] "%" Receiver
   SG_ DIF_tqSatUiDriveTorque m40 : 32|8@1+ (0.4,0) [0|102] "%" Receiver
   SG_ DIF_tqSatUiRegenTorque m40 : 40|8@1+ (0.4,0) [0|102] "%" Receiver
   SG_ DIF_tqScaleDifferential m35 : 8|8@1+ (0.4,0) [0|102] "%" Receiver
   SG_ DIF_tqScaleMaxMotorSpeed m40 : 48|8@1+ (0.4,0) [0|102] "%" Receiver
   SG_ DIF_tqScaleShift m40 : 56|8@1+ (0.4,0) [0|102] "%" Receiver
   SG_ DIF_udsStack m68 : 40|8@1+ (0.4,0) [0|100] "%" Receiver
   SG_ DIF_usmState m38 : 12|3@1+ (1,0) [0|7] "" Receiver
   SG_ DIF_veMassInvRaw m41 : 8|12@1+ (1e-07,0.0001) [0.0001|0.0005] "1/kg" Receiver
   SG_ DIF_veResForce m41 : 20|12@1- (0.0005,0) [-1.024|1.0235] "G" Receiver
   SG_ DIF_velocityEstimatorState m65 : 8|3@1+ (1,0) [0|4] "" Receiver
   SG_ DIF_wasteCurrentLimit m41 : 48|16@1+ (0.1,0) [0|6553.5] "A" Receiver
   SG_ DIF_xcpStack m68 : 48|8@1+ (0.4,0) [0|100] "%" Receiver

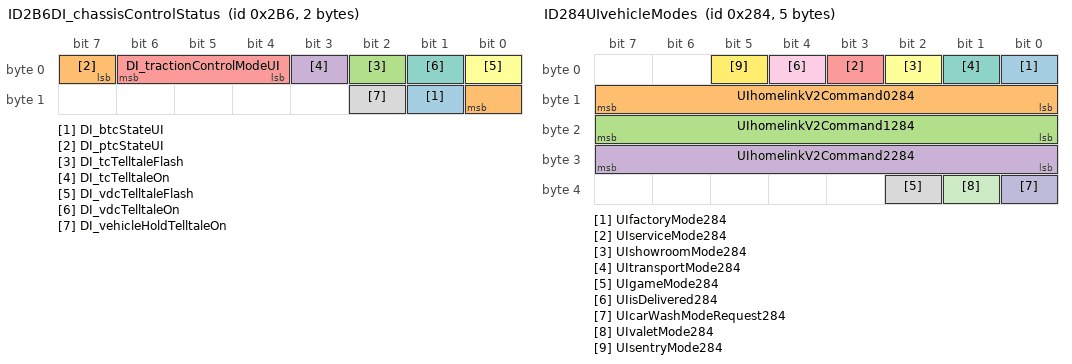
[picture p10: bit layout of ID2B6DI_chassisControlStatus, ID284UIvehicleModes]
BO_ 694 ID2B6DI_chassisControlStatus: 2 VehicleBus
   SG_ DI_btcStateUI : 9|1@1+ (1,0) [0|1] "" Receiver
   SG_ DI_ptcStateUI : 7|2@1+ (1,0) [0|3] "" Receiver
   SG_ DI_tcTelltaleFlash : 2|1@1+ (1,0) [0|1] "" Receiver
   SG_ DI_tcTelltaleOn : 3|1@1+ (1,0) [0|1] "" Receiver
   SG_ DI_tractionControlModeUI : 4|3@1+ (1,0) [0|6] "" Receiver
   SG_ DI_vdcTelltaleFlash : 0|1@1+ (1,0) [0|1] "" Receiver
   SG_ DI_vdcTelltaleOn : 1|1@1+ (1,0) [0|1] "" Receiver
   SG_ DI_vehicleHoldTelltaleOn : 10|1@1+ (1,0) [0|1] "" Receiver

BO_ 644 ID284UIvehicleModes: 5 VehicleBus
   SG_ UIfactoryMode284 : 0|1@1+ (1,0) [0|0] "" Receiver
   SG_ UIhomelinkV2Command0284 : 8|8@1+ (1,0) [0|0] "" Receiver
   SG_ UIhomelinkV2Command1284 : 16|8@1+ (1,0) [0|0] "" Receiver
   SG_ UIhomelinkV2Command2284 : 24|8@1+ (1,0) [0|0] "" Receiver
   SG_ UIserviceMode284 : 3|1@1+ (1,0) [0|0] "" Receiver
   SG_ UIshowroomMode284 : 2|1@1+ (1,0) [0|0] "" Receiver
   SG_ UItransportMode284 : 1|1@1+ (1,0) [0|0] "" Receiver
   SG_ UIgameMode284 : 34|1@1+ (1,0) [0|0] "" Receiver
   SG_ UIisDelivered284 : 4|1@1+ (1,0) [0|0] "" Receiver
   SG_ UIcarWashModeRequest284 : 32|1@1+ (1,0) [0|0] "" Receiver
   SG_ UIvaletMode284 : 33|1@1+ (1,0) [0|0] "" Receiver
   SG_ UIsentryMode284 : 5|1@1+ (1,0) [0|0] "" Receiver

BA_DEF_ BO_ "GenMsgCycleTime" INT 0 0;
BA_DEF_ SG_ "SystemSignalLongSymbol" STRING ;
BA_ "SystemSignalLongSymbol" SG_ 611 VCRIGHT_hvacFilterLifeDetectActi "VCRIGHT_hvacFilterLifeDetectActi";
BA_ "SystemSignalLongSymbol" SG_ 642 VCLEFT_hvacBlower_IO_CBC_TAIL_va "VCLEFT_hvacBlower_IO_CBC_TAIL_va";
BA_ "SystemSignalLongSymbol" SG_ 642 VCLEFT_hvacBlower_IO_CBC_numUart "VCLEFT_hvacBlower_IO_CBC_numUart";
BA_ "SystemSignalLongSymbol" SG_ 899 VCRIGHT_estimatedVehicleSituatio "VCRIGHT_estimatedVehicleSituatio";
BA_ "SystemSignalLongSymbol" SG_ 963 VCRIGHT_liftgateShutfaceSwitchPr "VCRIGHT_liftgateShutfaceSwitchPr";
BA_ "GenMsgCycleTime" BO_ 530 100;
BA_ "SystemSignalLongSymbol" SG_ 946 BMS_hvChain_limitingStateTempera "BMS_hvChain_limitingStateTempera";
BA_ "SystemSignalLongSymbol" SG_ 946 BMS_vChangeWindowNumOutlierChang "BMS_vChangeWindowNumOutlierChang";
BA_ "SystemSignalLongSymbol" SG_ 800 BMS_a040_SW_Watch_Dog_HW_Trigger "BMS_a040_SW_Watch_Dog_HW_Trigger";
BA_ "SystemSignalLongSymbol" SG_ 800 BMS_a041_SW_Destructive_Reset_So "BMS_a041_SW_Destructive_Reset_So";
BA_ "SystemSignalLongSymbol" SG_ 800 BMS_a057_SW_Bandolier_Model_Warn "BMS_a057_SW_Bandolier_Model_Warn";
BA_ "SystemSignalLongSymbol" SG_ 800 BMS_a058_SW_Bandolier_Model_Rese "BMS_a058_SW_Bandolier_Model_Rese";
BA_ "SystemSignalLongSymbol" SG_ 800 BMS_a092_SW_ChargePort_Mia_On_Hv "BMS_a092_SW_ChargePort_Mia_On_Hv";
BA_ "SystemSignalLongSymbol" SG_ 800 BMS_a098_SW_BMB_Data_Integrity_L "BMS_a098_SW_BMB_Data_Integrity_L";
BA_ "SystemSignalLongSymbol" SG_ 800 BMS_a135_HW_BMB_Diagnostics_Fail "BMS_a135_HW_BMB_Diagnostics_Fail";
BA_ "SystemSignalLongSymbol" SG_ 800 BMS_a178_SW_Uncontrolled_Regen_P "BMS_a178_SW_Uncontrolled_Regen_P";
BA_ "GenMsgCycleTime" BO_ 819 500;
BA_ "GenMsgCycleTime" BO_ 577 100;
BA_DEF_DEF_ "GenMsgCycleTime" 0;
BA_DEF_DEF_ "SystemSignalLongSymbol" "";
CM_ SG_ 985 UI_gpsVehicleHeading "GPS Heading";
CM_ SG_ 985 UI_gpsVehicleSpeed "GPS Speed";
CM_ SG_ 1011 UI_odometer "UI Odometer";
CM_ SG_ 615 DI_gradeEst "Estimated Grade";
CM_ SG_ 615 DI_mass "Estimated Mass";
CM_ SG_ 642 VCLEFT_hvacBlowerRPMActual "HVAC Blower Speed";
CM_ SG_ 647 PTC_leftCurrentHV "Heater Left Current";
CM_ SG_ 647 PTC_rightCurrentHV "Heater Right Current";
CM_ SG_ 647 PTC_voltageHV "Heater Voltage";
CM_ SG_ 819 UI_acChargeCurrentLimit "UI Charge Current Limit";
CM_ SG_ 826 UI_Range "Range";
CM_ SG_ 826 UI_SOC "State of Charge UI";
CM_ SG_ 826 UI_uSOE "UI fine SOC";
CM_ SG_ 826 UI_ratedWHpM "WHM Rating";
CM_ SG_ 577 VCFRONT_coolantFlowBatActual "Battery Coolant Flow";
CM_ SG_ 577 VCFRONT_coolantFlowPTActual "Powertrain Coolant Flow";
CM_ BO_ 1367 "swapped with 5D7 in old firmware";
CM_ BO_ 1495 "swapped with 557 in old firmware";
CM_ BO_ 2005 "swapped with 757 in old firmware";
CM_ BO_ 1879 "swapped with 7D5 in old firmware";
VAL_ 905 DAS_ACC_report 24 "ACC_REPORT_BEHAVIOR_REPORT" 23 "ACC_REPORT_CAMERA_ONLY" 21 "ACC_REPORT_CIPV_CUTTING_OUT" 10 "ACC_REPORT_CSA" 18 "ACC_REPORT_FLEET_SPEEDS" 13 "ACC_REPORT_LC_EXTERNAL_STATE_ABORTED" 12 "ACC_REPORT_LC_EXTERNAL_STATE_ABORTING" 14 "ACC_REPORT_LC_EXTERNAL_STATE_ACTIVE_RESTRICTED" 11 "ACC_REPORT_LC_HANDS_ON_REQD_STRUCK_OUT" 19 "ACC_REPORT_MCVLR_DPP" 20 "ACC_REPORT_MCVLR_IN_PATH" 22 "ACC_REPORT_RADAR_OBJ_FIVE" 15 "ACC_REPORT_RADAR_OBJ_ONE" 16 "ACC_REPORT_RADAR_OBJ_TWO" 1 "ACC_REPORT_TARGET_CIPV" 5 "ACC_REPORT_TARGET_CUTIN" 2 "ACC_REPORT_TARGET_IN_FRONT_OF_CIPV" 17 "ACC_REPORT_TARGET_MCP" 3 "ACC_REPORT_TARGET_MCVL" 4 "ACC_REPORT_TARGET_MCVR" 0 "ACC_REPORT_TARGET_NONE" 9 "ACC_REPORT_TARGET_TYPE_FAULT" 8 "ACC_REPORT_TARGET_TYPE_IPSO" 6 "ACC_REPORT_TARGET_TYPE_STOP_SIGN" 7 "ACC_REPORT_TARGET_TYPE_TRAFFIC_LIGHT";
VAL_ 905 DAS_accSpeedLimit 0 "NONE" 1023 "SNA";
VAL_ 905 DAS_activationFailureStatus 1 "LC_ACTIVATION_FAILED_1" 2 "LC_ACTIVATION_FAILED_2" 0 "LC_ACTIVATION_IDLE";
VAL_ 905 DAS_csaState 1 "CSA_EXTERNAL_STATE_AVAILABLE" 2 "CSA_EXTERNAL_STATE_ENABLE" 3 "CSA_EXTERNAL_STATE_HOLD" 0 "CSA_EXTERNAL_STATE_UNAVAILABLE";
VAL_ 905 DAS_driverInteractionLevel 2 "CONTINUED_DRIVER_NOT_INTERACTING" 0 "DRIVER_INTERACTING" 1 "DRIVER_NOT_INTERACTING";
VAL_ 905 DAS_longCollisionWarning 3 "FCM_LONG_COLLISION_WARNING_IPSO" 0 "FCM_LONG_COLLISION_WARNING_NONE" 2 "FCM_LONG_COLLISION_WARNING_PEDESTRIAN" 15 "FCM_LONG_COLLISION_WARNING_SNA" 4 "FCM_LONG_COLLISION_WARNING_STOPSIGN_STOPLINE" 5 "FCM_LONG_COLLISION_WARNING_TFL_STOPLINE" 6 "FCM_LONG_COLLISION_WARNING_VEHICLE_CIPV" 12 "FCM_LONG_COLLISION_WARNING_VEHICLE_CIPV2" 7 "FCM_LONG_COLLISION_WARNING_VEHICLE_CUTIN" 8 "FCM_LONG_COLLISION_WARNING_VEHICLE_MCVL" 9 "FCM_LONG_COLLISION_WARNING_VEHICLE_MCVL2" 10 "FCM_LONG_COLLISION_WARNING_VEHICLE_MCVR" 11 "FCM_LONG_COLLISION_WARNING_VEHICLE_MCVR2" 1 "FCM_LONG_COLLISION_WARNING_VEHICLE_UNKNOWN";
VAL_ 905 DAS_pmmCameraFaultReason 1 "PMM_CAMERA_BLOCKED_FRONT" 2 "PMM_CAMERA_INVALID_MIA" 0 "PMM_CAMERA_NO_FAULT";
VAL_ 905 DAS_pmmLoggingRequest 0 "FALSE" 1 "TRUE";
VAL_ 905 DAS_pmmObstacleSeverity 6 "PMM_ACCEL_LIMIT" 3 "PMM_BRAKE_REQUEST" 5 "PMM_CRASH_FRONT" 4 "PMM_CRASH_REAR" 2 "PMM_IMMINENT_FRONT" 1 "PMM_IMMINENT_REAR" 0 "PMM_NONE" 7 "PMM_SNA";
VAL_ 905 DAS_pmmRadarFaultReason 1 "PMM_RADAR_BLOCKED_FRONT" 2 "PMM_RADAR_INVALID_MIA" 0 "PMM_RADAR_NO_FAULT";
VAL_ 905 DAS_pmmSysFaultReason 7 "PMM_FAULT_BRAKE_PEDAL_INHIBIT" 1 "PMM_FAULT_DAS_DISABLED" 5 "PMM_FAULT_DISABLED_BY_USER" 3 "PMM_FAULT_DI_FAULT" 0 "PMM_FAULT_NONE" 6 "PMM_FAULT_ROAD_TYPE" 2 "PMM_FAULT_SPEED" 4 "PMM_FAULT_STEERING_ANGLE_RATE";
VAL_ 905 DAS_pmmUltrasonicsFaultReason 3 "PMM_ULTRASONICS_BLOCKED_BOTH" 1 "PMM_ULTRASONICS_BLOCKED_FRONT" 2 "PMM_ULTRASONICS_BLOCKED_REAR" 4 "PMM_ULTRASONICS_INVALID_MIA" 0 "PMM_ULTRASONICS_NO_FAULT";
VAL_ 905 DAS_ppOffsetDesiredRamp 128 "PP_NO_OFFSET";
VAL_ 905 DAS_radarTelemetry 0 "RADAR_TELEMETRY_IDLE" 1 "RADAR_TELEMETRY_NORMAL" 2 "RADAR_TELEMETRY_URGENT";
VAL_ 905 DAS_robState 2 "ROB_STATE_ACTIVE" 0 "ROB_STATE_INHIBITED" 3 "ROB_STATE_MAPLESS" 1 "ROB_STATE_MEASURE";
VAL_ 921 DAS_autoLaneChangeState 19 "ALC_ABORT_BLINKER_TURNED_OFF" 18 "ALC_ABORT_LC_HEALTH_BAD" 30 "ALC_ABORT_MISSION_PLAN_INVALID" 20 "ALC_ABORT_OTHER_REASON" 17 "ALC_ABORT_POOR_VIEW_RANGE" 15 "ALC_ABORT_SIDE_OBSTACLE_PRESENT_L" 16 "ALC_ABORT_SIDE_OBSTACLE_PRESENT_R" 29 "ALC_ABORT_TIMEOUT" 8 "ALC_AVAILABLE_BOTH" 6 "ALC_AVAILABLE_ONLY_L" 7 "ALC_AVAILABLE_ONLY_R" 26 "ALC_BLOCKED_LANE_TYPE_L" 27 "ALC_BLOCKED_LANE_TYPE_R" 23 "ALC_BLOCKED_VEH_TTC_AND_USS_L" 25 "ALC_BLOCKED_VEH_TTC_AND_USS_R" 22 "ALC_BLOCKED_VEH_TTC_L" 24 "ALC_BLOCKED_VEH_TTC_R" 9 "ALC_IN_PROGRESS_L" 10 "ALC_IN_PROGRESS_R" 31 "ALC_SNA" 0 "ALC_UNAVAILABLE_DISABLED" 4 "ALC_UNAVAILABLE_EXITING_HIGHWAY" 1 "ALC_UNAVAILABLE_NO_LANES" 21 "ALC_UNAVAILABLE_SOLID_LANE_LINE" 2 "ALC_UNAVAILABLE_SONICS_INVALID" 3 "ALC_UNAVAILABLE_TP_FOLLOW" 5 "ALC_UNAVAILABLE_VEHICLE_SPEED" 13 "ALC_WAITING_FOR_FWD_OBST_TO_PASS_L" 14 "ALC_WAITING_FOR_FWD_OBST_TO_PASS_R" 11 "ALC_WAITING_FOR_SIDE_OBST_TO_PASS_L" 12 "ALC_WAITING_FOR_SIDE_OBST_TO_PASS_R" 28 "ALC_WAITING_HANDS_ON";
VAL_ 921 DAS_autoparkReady 1 "AUTOPARK_READY" 0 "AUTOPARK_UNAVAILABLE";
VAL_ 921 DAS_autopilotHandsOnState 0 "LC_HANDS_ON_NOT_REQD" 4 "LC_HANDS_ON_REQD_CHIME_1" 5 "LC_HANDS_ON_REQD_CHIME_2" 1 "LC_HANDS_ON_REQD_DETECTED" 9 "LC_HANDS_ON_REQD_ESCALATED_CHIME_1" 10 "LC_HANDS_ON_REQD_ESCALATED_CHIME_2" 2 "LC_HANDS_ON_REQD_NOT_DETECTED" 6 "LC_HANDS_ON_REQD_SLOWING" 7 "LC_HANDS_ON_REQD_STRUCK_OUT" 3 "LC_HANDS_ON_REQD_VISUAL" 15 "LC_HANDS_ON_SNA" 8 "LC_HANDS_ON_SUSPENDED";
VAL_ 921 DAS_autopilotState 9 "ABORTED" 8 "ABORTING" 5 "ACTIVE_NAV" 3 "ACTIVE_NOMINAL" 4 "ACTIVE_RESTRICTED" 2 "AVAILABLE" 0 "DISABLED" 14 "FAULT" 15 "SNA" 1 "UNAVAILABLE";
VAL_ 921 DAS_blindSpotRearLeft 0 "NO_WARNING" 3 "SNA" 1 "WARNING_LEVEL_1" 2 "WARNING_LEVEL_2";
VAL_ 921 DAS_blindSpotRearRight 0 "NO_WARNING" 3 "SNA" 1 "WARNING_LEVEL_1" 2 "WARNING_LEVEL_2";
VAL_ 921 DAS_fleetSpeedState 2 "FLEETSPEED_ACTIVE" 1 "FLEETSPEED_AVAILABLE" 3 "FLEETSPEED_HOLD" 0 "FLEETSPEED_UNAVAILABLE";
VAL_ 921 DAS_forwardCollisionWarning 1 "FORWARD_COLLISION_WARNING" 0 "NONE" 3 "SNA";
VAL_ 921 DAS_fusedSpeedLimit 31 "NONE" 0 "UNKNOWN_SNA";
VAL_ 921 DAS_heaterState 0 "HEATER_OFF_SNA" 1 "HEATER_ON";
VAL_ 921 DAS_laneDepartureWarning 1 "LEFT_WARNING" 3 "LEFT_WARNING_SEVERE" 0 "NONE" 2 "RIGHT_WARNING" 4 "RIGHT_WARNING_SEVERE" 5 "SNA";
VAL_ 921 DAS_lssState 6 "LSS_STATE_ABORT" 5 "LSS_STATE_BLINDSPOT" 3 "LSS_STATE_ELK" 0 "LSS_STATE_FAULT" 1 "LSS_STATE_LDW" 2 "LSS_STATE_LKA" 4 "LSS_STATE_MONITOR" 7 "LSS_STATE_OFF";
VAL_ 921 DAS_sideCollisionAvoid 1 "AVOID_LEFT" 2 "AVOID_RIGHT" 0 "NONE" 3 "SNA";
VAL_ 921 DAS_sideCollisionInhibit 1 "INHIBIT" 0 "NO_INHIBIT";
VAL_ 921 DAS_sideCollisionWarning 0 "NONE" 1 "WARN_LEFT" 3 "WARN_LEFT_RIGHT" 2 "WARN_RIGHT";
VAL_ 921 DAS_suppressSpeedWarning 0 "Do_Not_Suppress" 1 "Suppress_Speed_Warning";
VAL_ 921 DAS_visionOnlySpeedLimit 31 "NONE" 0 "UNKNOWN_SNA";
VAL_ 925 IBST_driverBrakeApply 1 "BRAKES_NOT_APPLIED" 2 "DRIVER_APPLYING_BRAKES" 3 "FAULT" 0 "NOT_INIT_OR_OFF";
VAL_ 925 IBST_iBoosterStatus 4 "IBOOSTER_ACTIVE_GOOD_CHECK" 6 "IBOOSTER_ACTUATION" 3 "IBOOSTER_DIAGNOSTIC" 2 "IBOOSTER_FAILURE" 1 "IBOOSTER_INIT" 0 "IBOOSTER_OFF" 5 "IBOOSTER_READY";
VAL_ 925 IBST_internalState 4 "DIAGNOSTIC" 3 "EXTERNAL_BRAKE_REQUEST" 2 "LOCAL_BRAKE_REQUEST" 0 "NO_MODE_ACTIVE" 6 "POST_DRIVE_CHECK" 1 "PRE_DRIVE_CHECK" 5 "TRANSITION_TO_IDLE";
VAL_ 929 VCFRONT_12vStatusForDrive 2 "EXIT_DRIVE_REQUESTED_12V" 0 "NOT_READY_FOR_DRIVE_12V" 1 "READY_FOR_DRIVE_12V";
VAL_ 929 VCFRONT_2RowCenterUnbuckled 0 "CHIME_NONE" 1 "CHIME_OCCUPIED_AND_UNBUCKLED" 2 "CHIME_SNA";
VAL_ 929 VCFRONT_2RowLeftUnbuckled 0 "CHIME_NONE" 1 "CHIME_OCCUPIED_AND_UNBUCKLED" 2 "CHIME_SNA";
VAL_ 929 VCFRONT_2RowRightUnbuckled 0 "CHIME_NONE" 1 "CHIME_OCCUPIED_AND_UNBUCKLED" 2 "CHIME_SNA";
VAL_ 929 VCFRONT_APGlassHeaterState 4 "HEATER_STATE_FAULT" 2 "HEATER_STATE_OFF" 3 "HEATER_STATE_OFF_UNAVAILABLE" 1 "HEATER_STATE_ON" 0 "HEATER_STATE_SNA";
VAL_ 929 VCFRONT_diPowerOnState 0 "DI_POWERED_OFF" 3 "DI_POWERED_ON_FOR_DRIVE" 2 "DI_POWERED_ON_FOR_STATIONARY_HEAT" 1 "DI_POWERED_ON_FOR_SUMMON" 4 "DI_POWER_GOING_DOWN";
VAL_ 929 VCFRONT_driverBuckleStatus 1 "BUCKLED" 0 "UNBUCKLED";
VAL_ 929 VCFRONT_driverDoorStatus 1 "DOOR_CLOSED" 0 "DOOR_OPEN";
VAL_ 929 VCFRONT_driverUnbuckled 0 "CHIME_NONE" 1 "CHIME_OCCUPIED_AND_UNBUCKLED" 2 "CHIME_SNA";
VAL_ 929 VCFRONT_passengerUnbuckled 0 "CHIME_NONE" 1 "CHIME_OCCUPIED_AND_UNBUCKLED" 2 "CHIME_SNA";
VAL_ 929 VCFRONT_pcsEFuseVoltage 1023 "SNA";
VAL_ 929 VCFRONT_thermalSystemType 1 "HEAT_PUMP_THERMAL_SYSTEM" 0 "LEGACY_THERMAL_SYSTEM";
VAL_ 985 UI_conditionalSpeedLimit 31 "SNA";
VAL_ 985 UI_mapSpeedLimitUnits 1 "KPH" 0 "MPH";
VAL_ 985 UI_userSpeedOffsetUnits 1 "KPH" 0 "MPH";
VAL_ 994 VCLEFT_FLMapLightStatus 2 "LIGHT_FAULT" 0 "LIGHT_OFF" 1 "LIGHT_ON" 3 "LIGHT_SNA";
VAL_ 994 VCLEFT_FRMapLightStatus 2 "LIGHT_FAULT" 0 "LIGHT_OFF" 1 "LIGHT_ON" 3 "LIGHT_SNA";
VAL_ 994 VCLEFT_RLMapLightStatus 2 "LIGHT_FAULT" 0 "LIGHT_OFF" 1 "LIGHT_ON" 3 "LIGHT_SNA";
VAL_ 994 VCLEFT_RRMapLightStatus 2 "LIGHT_FAULT" 0 "LIGHT_OFF" 1 "LIGHT_ON" 3 "LIGHT_SNA";
VAL_ 994 VCLEFT_brakeLightStatus 2 "LIGHT_FAULT" 0 "LIGHT_OFF" 1 "LIGHT_ON" 3 "LIGHT_SNA";
VAL_ 994 VCLEFT_brakeTrailerLightStatus 2 "LIGHT_FAULT" 0 "LIGHT_OFF" 1 "LIGHT_ON" 3 "LIGHT_SNA";
VAL_ 994 VCLEFT_dynamicBrakeLightStatus 2 "DYNAMIC_BRAKE_LIGHT_ACTIVE_HIGH" 1 "DYNAMIC_BRAKE_LIGHT_ACTIVE_LOW" 0 "DYNAMIC_BRAKE_LIGHT_OFF";
VAL_ 994 VCLEFT_fogTrailerLightStatus 2 "LIGHT_FAULT" 0 "LIGHT_OFF" 1 "LIGHT_ON" 3 "LIGHT_SNA";
VAL_ 994 VCLEFT_frontRideHeight 128 "SNA";
VAL_ 994 VCLEFT_leftTurnTrailerLightStatu 2 "LIGHT_FAULT" 0 "LIGHT_OFF" 1 "LIGHT_ON" 3 "LIGHT_SNA";
VAL_ 994 VCLEFT_rearRideHeight 128 "SNA";
VAL_ 994 VCLEFT_reverseTrailerLightStatus 2 "LIGHT_FAULT" 0 "LIGHT_OFF" 1 "LIGHT_ON" 3 "LIGHT_SNA";
VAL_ 994 VCLEFT_rightTrnTrailerLightStatu 2 "LIGHT_FAULT" 0 "LIGHT_OFF" 1 "LIGHT_ON" 3 "LIGHT_SNA";
VAL_ 994 VCLEFT_tailLightStatus 2 "LIGHT_FAULT" 0 "LIGHT_OFF" 1 "LIGHT_ON" 3 "LIGHT_SNA";
VAL_ 994 VCLEFT_tailTrailerLightStatus 2 "LIGHT_FAULT" 0 "LIGHT_OFF" 1 "LIGHT_ON" 3 "LIGHT_SNA";
VAL_ 994 VCLEFT_trailerDetected 2 "TRAILER_LIGHT_DETECTION_DETECTED" 1 "TRAILER_LIGHT_DETECTION_FAULT" 3 "TRAILER_LIGHT_DETECTION_NOT_DETECTED" 0 "TRAILER_LIGHT_DETECTION_SNA";
VAL_ 994 VCLEFT_turnSignalStatus 2 "LIGHT_FAULT" 0 "LIGHT_OFF" 1 "LIGHT_ON" 3 "LIGHT_SNA";
VAL_ 1001 DAS_hazardLightRequest 0 "DAS_REQUEST_HAZARDS_OFF" 1 "DAS_REQUEST_HAZARDS_ON" 3 "DAS_REQUEST_HAZARDS_SNA" 2 "DAS_REQUEST_HAZARDS_UNUSED";
VAL_ 1001 DAS_headlightRequest 3 "DAS_HEADLIGHT_REQUEST_INVALID" 0 "DAS_HEADLIGHT_REQUEST_OFF" 1 "DAS_HEADLIGHT_REQUEST_ON";
VAL_ 1001 DAS_heaterRequest 1 "DAS_HEATER_OFF" 2 "DAS_HEATER_ON" 0 "DAS_HEATER_SNA";
VAL_ 1001 DAS_highLowBeamDecision 1 "DAS_HIGH_BEAM_OFF" 2 "DAS_HIGH_BEAM_ON" 3 "DAS_HIGH_BEAM_SNA" 0 "DAS_HIGH_BEAM_UNDECIDED";
VAL_ 1001 DAS_highLowBeamOffReason 3 "HIGH_BEAM_OFF_REASON_AMBIENT_LIGHT" 4 "HIGH_BEAM_OFF_REASON_HEAD_LIGHT" 2 "HIGH_BEAM_OFF_REASON_MOVING_RADAR_TARGET" 1 "HIGH_BEAM_OFF_REASON_MOVING_VISION_TARGET" 5 "HIGH_BEAM_OFF_REASON_SNA" 0 "HIGH_BEAM_ON";
VAL_ 1001 DAS_turnIndicatorRequest 3 "DAS_TURN_INDICATOR_CANCEL" 4 "DAS_TURN_INDICATOR_DEFER" 1 "DAS_TURN_INDICATOR_LEFT" 0 "DAS_TURN_INDICATOR_NONE" 2 "DAS_TURN_INDICATOR_RIGHT";
VAL_ 1001 DAS_turnIndicatorRequestReason 8 "DAS_ACTIVE_COMMANDED_LANE_CHANGE" 3 "DAS_ACTIVE_FORK" 9 "DAS_ACTIVE_INTERSECTION" 6 "DAS_ACTIVE_MERGE" 1 "DAS_ACTIVE_NAV_LANE_CHANGE" 2 "DAS_ACTIVE_SPEED_LANE_CHANGE" 11 "DAS_ACTIVE_SUMMMON" 5 "DAS_CANCEL_FORK" 10 "DAS_CANCEL_INTERSECTION" 4 "DAS_CANCEL_LANE_CHANGE" 7 "DAS_CANCEL_MERGE" 12 "DAS_CANCEL_SUMMMON" 0 "DAS_NONE";
VAL_ 1001 DAS_wiperSpeed 1 "DAS_WIPER_SPEED_1" 10 "DAS_WIPER_SPEED_10" 11 "DAS_WIPER_SPEED_11" 12 "DAS_WIPER_SPEED_12" 13 "DAS_WIPER_SPEED_13" 14 "DAS_WIPER_SPEED_14" 2 "DAS_WIPER_SPEED_2" 3 "DAS_WIPER_SPEED_3" 4 "DAS_WIPER_SPEED_4" 5 "DAS_WIPER_SPEED_5" 6 "DAS_WIPER_SPEED_6" 7 "DAS_WIPER_SPEED_7" 8 "DAS_WIPER_SPEED_8" 9 "DAS_WIPER_SPEED_9" 15 "DAS_WIPER_SPEED_INVALID" 0 "DAS_WIPER_SPEED_OFF";
VAL_ 1011 UI_odometer 16777215 "SNA";
VAL_ 1013 VCFRONT_DRLLeftStatus 2 "LIGHT_FAULT" 0 "LIGHT_OFF" 1 "LIGHT_ON" 3 "LIGHT_SNA";
VAL_ 1013 VCFRONT_DRLRightStatus 2 "LIGHT_FAULT" 0 "LIGHT_OFF" 1 "LIGHT_ON" 3 "LIGHT_SNA";
VAL_ 1013 VCFRONT_ambientLightingBrightnes 255 "SNA";
VAL_ 1013 VCFRONT_fogLeftStatus 2 "LIGHT_FAULT" 0 "LIGHT_OFF" 1 "LIGHT_ON" 3 "LIGHT_SNA";
VAL_ 1013 VCFRONT_fogRightStatus 2 "LIGHT_FAULT" 0 "LIGHT_OFF" 1 "LIGHT_ON" 3 "LIGHT_SNA";
VAL_ 1013 VCFRONT_hazardLightRequest 1 "HAZARD_REQUEST_BUTTON" 6 "HAZARD_REQUEST_CAR_ALARM" 5 "HAZARD_REQUEST_CRASH" 7 "HAZARD_REQUEST_DAS" 2 "HAZARD_REQUEST_LOCK" 4 "HAZARD_REQUEST_MISLOCK" 0 "HAZARD_REQUEST_NONE" 8 "HAZARD_REQUEST_UDS" 3 "HAZARD_REQUEST_UNLOCK";
VAL_ 1013 VCFRONT_highBeamLeftStatus 2 "LIGHT_FAULT" 0 "LIGHT_OFF" 1 "LIGHT_ON" 3 "LIGHT_SNA";
VAL_ 1013 VCFRONT_highBeamRightStatus 2 "LIGHT_FAULT" 0 "LIGHT_OFF" 1 "LIGHT_ON" 3 "LIGHT_SNA";
VAL_ 1013 VCFRONT_indicatorLeftRequest 2 "TURN_SIGNAL_ACTIVE_HIGH" 1 "TURN_SIGNAL_ACTIVE_LOW" 0 "TURN_SIGNAL_OFF";
VAL_ 1013 VCFRONT_indicatorRightRequest 2 "TURN_SIGNAL_ACTIVE_HIGH" 1 "TURN_SIGNAL_ACTIVE_LOW" 0 "TURN_SIGNAL_OFF";
VAL_ 1013 VCFRONT_lowBeamLeftStatus 2 "LIGHT_FAULT" 0 "LIGHT_OFF" 1 "LIGHT_ON" 3 "LIGHT_SNA";
VAL_ 1013 VCFRONT_lowBeamRightStatus 2 "LIGHT_FAULT" 0 "LIGHT_OFF" 1 "LIGHT_ON" 3 "LIGHT_SNA";
VAL_ 1013 VCFRONT_parkLeftStatus 2 "LIGHT_FAULT" 0 "LIGHT_OFF" 1 "LIGHT_ON" 3 "LIGHT_SNA";
VAL_ 1013 VCFRONT_parkRightStatus 2 "LIGHT_FAULT" 0 "LIGHT_OFF" 1 "LIGHT_ON" 3 "LIGHT_SNA";
VAL_ 1013 VCFRONT_sideMarkersStatus 2 "LIGHT_FAULT" 0 "LIGHT_OFF" 1 "LIGHT_ON" 3 "LIGHT_SNA";
VAL_ 1013 VCFRONT_sideRepeaterLeftStatus 2 "LIGHT_FAULT" 0 "LIGHT_OFF" 1 "LIGHT_ON" 3 "LIGHT_SNA";
VAL_ 1013 VCFRONT_sideRepeaterRightStatus 2 "LIGHT_FAULT" 0 "LIGHT_OFF" 1 "LIGHT_ON" 3 "LIGHT_SNA";
VAL_ 1013 VCFRONT_simLatchingStalk 0 "SIMULATED_LATCHING_STALK_IDLE" 1 "SIMULATED_LATCHING_STALK_LEFT" 2 "SIMULATED_LATCHING_STALK_RIGHT" 3 "SIMULATED_LATCHING_STALK_SNA";
VAL_ 1013 VCFRONT_switchLightingBrightness 255 "SNA";
VAL_ 1013 VCFRONT_turnSignalLeftStatus 2 "LIGHT_FAULT" 0 "LIGHT_OFF" 1 "LIGHT_ON" 3 "LIGHT_SNA";
VAL_ 1013 VCFRONT_turnSignalRightStatus 2 "LIGHT_FAULT" 0 "LIGHT_OFF" 1 "LIGHT_ON" 3 "LIGHT_SNA";
VAL_ 1016 UI_accFollowDistanceSetting 0 "DISTANCE_SETTING_1" 1 "DISTANCE_SETTING_2" 2 "DISTANCE_SETTING_3" 3 "DISTANCE_SETTING_4" 4 "DISTANCE_SETTING_5" 5 "DISTANCE_SETTING_6" 6 "DISTANCE_SETTING_7" 7 "DISTANCE_SETTING_SNA";
VAL_ 1016 UI_autopilotControlRequest 0 "LEGACY_LAT_CTRL" 1 "NEXT_GEN_CTRL";
VAL_ 1016 UI_curvSpeedAdaptDisable 1 "CSA_OFF" 0 "CSA_ON";
VAL_ 1016 UI_curvatureDatabaseOnly 0 "OFF" 1 "ON";
VAL_ 1016 UI_driveOnMapsEnable 0 "DOM_OFF" 1 "DOM_ON";
VAL_ 1016 UI_drivingSide 0 "DRIVING_SIDE_LEFT" 1 "DRIVING_SIDE_RIGHT" 2 "DRIVING_SIDE_UNKNOWN";
VAL_ 1016 UI_exceptionListEnable 0 "EXCEPTION_LIST_OFF" 1 "EXCEPTION_LIST_ON";
VAL_ 1016 UI_followNavRouteEnable 0 "NAV_ROUTE_OFF" 1 "NAV_ROUTE_ON";
VAL_ 1016 UI_fuseHPPDisable 1 "FUSE_HPP_OFF" 0 "FUSE_HPP_ON";
VAL_ 1016 UI_fuseLanesDisable 1 "FUSE_LANES_OFF" 0 "FUSE_LANES_ON";
VAL_ 1016 UI_fuseVehiclesDisable 1 "FUSE_VEH_OFF" 0 "FUSE_VEH_ON";
VAL_ 1016 UI_handsOnRequirementDisable 1 "HANDS_ON_REQ_OFF" 0 "HANDS_ON_REQ_ON";
VAL_ 1016 UI_lssElkEnabled 0 "ELK_OFF" 1 "ELK_ON";
VAL_ 1016 UI_lssLdwEnabled 0 "LDW_OFF" 1 "LDW_ON";
VAL_ 1016 UI_lssLkaEnabled 0 "LKA_OFF" 1 "LKA_ON";
VAL_ 1016 UI_roadCheckDisable 1 "RC_OFF" 0 "RC_ON";
VAL_ 1016 UI_selfParkRequest 3 "ABORT" 9 "AUTO_SUMMON_CANCEL" 7 "AUTO_SUMMON_FORWARD" 10 "AUTO_SUMMON_PRIMED" 8 "AUTO_SUMMON_REVERSE" 0 "NONE" 5 "PAUSE" 4 "PRIME" 6 "RESUME" 1 "SELF_PARK_FORWARD" 2 "SELF_PARK_REVERSE" 11 "SMART_SUMMON" 12 "SMART_SUMMON_NO_OP" 15 "SNA";
VAL_ 1016 UI_smartSummonType 1 "FIND_ME" 0 "PIN_DROP" 2 "SMART_AUTOPARK";
VAL_ 1016 UI_source3D 2 "XYZ_PREDICTION" 0 "Z_FROM_MAP" 1 "Z_FROM_PATH_PREDICTION";
VAL_ 1016 UI_summonEntryType 3 "SNA" 0 "STRAIGHT" 2 "TURN_LEFT" 1 "TURN_RIGHT";
VAL_ 1016 UI_summonExitType 3 "SNA" 0 "STRAIGHT" 2 "TURN_LEFT" 1 "TURN_RIGHT";
VAL_ 1016 UI_summonReverseDist 63 "SNA";
VAL_ 1016 UI_ulcBlindSpotConfig 1 "AGGRESSIVE" 2 "MAD_MAX" 0 "STANDARD";
VAL_ 1016 UI_ulcSpeedConfig 2 "SPEED_BASED_ULC_AVERAGE" 0 "SPEED_BASED_ULC_DISABLED" 3 "SPEED_BASED_ULC_MAD_MAX" 1 "SPEED_BASED_ULC_MILD";
VAL_ 1016 UI_visionSpeedType 0 "VISION_SPEED_DISABLED" 1 "VISION_SPEED_ONE_SECOND" 3 "VISION_SPEED_OPTIMIZED" 2 "VISION_SPEED_TWO_SECOND";
VAL_ 1021 UI_autopilotControlIndex 0 "AUTOPILOT_CONTROL_0" 1 "AUTOPILOT_CONTROL_1" 2 "AUTOPILOT_CONTROL_2" 3 "AUTOPILOT_CONTROL_3" 4 "AUTOPILOT_CONTROL_4" 5 "AUTOPILOT_CONTROL_5" 6 "AUTOPILOT_CONTROL_6" 7 "AUTOPILOT_CONTROL_7";
VAL_ 1021 UI_apmv3Branch 5 "DEMO" 2 "DEV" 4 "EAP" 0 "LIVE" 1 "STAGE" 3 "STAGE2";
VAL_ 1021 UI_blindspotDistance 1 "BLINDSPOT_DISTANCE_0P5_M" 2 "BLINDSPOT_DISTANCE_1_M" 3 "BLINDSPOT_DISTANCE_2_M" 4 "BLINDSPOT_DISTANCE_4_M" 0 "BLINDSPOT_DISTANCE_DEFAULT" 5 "BLINDSPOT_DISTANCE_OFF";
VAL_ 1021 UI_blindspotMinSpeed 2 "BLINDSPOT_MIN_SPEED_10_KPH" 3 "BLINDSPOT_MIN_SPEED_15_KPH" 4 "BLINDSPOT_MIN_SPEED_20_KPH" 5 "BLINDSPOT_MIN_SPEED_25_KPH" 6 "BLINDSPOT_MIN_SPEED_30_KPH" 7 "BLINDSPOT_MIN_SPEED_35_KPH" 8 "BLINDSPOT_MIN_SPEED_40_KPH" 9 "BLINDSPOT_MIN_SPEED_45_KPH" 1 "BLINDSPOT_MIN_SPEED_5_KPH" 0 "BLINDSPOT_MIN_SPEED_DEFAULT" 10 "BLINDSPOT_MIN_SPEED_OFF";
VAL_ 1021 UI_blindspotTTC 1 "BLINDSPOT_TTC_0P5_S" 2 "BLINDSPOT_TTC_1_S" 3 "BLINDSPOT_TTC_2_S" 5 "BLINDSPOT_TTC_3_S" 4 "BLINDSPOT_TTC_4_S" 6 "BLINDSPOT_TTC_5_S" 0 "BLINDSPOT_TTC_DEFAULT" 7 "BLINDSPOT_TTC_OFF";
VAL_ 1021 UI_donAlcProgGoreAbortThres 1 "DON_ALC_PROGRESS_GORE_ABORT_THRESHOLD_0P00" 2 "DON_ALC_PROGRESS_GORE_ABORT_THRESHOLD_0P05" 3 "DON_ALC_PROGRESS_GORE_ABORT_THRESHOLD_0P10" 4 "DON_ALC_PROGRESS_GORE_ABORT_THRESHOLD_0P15" 5 "DON_ALC_PROGRESS_GORE_ABORT_THRESHOLD_0P20" 6 "DON_ALC_PROGRESS_GORE_ABORT_THRESHOLD_0P25" 7 "DON_ALC_PROGRESS_GORE_ABORT_THRESHOLD_0P30" 8 "DON_ALC_PROGRESS_GORE_ABORT_THRESHOLD_0P35" 9 "DON_ALC_PROGRESS_GORE_ABORT_THRESHOLD_0P40" 0 "DON_ALC_PROGRESS_GORE_ABORT_THRESHOLD_DEFAULT";
VAL_ 1021 UI_donDisableAutoWiperDuration 5 "DON_DISABLE_AUTO_WIPER_DURATION_120_S" 2 "DON_DISABLE_AUTO_WIPER_DURATION_15_S" 3 "DON_DISABLE_AUTO_WIPER_DURATION_30_S" 1 "DON_DISABLE_AUTO_WIPER_DURATION_5_S" 4 "DON_DISABLE_AUTO_WIPER_DURATION_60_S" 0 "DON_DISABLE_AUTO_WIPER_DURATION_DEFAULT" 6 "DON_DISABLE_AUTO_WIPER_DURATION_OFF";
VAL_ 1021 UI_donDisableCutin 0 "DON_DISABLE_CUTIN_OFF" 1 "DON_DISABLE_CUTIN_ON";
VAL_ 1021 UI_donDisableOnAutoWiperSpeed 1 "DAS_WIPER_SPEED_1" 10 "DAS_WIPER_SPEED_10" 11 "DAS_WIPER_SPEED_11" 12 "DAS_WIPER_SPEED_12" 13 "DAS_WIPER_SPEED_13" 14 "DAS_WIPER_SPEED_14" 2 "DAS_WIPER_SPEED_2" 3 "DAS_WIPER_SPEED_3" 4 "DAS_WIPER_SPEED_4" 5 "DAS_WIPER_SPEED_5" 6 "DAS_WIPER_SPEED_6" 7 "DAS_WIPER_SPEED_7" 8 "DAS_WIPER_SPEED_8" 9 "DAS_WIPER_SPEED_9" 15 "DAS_WIPER_SPEED_INVALID" 0 "DAS_WIPER_SPEED_OFF";
VAL_ 1021 UI_donMinGoreWidthForAbortMap 2 "DON_MIN_GORE_WIDTH_FOR_ABORT_0P5_M" 1 "DON_MIN_GORE_WIDTH_FOR_ABORT_0_M" 4 "DON_MIN_GORE_WIDTH_FOR_ABORT_1P5_M" 3 "DON_MIN_GORE_WIDTH_FOR_ABORT_1_M" 6 "DON_MIN_GORE_WIDTH_FOR_ABORT_2P5_M" 5 "DON_MIN_GORE_WIDTH_FOR_ABORT_2_M" 8 "DON_MIN_GORE_WIDTH_FOR_ABORT_3P5_M" 7 "DON_MIN_GORE_WIDTH_FOR_ABORT_3_M" 10 "DON_MIN_GORE_WIDTH_FOR_ABORT_4P5_M" 9 "DON_MIN_GORE_WIDTH_FOR_ABORT_4_M" 11 "DON_MIN_GORE_WIDTH_FOR_ABORT_5_M" 0 "DON_MIN_GORE_WIDTH_FOR_ABORT_DEFAULT";
VAL_ 1021 UI_donMinGoreWidthForAbortNotMap 2 "DON_MIN_GORE_WIDTH_FOR_ABORT_0P5_M" 1 "DON_MIN_GORE_WIDTH_FOR_ABORT_0_M" 4 "DON_MIN_GORE_WIDTH_FOR_ABORT_1P5_M" 3 "DON_MIN_GORE_WIDTH_FOR_ABORT_1_M" 6 "DON_MIN_GORE_WIDTH_FOR_ABORT_2P5_M" 5 "DON_MIN_GORE_WIDTH_FOR_ABORT_2_M" 8 "DON_MIN_GORE_WIDTH_FOR_ABORT_3P5_M" 7 "DON_MIN_GORE_WIDTH_FOR_ABORT_3_M" 10 "DON_MIN_GORE_WIDTH_FOR_ABORT_4P5_M" 9 "DON_MIN_GORE_WIDTH_FOR_ABORT_4_M" 11 "DON_MIN_GORE_WIDTH_FOR_ABORT_5_M" 0 "DON_MIN_GORE_WIDTH_FOR_ABORT_DEFAULT";
VAL_ 1021 UI_donStopEndOfRampBuffer 1 "DON_STOP_END_OF_RAMP_BUFFER_15_M" 2 "DON_STOP_END_OF_RAMP_BUFFER_30_M" 3 "DON_STOP_END_OF_RAMP_BUFFER_45_M" 0 "DON_STOP_END_OF_RAMP_BUFFER_DEFAULT" 4 "DON_STOP_END_OF_RAMP_BUFFER_OFF";
VAL_ 1021 UI_homelinkNearby 1 "HOMELINK_NEARBY" 0 "HOMELINK_NOT_NEARBY";
VAL_ 1021 UI_hovEnabled 0 "HOV_OFF" 1 "HOV_ON";
VAL_ 611 VCRIGHT_logging10HzIndex 4 "END" 1 "HVAC_ACTUATOR_POSITIONS" 2 "HVAC_ACTUATOR_STATE" 0 "HVAC_ACTUATOR_TARGETS" 3 "HVAC_EVAP_PULLDOWN";
VAL_ 611 VCRIGHT_EvapPulldownBias 255 "SNA";
VAL_ 611 VCRIGHT_hvacIntakeActuatorState 0 "HVACACTUATOR_STATE_BRAKING" 2 "HVACACTUATOR_STATE_COASTING" 1 "HVACACTUATOR_STATE_RUNNING";
VAL_ 611 VCRIGHT_hvacIntakeOperationMode 1 "HVACACTUATOR_OPERATION_MODE_CALIBRATION" 0 "HVACACTUATOR_OPERATION_MODE_NORMAL";
VAL_ 611 VCRIGHT_hvacLHBleedActuatorState 0 "HVACACTUATOR_STATE_BRAKING" 2 "HVACACTUATOR_STATE_COASTING" 1 "HVACACTUATOR_STATE_RUNNING";
VAL_ 611 VCRIGHT_hvacLHBleedOperationMode 1 "HVACACTUATOR_OPERATION_MODE_CALIBRATION" 0 "HVACACTUATOR_OPERATION_MODE_NORMAL";
VAL_ 611 VCRIGHT_hvacLHVaneActuatorState 0 "HVACACTUATOR_STATE_BRAKING" 2 "HVACACTUATOR_STATE_COASTING" 1 "HVACACTUATOR_STATE_RUNNING";
VAL_ 611 VCRIGHT_hvacLHVaneOperationMode 1 "HVACACTUATOR_OPERATION_MODE_CALIBRATION" 0 "HVACACTUATOR_OPERATION_MODE_NORMAL";
VAL_ 611 VCRIGHT_hvacLowerModeActState 0 "HVACACTUATOR_STATE_BRAKING" 2 "HVACACTUATOR_STATE_COASTING" 1 "HVACACTUATOR_STATE_RUNNING";
VAL_ 611 VCRIGHT_hvacLowerModeOpMode 1 "HVACACTUATOR_OPERATION_MODE_CALIBRATION" 0 "HVACACTUATOR_OPERATION_MODE_NORMAL";
VAL_ 611 VCRIGHT_hvacRHBleedActuatorState 0 "HVACACTUATOR_STATE_BRAKING" 2 "HVACACTUATOR_STATE_COASTING" 1 "HVACACTUATOR_STATE_RUNNING";
VAL_ 611 VCRIGHT_hvacRHBleedOperationMode 1 "HVACACTUATOR_OPERATION_MODE_CALIBRATION" 0 "HVACACTUATOR_OPERATION_MODE_NORMAL";
VAL_ 611 VCRIGHT_hvacRHVaneActuatorState 0 "HVACACTUATOR_STATE_BRAKING" 2 "HVACACTUATOR_STATE_COASTING" 1 "HVACACTUATOR_STATE_RUNNING";
VAL_ 611 VCRIGHT_hvacRHVaneOperationMode 1 "HVACACTUATOR_OPERATION_MODE_CALIBRATION" 0 "HVACACTUATOR_OPERATION_MODE_NORMAL";
VAL_ 611 VCRIGHT_hvacUpperModeActState 0 "HVACACTUATOR_STATE_BRAKING" 2 "HVACACTUATOR_STATE_COASTING" 1 "HVACACTUATOR_STATE_RUNNING";
VAL_ 611 VCRIGHT_hvacUpperModeOpMode 1 "HVACACTUATOR_OPERATION_MODE_CALIBRATION" 0 "HVACACTUATOR_OPERATION_MODE_NORMAL";
VAL_ 615 DI_massConfidence 1 "MASS_CONFIDED" 0 "MASS_NOT_CONFIDED";
VAL_ 615 DI_relativeTireTreadDepth 32 "SNA";
VAL_ 615 DI_tireFitment 3 "FITMENT_SNA" 0 "FITMENT_SQUARE" 1 "FITMENT_STAGGERED";
VAL_ 615 DI_trailerDetected 1 "TRAILER_DETECTED" 0 "TRAILER_NOT_DETECTED";
VAL_ 642 VCLEFT_blowerIndex 0 "HVAC_FEEDBACK_SIGNALS" 1 "HVAC_VARS";
VAL_ 642 VCLEFT_hvacBlowerCBCCtrlState 4 "COUNT" 0 "ERROR" 1 "IDLE" 2 "OFFLINE" 3 "ONLINE";
VAL_ 642 VCLEFT_hvacBlowerCBCEstState 14 "COUNT" 0 "ERROR" 1 "IDLE" 5 "IDRATED" 10 "INDUCTANCE_EST" 9 "LOCKROTOR" 12 "MOTOR_IDENTIFIED" 13 "ONLINE" 8 "RAMPDOWN" 4 "RAMPUP" 7 "RATEDFLUX" 6 "RATEDFLUX_OL" 11 "ROTOR_RESISTANCE" 2 "ROVERL" 3 "RS";
VAL_ 642 VCLEFT_hvacBlowerFETTemp 127 "SNA";
VAL_ 642 VCLEFT_hvacBlowerIPhase0 255 "SNA";
VAL_ 642 VCLEFT_hvacBlowerIPhase1 255 "SNA";
VAL_ 642 VCLEFT_hvacBlowerIPhase2 255 "SNA";
VAL_ 642 VCLEFT_hvacBlowerITerm 127 "SNA";
VAL_ 642 VCLEFT_hvacBlowerOutputDuty 127 "SNA";
VAL_ 642 VCLEFT_hvacBlowerRPMTarget 1023 "SNA";
VAL_ 642 VCLEFT_hvacBlowerRs 255 "SNA";
VAL_ 642 VCLEFT_hvacBlowerTorque 1023 "SNA";
VAL_ 642 VCLEFT_hvacBlower_IO_CBC_Status 0 "IDLE" 1 "RX";
VAL_ 755 UI_hvacReqACDisable 0 "AUTO" 1 "OFF" 2 "ON";
VAL_ 755 UI_hvacReqAirDistributionMode 0 "AUTO" 4 "MANUAL_DEFROST" 5 "MANUAL_DEFROST_FLOOR" 6 "MANUAL_DEFROST_PANEL" 7 "MANUAL_DEFROST_PANEL_FLOOR" 1 "MANUAL_FLOOR" 2 "MANUAL_PANEL" 3 "MANUAL_PANEL_FLOOR";
VAL_ 755 UI_hvacReqBlowerSegment 1 "1" 10 "10" 2 "2" 3 "3" 4 "4" 5 "5" 6 "6" 7 "7" 8 "8" 9 "9" 11 "AUTO" 0 "OFF";
VAL_ 755 UI_hvacReqKeepClimateOn 2 "KEEP_CLIMATE_ON_REQ_DOG" 0 "KEEP_CLIMATE_ON_REQ_OFF" 1 "KEEP_CLIMATE_ON_REQ_ON" 3 "KEEP_CLIMATE_ON_REQ_PARTY";
VAL_ 755 UI_hvacReqManualDefogState 1 "DEFOG" 2 "DEFROST" 0 "NONE";
VAL_ 755 UI_hvacReqRecirc 0 "AUTO" 2 "FRESH" 1 "RECIRC";
VAL_ 755 UI_hvacReqSecondRowState 0 "AUTO" 4 "HIGH" 2 "LOW" 3 "MED" 1 "OFF";
VAL_ 755 UI_hvacReqTempSetpointLeft 26 "HI" 0 "LO";
VAL_ 755 UI_hvacReqTempSetpointRight 26 "HI" 0 "LO";
VAL_ 755 UI_hvacReqUserPowerState 0 "OFF" 1 "ON" 4 "OVERHEAT_PROTECT" 3 "OVERHEAT_PROTECT_FANONLY" 2 "PRECONDITION";
VAL_ 787 UI_trackCmpOverclock 0 "TRACK_MODE_CMP_OVERCLOCK_OFF" 1 "TRACK_MODE_CMP_OVERCLOCK_ON";
VAL_ 787 UI_trackModeRequest 0 "TRACK_MODE_REQUEST_IDLE" 2 "TRACK_MODE_REQUEST_OFF" 1 "TRACK_MODE_REQUEST_ON";
VAL_ 787 UI_trackPostCooling 0 "TRACK_MODE_POST_COOLING_OFF" 1 "TRACK_MODE_POST_COOLING_ON";
VAL_ 821 DIR_infoIndex 13 "DI_INFO_APP_CRC" 17 "DI_INFO_APP_GITHASH" 15 "DI_INFO_BOOTLOADER_CRC" 18 "DI_INFO_BOOTLOADER_GITHASH" 14 "DI_INFO_BOOTLOADER_SVN" 10 "DI_INFO_BUILD_HWID_COMPONENTID" 0 "DI_INFO_DEPRECATED_0" 1 "DI_INFO_DEPRECATED_1" 2 "DI_INFO_DEPRECATED_2" 3 "DI_INFO_DEPRECATED_3" 4 "DI_INFO_DEPRECATED_4" 5 "DI_INFO_DEPRECATED_5" 6 "DI_INFO_DEPRECATED_6" 7 "DI_INFO_DEPRECATED_7" 8 "DI_INFO_DEPRECATED_8" 9 "DI_INFO_DEPRECATED_9" 255 "DI_INFO_END" 11 "DI_INFO_PCBAID_ASSYID_USAGEID" 16 "DI_INFO_SUBCOMPONENT" 23 "DI_INFO_SUBCOMPONENT2" 31 "DI_INFO_SUBCOMPONENT_GITHASH" 20 "DI_INFO_UDS_PROTOCOL_BOOTCRC" 19 "DI_INFO_VERSION_DEPRECATED";
VAL_ 821 DIR_FPGA_version 254 "FPGA_VERSION_LOCAL_BUILD" 255 "FPGA_VERSION_SNA";
VAL_ 821 DIR_buildType 2 "INFO_LOCAL_BUILD" 4 "INFO_MFG_BUILD" 1 "INFO_PLATFORM_BUILD" 3 "INFO_TRACEABLE_CI_BUILD" 0 "INFO_UNKNOWN_BUILD";
VAL_ 821 DIR_hardwareId 252 "CONFIGURABLE_HWID_PLACEHOLDER";
VAL_ 821 DIR_oilPumpBuildType 2 "INFO_LOCAL_BUILD" 4 "INFO_MFG_BUILD" 1 "INFO_PLATFORM_BUILD" 3 "INFO_TRACEABLE_CI_BUILD" 0 "INFO_UNKNOWN_BUILD";
VAL_ 899 VCRIGHT_estimatedThsSolarLoad 1023 "SNA";
VAL_ 899 VCRIGHT_estimatedVehicleSituatio 1 "VEHICLE_SITUATION_INDOOR" 2 "VEHICLE_SITUATION_OUTDOOR" 0 "VEHICLE_SITUATION_UNKNOWN";
VAL_ 899 VCRIGHT_thsHumidity 255 "SNA";
VAL_ 899 VCRIGHT_thsSolarLoadInfrared 1023 "SNA";
VAL_ 899 VCRIGHT_thsSolarLoadVisible 1023 "SNA";
VAL_ 899 VCRIGHT_thsTemperature 128 "SNA";
VAL_ 915 VCRIGHT_epbmDebugIndex 2 "EPBM_HVDISCONNECT" 0 "EPBM_STATES" 1 "EPBM_TRANSITIONS";
VAL_ 915 VCRIGHT_cdpEnumDummy 0 "EPB_EXTERNAL_APPLY_IDLE" 2 "EPB_EXTERNAL_APPLY_INVALID" 1 "EPB_EXTERNAL_APPLY_VALID";
VAL_ 915 VCRIGHT_epbFaultStatus 2 "EPB_STATUS_FAULT" 3 "EPB_STATUS_FAULT_IDLE" 0 "EPB_STATUS_NOMINAL" 1 "EPB_STATUS_RETRY";
VAL_ 915 VCRIGHT_epbSummonState 3 "EPB_SUMMON_ACTIVE" 2 "EPB_SUMMON_ARMED" 4 "EPB_SUMMON_COMPLETE" 5 "EPB_SUMMON_FAULT" 1 "EPB_SUMMON_IDLE" 0 "EPB_SUMMON_INIT" 6 "EPB_SUMMON_UNAVAILABLE";
VAL_ 915 VCRIGHT_epbUnitStatus 22 "EPB_STATUS_COUNT" 2 "EPB_STATUS_DYNAMIC" 9 "EPB_STATUS_DYNAMIC_APPLYING" 20 "EPB_STATUS_DYNAMIC_PARKING" 17 "EPB_STATUS_EXTERNAL_DYNAMIC" 19 "EPB_STATUS_EXTERNAL_PARKING" 21 "EPB_STATUS_FREE_ROLL_MODE" 1 "EPB_STATUS_OPEN" 3 "EPB_STATUS_PARK" 8 "EPB_STATUS_PARKING" 12 "EPB_STATUS_PARK_PENDING" 10 "EPB_STATUS_RELEASING" 18 "EPB_STATUS_RELEASING_FOR_EXTERNAL_PARK" 5 "EPB_STATUS_SERVICE" 11 "EPB_STATUS_SERVICE_RELEASING" 4 "EPB_STATUS_START" 14 "EPB_STATUS_SUMMON" 16 "EPB_STATUS_SUMMON_PARKING" 15 "EPB_STATUS_SUMMON_RELEASING" 0 "EPB_STATUS_UNKNOWN" 6 "EPB_STATUS_WINCHMODE" 13 "EPB_STATUS_WINCHMODE_PENDING" 7 "EPB_STATUS_WINCHMODE_RELEASING";
VAL_ 915 VCRIGHT_epbmCaliperState 4 "EPB_SAVED_CALIPERSTATE_OPEN" 3 "EPB_SAVED_CALIPERSTATE_PARK" 2 "EPB_SAVED_CALIPERSTATE_REAPPLY" 5 "EPB_SAVED_CALIPERSTATE_SERVICE" 1 "EPB_SAVED_CALIPERSTATE_UNKNOWN" 0 "EPB_SAVED_CALIPERSTATE_UNSAVED" 6 "EPB_SAVED_CALIPERSTATE_WINCHMODE";
VAL_ 915 VCRIGHT_epbmFaultStatus 2 "EPB_STATUS_FAULT" 3 "EPB_STATUS_FAULT_IDLE" 0 "EPB_STATUS_NOMINAL" 1 "EPB_STATUS_RETRY";
VAL_ 915 VCRIGHT_epbmSummonState 3 "EPB_SUMMON_ACTIVE" 2 "EPB_SUMMON_ARMED" 4 "EPB_SUMMON_COMPLETE" 5 "EPB_SUMMON_FAULT" 1 "EPB_SUMMON_IDLE" 0 "EPB_SUMMON_INIT" 6 "EPB_SUMMON_UNAVAILABLE";
VAL_ 915 VCRIGHT_epbmSystemStatus 3 "EPB_VEHICLE_STATUS_DYNAMIC" 6 "EPB_VEHICLE_STATUS_FAULT" 7 "EPB_VEHICLE_STATUS_FAULT_SECURE" 8 "EPB_VEHICLE_STATUS_MISMATCH" 2 "EPB_VEHICLE_STATUS_PARKED" 4 "EPB_VEHICLE_STATUS_PARKING" 1 "EPB_VEHICLE_STATUS_RELEASED" 5 "EPB_VEHICLE_STATUS_RELEASING" 0 "EPB_VEHICLE_STATUS_UNKNOWN";
VAL_ 915 VCRIGHT_summonFaultReason 7 "EPB_SUMMONFAULT_DAS_FAULT" 2 "EPB_SUMMONFAULT_DAS_MIA" 6 "EPB_SUMMONFAULT_DI_APC_FAULT" 5 "EPB_SUMMONFAULT_DI_FAULT" 1 "EPB_SUMMONFAULT_DI_MIA" 20 "EPB_SUMMONFAULT_DI_STATE_INVALID" 10 "EPB_SUMMONFAULT_EAC_NOT_ALLOWED" 4 "EPB_SUMMONFAULT_EPBM_MIA" 11 "EPB_SUMMONFAULT_EPBM_REQUEST" 22 "EPB_SUMMONFAULT_EPBREMOTE_MIA" 19 "EPB_SUMMONFAULT_EPB_FAULT" 8 "EPB_SUMMONFAULT_ESP_FAULT" 3 "EPB_SUMMONFAULT_ESP_MIA" 13 "EPB_SUMMONFAULT_EXTERNAL" 27 "EPB_SUMMONFAULT_INVALID_REMOTE_STATE" 24 "EPB_SUMMONFAULT_LOCAL_UNIT_FAULTED" 18 "EPB_SUMMONFAULT_MISMATCH" 0 "EPB_SUMMONFAULT_NONE" 17 "EPB_SUMMONFAULT_OOC" 14 "EPB_SUMMONFAULT_PARK_MIA" 21 "EPB_SUMMONFAULT_PASSIVE_REQUEST" 15 "EPB_SUMMONFAULT_PM_MIA" 16 "EPB_SUMMONFAULT_PM_REQUEST" 28 "EPB_SUMMONFAULT_REMOTE_DID_NOT_START" 23 "EPB_SUMMONFAULT_REMOTE_SUMMON_FAULTED" 25 "EPB_SUMMONFAULT_REMOTE_UNIT_FAULTED" 12 "EPB_SUMMONFAULT_SPEED" 26 "EPB_SUMMONFAULT_START_IN_UNAVAILABLE" 9 "EPB_SUMMONFAULT_VEH_CAN_FAULT";
VAL_ 947 UI_autopilotPowerStateRequest 0 "AUTOPILOT_NOMINAL" 1 "AUTOPILOT_SENTRY" 2 "AUTOPILOT_SUSPEND";
VAL_ 947 UI_lightSwitch 0 "LIGHT_SWITCH_AUTO" 3 "LIGHT_SWITCH_OFF" 1 "LIGHT_SWITCH_ON" 2 "LIGHT_SWITCH_PARKING" 4 "LIGHT_SWITCH_SNA";
VAL_ 947 UI_shorted12VCellTestMode 2 "SHORTED_CELL_TEST_MODE_ACTIVE" 0 "SHORTED_CELL_TEST_MODE_DISABLED" 1 "SHORTED_CELL_TEST_MODE_SHADOW";
VAL_ 947 UI_summonState 3 "ACTIVE" 1 "IDLE" 2 "PRE_PRIMED" 0 "SNA";
VAL_ 947 UI_windowRequest 3 "WINDOW_REQUEST_GOTO_CLOSED" 4 "WINDOW_REQUEST_GOTO_OPEN" 1 "WINDOW_REQUEST_GOTO_PERCENT" 2 "WINDOW_REQUEST_GOTO_VENT" 0 "WINDOW_REQUEST_IDLE";
VAL_ 963 VCRIGHT_frontBuckleSwitch 3 "SWITCH_FAULT" 1 "SWITCH_OFF" 2 "SWITCH_ON" 0 "SWITCH_SNA";
VAL_ 963 VCRIGHT_frontOccupancySwitch 3 "SWITCH_FAULT" 1 "SWITCH_OFF" 2 "SWITCH_ON" 0 "SWITCH_SNA";
VAL_ 963 VCRIGHT_frontSeatBackrestBack 3 "SWITCH_FAULT" 1 "SWITCH_OFF" 2 "SWITCH_ON" 0 "SWITCH_SNA";
VAL_ 963 VCRIGHT_frontSeatBackrestForward 3 "SWITCH_FAULT" 1 "SWITCH_OFF" 2 "SWITCH_ON" 0 "SWITCH_SNA";
VAL_ 963 VCRIGHT_frontSeatLiftDown 3 "SWITCH_FAULT" 1 "SWITCH_OFF" 2 "SWITCH_ON" 0 "SWITCH_SNA";
VAL_ 963 VCRIGHT_frontSeatLiftUp 3 "SWITCH_FAULT" 1 "SWITCH_OFF" 2 "SWITCH_ON" 0 "SWITCH_SNA";
VAL_ 963 VCRIGHT_frontSeatLumbarDown 3 "SWITCH_FAULT" 1 "SWITCH_OFF" 2 "SWITCH_ON" 0 "SWITCH_SNA";
VAL_ 963 VCRIGHT_frontSeatLumbarIn 3 "SWITCH_FAULT" 1 "SWITCH_OFF" 2 "SWITCH_ON" 0 "SWITCH_SNA";
VAL_ 963 VCRIGHT_frontSeatLumbarOut 3 "SWITCH_FAULT" 1 "SWITCH_OFF" 2 "SWITCH_ON" 0 "SWITCH_SNA";
VAL_ 963 VCRIGHT_frontSeatLumbarUp 3 "SWITCH_FAULT" 1 "SWITCH_OFF" 2 "SWITCH_ON" 0 "SWITCH_SNA";
VAL_ 963 VCRIGHT_frontSeatTiltDown 3 "SWITCH_FAULT" 1 "SWITCH_OFF" 2 "SWITCH_ON" 0 "SWITCH_SNA";
VAL_ 963 VCRIGHT_frontSeatTiltUp 3 "SWITCH_FAULT" 1 "SWITCH_OFF" 2 "SWITCH_ON" 0 "SWITCH_SNA";
VAL_ 963 VCRIGHT_frontSeatTrackBack 3 "SWITCH_FAULT" 1 "SWITCH_OFF" 2 "SWITCH_ON" 0 "SWITCH_SNA";
VAL_ 963 VCRIGHT_frontSeatTrackForward 3 "SWITCH_FAULT" 1 "SWITCH_OFF" 2 "SWITCH_ON" 0 "SWITCH_SNA";
VAL_ 963 VCRIGHT_rearCenterBuckleSwitch 3 "SWITCH_FAULT" 1 "SWITCH_OFF" 2 "SWITCH_ON" 0 "SWITCH_SNA";
VAL_ 963 VCRIGHT_rearRightBuckleSwitch 3 "SWITCH_FAULT" 1 "SWITCH_OFF" 2 "SWITCH_ON" 0 "SWITCH_SNA";
VAL_ 995 VCRIGHT_brakeLightStatus 2 "LIGHT_FAULT" 0 "LIGHT_OFF" 1 "LIGHT_ON" 3 "LIGHT_SNA";
VAL_ 995 VCRIGHT_interiorTrunkLightStatus 2 "LIGHT_FAULT" 0 "LIGHT_OFF" 1 "LIGHT_ON" 3 "LIGHT_SNA";
VAL_ 995 VCRIGHT_rearFogLightStatus 2 "LIGHT_FAULT" 0 "LIGHT_OFF" 1 "LIGHT_ON" 3 "LIGHT_SNA";
VAL_ 995 VCRIGHT_reverseLightStatus 2 "LIGHT_FAULT" 0 "LIGHT_OFF" 1 "LIGHT_ON" 3 "LIGHT_SNA";
VAL_ 995 VCRIGHT_tailLightStatus 2 "LIGHT_FAULT" 0 "LIGHT_OFF" 1 "LIGHT_ON" 3 "LIGHT_SNA";
VAL_ 995 VCRIGHT_turnSignalStatus 2 "LIGHT_FAULT" 0 "LIGHT_OFF" 1 "LIGHT_ON" 3 "LIGHT_SNA";
VAL_ 1622 DIF_infoIndex 13 "DI_INFO_APP_CRC" 17 "DI_INFO_APP_GITHASH" 15 "DI_INFO_BOOTLOADER_CRC" 18 "DI_INFO_BOOTLOADER_GITHASH" 14 "DI_INFO_BOOTLOADER_SVN" 10 "DI_INFO_BUILD_HWID_COMPONENTID" 0 "DI_INFO_DEPRECATED_0" 1 "DI_INFO_DEPRECATED_1" 2 "DI_INFO_DEPRECATED_2" 3 "DI_INFO_DEPRECATED_3" 4 "DI_INFO_DEPRECATED_4" 5 "DI_INFO_DEPRECATED_5" 6 "DI_INFO_DEPRECATED_6" 7 "DI_INFO_DEPRECATED_7" 8 "DI_INFO_DEPRECATED_8" 9 "DI_INFO_DEPRECATED_9" 255 "DI_INFO_END" 11 "DI_INFO_PCBAID_ASSYID_USAGEID" 16 "DI_INFO_SUBCOMPONENT" 23 "DI_INFO_SUBCOMPONENT2" 31 "DI_INFO_SUBCOMPONENT_GITHASH" 20 "DI_INFO_UDS_PROTOCOL_BOOTCRC" 19 "DI_INFO_VERSION_DEPRECATED";
VAL_ 1622 DIF_FPGA_version 254 "FPGA_VERSION_LOCAL_BUILD" 255 "FPGA_VERSION_SNA";
VAL_ 1622 DIF_buildType 2 "INFO_LOCAL_BUILD" 4 "INFO_MFG_BUILD" 1 "INFO_PLATFORM_BUILD" 3 "INFO_TRACEABLE_CI_BUILD" 0 "INFO_UNKNOWN_BUILD";
VAL_ 1622 DIF_hardwareId 252 "CONFIGURABLE_HWID_PLACEHOLDER";
VAL_ 1622 DIF_oilPumpBuildType 2 "INFO_LOCAL_BUILD" 4 "INFO_MFG_BUILD" 1 "INFO_PLATFORM_BUILD" 3 "INFO_TRACEABLE_CI_BUILD" 0 "INFO_UNKNOWN_BUILD";
VAL_ 768 BMS_infoIndex 13 "INFO_APP_CRC" 17 "INFO_APP_GITHASH" 15 "INFO_BOOTLOADER_CRC" 18 "INFO_BOOTLOADER_GITHASH" 14 "INFO_BOOTLOADER_SVN" 10 "INFO_BUILD_HWID_COMPONENTID" 0 "INFO_DEPRECATED_0" 1 "INFO_DEPRECATED_1" 2 "INFO_DEPRECATED_2" 3 "INFO_DEPRECATED_3" 4 "INFO_DEPRECATED_4" 5 "INFO_DEPRECATED_5" 6 "INFO_DEPRECATED_6" 7 "INFO_DEPRECATED_7" 8 "INFO_DEPRECATED_8" 9 "INFO_DEPRECATED_9" 255 "INFO_END" 27 "INFO_PACKAGE_PN_15_20" 25 "INFO_PACKAGE_PN_1_7" 26 "INFO_PACKAGE_PN_8_14" 29 "INFO_PACKAGE_SN_1_7" 30 "INFO_PACKAGE_SN_8_14" 11 "INFO_PCBAID_ASSYID_USAGEID" 16 "INFO_SUBCOMPONENT" 31 "INFO_SUBCOMPONENT_GITHASH" 20 "INFO_UDS_PROTOCOL_BOOTCRC" 22 "INFO_VARIANTCRC" 19 "INFO_VERSION_DEPRECATED";
VAL_ 768 BMS_buildType 2 "INFO_LOCAL_BUILD" 4 "INFO_MFG_BUILD" 1 "INFO_PLATFORM_BUILD" 3 "INFO_TRACEABLE_CI_BUILD" 0 "INFO_UNKNOWN_BUILD";
VAL_ 530 BMS_chgPowerAvailable 2047 "SNA";
VAL_ 530 BMS_contactorState 6 "BMS_CTRSET_BLOCKED" 4 "BMS_CTRSET_CLOSED" 3 "BMS_CTRSET_CLOSING" 1 "BMS_CTRSET_OPEN" 2 "BMS_CTRSET_OPENING" 0 "BMS_CTRSET_SNA" 5 "BMS_CTRSET_WELDED";
VAL_ 530 BMS_diLimpRequest 0 "LIMP_REQUEST_NONE" 1 "LIMP_REQUEST_WELDED";
VAL_ 530 BMS_ecuLogUploadRequest 1 "REQUEST_PRIORITY_1" 2 "REQUEST_PRIORITY_2" 3 "REQUEST_PRIORITY_3" 0 "REQUEST_PRIORITY_NONE";
VAL_ 530 BMS_hvState 1 "HV_COMING_UP" 0 "HV_DOWN" 2 "HV_GOING_DOWN" 6 "HV_UP" 4 "HV_UP_FOR_CHARGE" 5 "HV_UP_FOR_DC_CHARGE" 3 "HV_UP_FOR_DRIVE";
VAL_ 530 BMS_isolationResistance 1023 "SNA";
VAL_ 530 BMS_smStateRequest 3 "BMS_CHARGE" 5 "BMS_CLEAR_FAULT" 10 "BMS_DIAG" 1 "BMS_DRIVE" 6 "BMS_FAULT" 4 "BMS_FEIM" 9 "BMS_SNA" 0 "BMS_STANDBY" 2 "BMS_SUPPORT" 8 "BMS_TEST" 7 "BMS_WELD";
VAL_ 530 BMS_state 3 "BMS_CHARGE" 5 "BMS_CLEAR_FAULT" 10 "BMS_DIAG" 1 "BMS_DRIVE" 6 "BMS_FAULT" 4 "BMS_FEIM" 9 "BMS_SNA" 0 "BMS_STANDBY" 2 "BMS_SUPPORT" 8 "BMS_TEST" 7 "BMS_WELD";
VAL_ 530 BMS_uiChargeStatus 2 "BMS_ABOUT_TO_CHARGE" 4 "BMS_CHARGE_COMPLETE" 5 "BMS_CHARGE_STOPPED" 3 "BMS_CHARGING" 0 "BMS_DISCONNECTED" 1 "BMS_NO_POWER";
VAL_ 946 BMS_log2MuxId 9 "BMS_LOG2_100HZ_1KHZ_TASK_STATS" 8 "BMS_LOG2_10HZ_TASK_STATS" 7 "BMS_LOG2_1HZ_TASK_STATS" 6 "BMS_LOG2_AHR_COUNTER" 24 "BMS_LOG2_BRICK_VOLTAGE_CHANGE" 0 "BMS_LOG2_CAC1" 1 "BMS_LOG2_CAC2" 23 "BMS_LOG2_CAC3" 3 "BMS_LOG2_CHARGE_TERMINATION" 5 "BMS_LOG2_CHARGING" 10 "BMS_LOG2_CTR_RESISTANCE" 22 "BMS_LOG2_ENERGY_AND_REST_DATA" 20 "BMS_LOG2_ENERGY_RESERVE" 21 "BMS_LOG2_FC_LINK_LEAKAGE_TEST" 2 "BMS_LOG2_FLOOD_PORT" 19 "BMS_LOG2_HV_CHAIN_MODEL" 15 "BMS_LOG2_NEG_CTR_HEALTH_1" 16 "BMS_LOG2_NEG_CTR_HEALTH_2" 17 "BMS_LOG2_NEG_CTR_HEALTH_3" 18 "BMS_LOG2_NEG_CTR_HEALTH_4" 11 "BMS_LOG2_POS_CTR_HEALTH_1" 12 "BMS_LOG2_POS_CTR_HEALTH_2" 13 "BMS_LOG2_POS_CTR_HEALTH_3" 14 "BMS_LOG2_POS_CTR_HEALTH_4" 25 "BMS_LOG2_SOC_BY_OCV_CORRECTION" 4 "BMS_LOG2_VSH_TEST";
VAL_ 946 BMS_chargeCurrentLimitMode 1 "BMS_CHG_I_LIMIT_BRICK_TEMP_AND_V" 2 "BMS_CHG_I_LIMIT_CAC_IMBALANCE" 5 "BMS_CHG_I_LIMIT_CONFIG" 6 "BMS_CHG_I_LIMIT_HV_CHAIN" 3 "BMS_CHG_I_LIMIT_LEAKY_BUCKET" 0 "BMS_CHG_I_LIMIT_NONE" 4 "BMS_CHG_I_LIMIT_TETHERING";
VAL_ 946 BMS_chargeNeededReason 6 "BMS_BRICKV_LESS_THAN_FULL_CHARGE" 4 "BMS_CABLE_CYCLE_TOP_OFF" 3 "BMS_CHARGE_TARGET_INCREASED" 2 "BMS_DCH_KWH_THRESHOLD" 0 "BMS_NO_CHARGE_REASON" 1 "BMS_SOC_LESS_THAN_UI_THRESHOLD";
VAL_ 946 BMS_chgEndBmsHvChargeStatus 4 "BMS_CHARGE_ENABLED" 3 "BMS_CHARGE_ENABLING" 7 "BMS_CHARGE_FAULTED" 0 "BMS_CHARGE_STANDBY" 6 "BMS_EMERGENCY_SHUTDOWN" 1 "BMS_EXT_EVSE_TEST_ALLOWED" 2 "BMS_EXT_PRECHARGE_ALLOWED" 5 "BMS_GRACEFUL_SHUTDOWN";
VAL_ 946 BMS_chgEndChargeState 7 "CHARGE_STATE_AC_DISABLE_PCS" 4 "CHARGE_STATE_AC_ENABLE_PCS" 5 "CHARGE_STATE_CHARGING_ACTIVE" 6 "CHARGE_STATE_DC_DISABLING_CHARGER" 3 "CHARGE_STATE_DC_ENABLE_FCLINK" 2 "CHARGE_STATE_DC_EXT_ISO_CHECK" 1 "CHARGE_STATE_ENABLE_DCLINK" 0 "CHARGE_STATE_INACTIVE";
VAL_ 946 BMS_chgEndCpHvChargeStatus 1 "CP_CHARGE_CONNECTED" 5 "CP_CHARGE_ENABLED" 6 "CP_CHARGE_FAULTED" 0 "CP_CHARGE_INACTIVE" 2 "CP_CHARGE_STANDBY" 4 "CP_EVSE_TEST_PASSED" 3 "CP_EXT_EVSE_TEST_ACTIVE";
VAL_ 946 BMS_chgEndCpShutdownRequest 2 "EMERGENCY_SHUTDOWN_REQUESTED" 1 "GRACEFUL_SHUTDOWN_REQUESTED" 0 "NO_SHUTDOWN_REQUESTED";
VAL_ 946 BMS_chgEndEvseChargeType 2 "AC_CHARGER_PRESENT" 1 "DC_CHARGER_PRESENT" 0 "NO_CHARGER_PRESENT";
VAL_ 946 BMS_chgEndPcsHvChargeStatus 1 "PCS_CHARGE_BLOCKED" 2 "PCS_CHARGE_ENABLED" 3 "PCS_CHARGE_FAULTED" 0 "PCS_CHARGE_STANDBY";
VAL_ 946 BMS_chgEndPcsShutdownRequest 2 "EMERGENCY_SHUTDOWN_REQUESTED" 1 "GRACEFUL_SHUTDOWN_REQUESTED" 0 "NO_SHUTDOWN_REQUESTED";
VAL_ 946 BMS_cpChargeStatus 1 "BMS_CHARGING_ACTIVE" 2 "BMS_CHARGING_COMPLETE" 4 "BMS_CHARGING_ENABLING" 3 "BMS_CHARGING_FAULT" 0 "BMS_CHARGING_INACTIVE" 5 "BMS_CHARGING_UPDATE_IN_PROGRESS";
VAL_ 946 BMS_dynamicEnergyBuffer 1023 "SNA";
VAL_ 946 BMS_fcLinkTestDecayTime 1023 "SNA";
VAL_ 946 BMS_floodPortState1 2 "FLOOD_PORT_STATE_CLOSED" 4 "FLOOD_PORT_STATE_ERROR_HIGH" 1 "FLOOD_PORT_STATE_ERROR_LOW" 3 "FLOOD_PORT_STATE_OPEN" 0 "FLOOD_PORT_STATE_SNA";
VAL_ 946 BMS_floodPortState2 2 "FLOOD_PORT_STATE_CLOSED" 4 "FLOOD_PORT_STATE_ERROR_HIGH" 1 "FLOOD_PORT_STATE_ERROR_LOW" 3 "FLOOD_PORT_STATE_OPEN" 0 "FLOOD_PORT_STATE_SNA";
VAL_ 946 BMS_idealEnergyFloor 1023 "SNA";
VAL_ 946 BMS_negCtrCommonModeRejError 4096 "SNA";
VAL_ 946 BMS_negCtrCommonModeRejErrorConf 8191 "SNA";
VAL_ 946 BMS_negCtrDeviationConfidenceMax 8191 "SNA";
VAL_ 946 BMS_negCtrDeviationConfidenceMin 8191 "SNA";
VAL_ 946 BMS_negCtrDeviationFiltConfMax 8191 "SNA";
VAL_ 946 BMS_negCtrDeviationFiltConfMin 8191 "SNA";
VAL_ 946 BMS_negCtrDeviationFiltMax 4096 "SNA";
VAL_ 946 BMS_negCtrDeviationFiltMin 4096 "SNA";
VAL_ 946 BMS_negCtrDeviationMax 4096 "SNA";
VAL_ 946 BMS_negCtrDeviationMin 4096 "SNA";
VAL_ 946 BMS_negCtrDropCorrectedFiltMax 4096 "SNA";
VAL_ 946 BMS_negCtrDropCorrectedFiltMin 4096 "SNA";
VAL_ 946 BMS_negCtrDropCorrectedMax 4096 "SNA";
VAL_ 946 BMS_negCtrDropCorrectedMin 4096 "SNA";
VAL_ 946 BMS_negCtrOffsetError 4096 "SNA";
VAL_ 946 BMS_negCtrOffsetErrorConf 8191 "SNA";
VAL_ 946 BMS_negCtrResistance 4096 "SNA";
VAL_ 946 BMS_negCtrResistanceConfidence 8191 "SNA";
VAL_ 946 BMS_posCtrCommonModeRejError 4096 "SNA";
VAL_ 946 BMS_posCtrCommonModeRejErrorConf 8191 "SNA";
VAL_ 946 BMS_posCtrDeviationConfidenceMax 8191 "SNA";
VAL_ 946 BMS_posCtrDeviationConfidenceMin 8191 "SNA";
VAL_ 946 BMS_posCtrDeviationFiltConfMax 8191 "SNA";
VAL_ 946 BMS_posCtrDeviationFiltConfMin 8191 "SNA";
VAL_ 946 BMS_posCtrDeviationFiltMax 4096 "SNA";
VAL_ 946 BMS_posCtrDeviationFiltMin 4096 "SNA";
VAL_ 946 BMS_posCtrDeviationMax 4096 "SNA";
VAL_ 946 BMS_posCtrDeviationMin 4096 "SNA";
VAL_ 946 BMS_posCtrDropCorrectedFiltMax 4096 "SNA";
VAL_ 946 BMS_posCtrDropCorrectedFiltMin 4096 "SNA";
VAL_ 946 BMS_posCtrDropCorrectedMax 4096 "SNA";
VAL_ 946 BMS_posCtrDropCorrectedMin 4096 "SNA";
VAL_ 946 BMS_posCtrOffsetError 4096 "SNA";
VAL_ 946 BMS_posCtrOffsetErrorConf 8191 "SNA";
VAL_ 946 BMS_posCtrResistance 4096 "SNA";
VAL_ 946 BMS_posCtrResistanceConfidence 8191 "SNA";
VAL_ 800 BMS_matrixIndex 0 "BMS_AlertMatrix0" 1 "BMS_AlertMatrix1" 2 "BMS_AlertMatrix2";
VAL_ 796 CC_currentLimit 255 "SNA";
VAL_ 796 CC_gridGrounding 1 "CC_GRID_GROUNDING_IT_SplitPhase" 2 "CC_GRID_GROUNDING_SNA" 0 "CC_GRID_GROUNDING_TN_TT";
VAL_ 796 CC_line1Voltage 511 "SNA";
VAL_ 796 CC_line2Voltage 511 "SNA";
VAL_ 796 CC_line3Voltage 511 "SNA";
VAL_ 796 CC_numPhases 0 "SNA";
VAL_ 796 CC_pilotState 2 "CC_PILOT_STATE_FAULTED" 1 "CC_PILOT_STATE_IDLE" 0 "CC_PILOT_STATE_READY" 3 "CC_PILOT_STATE_SNA";
VAL_ 797 CC_chgStatus2Index 0 "Mux0";
VAL_ 797 CC_buttonState 1 "CC_BUTTON_PRESSED" 0 "CC_BUTTON_RELEASED";
VAL_ 812 CC_logIndex 0 "Mux0" 1 "Mux1" 10 "Mux10" 11 "Mux11" 12 "Mux12" 13 "Mux13" 2 "Mux2" 3 "Mux3" 4 "Mux4";
VAL_ 812 CC_activeConnectorID 255 "SNA";
VAL_ 812 CC_conn1Current 255 "SNA";
VAL_ 812 CC_conn2Current 255 "SNA";
VAL_ 812 CC_conn3Current 255 "SNA";
VAL_ 812 CC_conn4Current 255 "SNA";
VAL_ 812 CC_contactor1Closed 1 "CC_CONTACTOR_CLOSED" 0 "CC_CONTACTOR_OPEN" 3 "CC_CONTACTOR_SNA";
VAL_ 812 CC_contactor2Closed 1 "CC_CONTACTOR_CLOSED" 0 "CC_CONTACTOR_OPEN" 3 "CC_CONTACTOR_SNA";
VAL_ 812 CC_temperature1 127 "SNA";
VAL_ 812 CC_temperature2 127 "SNA";
VAL_ 812 CC_temperature3 127 "SNA";
VAL_ 812 CC_temperature4 127 "SNA";
VAL_ 573 CP_chargeShutdownRequest 2 "EMERGENCY_SHUTDOWN_REQUESTED" 1 "GRACEFUL_SHUTDOWN_REQUESTED" 0 "NO_SHUTDOWN_REQUESTED";
VAL_ 573 CP_hvChargeStatus 1 "CP_CHARGE_CONNECTED" 5 "CP_CHARGE_ENABLED" 6 "CP_CHARGE_FAULTED" 0 "CP_CHARGE_INACTIVE" 2 "CP_CHARGE_STANDBY" 4 "CP_EVSE_TEST_PASSED" 3 "CP_EXT_EVSE_TEST_ACTIVE";
VAL_ 317 CP_chargeShutdownRequest 2 "EMERGENCY_SHUTDOWN_REQUESTED" 1 "GRACEFUL_SHUTDOWN_REQUESTED" 0 "NO_SHUTDOWN_REQUESTED";
VAL_ 317 CP_evseChargeType 2 "AC_CHARGER_PRESENT" 1 "DC_CHARGER_PRESENT" 0 "NO_CHARGER_PRESENT";
VAL_ 317 CP_hvChargeStatus 1 "CP_CHARGE_CONNECTED" 5 "CP_CHARGE_ENABLED" 6 "CP_CHARGE_FAULTED" 0 "CP_CHARGE_INACTIVE" 2 "CP_CHARGE_STANDBY" 4 "CP_EVSE_TEST_PASSED" 3 "CP_EXT_EVSE_TEST_ACTIVE";
VAL_ 1085 CP_chargeShutdownRequest_log 2 "EMERGENCY_SHUTDOWN_REQUESTED" 1 "GRACEFUL_SHUTDOWN_REQUESTED" 0 "NO_SHUTDOWN_REQUESTED";
VAL_ 1085 CP_evseChargeType_log 2 "AC_CHARGER_PRESENT" 1 "DC_CHARGER_PRESENT" 0 "NO_CHARGER_PRESENT";
VAL_ 1085 CP_hvChargeStatus_log 1 "CP_CHARGE_CONNECTED" 5 "CP_CHARGE_ENABLED" 6 "CP_CHARGE_FAULTED" 0 "CP_CHARGE_INACTIVE" 2 "CP_CHARGE_STANDBY" 4 "CP_EVSE_TEST_PASSED" 3 "CP_EXT_EVSE_TEST_ACTIVE";
VAL_ 541 CP_acChargeState 1 "AC_CHARGE_CONNECTED_CHARGE_BLOCKED" 3 "AC_CHARGE_ENABLED" 6 "AC_CHARGE_FAULT" 0 "AC_CHARGE_INACTIVE" 4 "AC_CHARGE_ONBOARD_CHARGER_SHUTDOWN" 2 "AC_CHARGE_STANDBY" 5 "AC_CHARGE_VEH_SHUTDOWN";
VAL_ 541 CP_cableType 2 "CHG_CABLE_TYPE_GB_AC" 3 "CHG_CABLE_TYPE_GB_DC" 0 "CHG_CABLE_TYPE_IEC" 1 "CHG_CABLE_TYPE_SAE" 4 "CHG_CABLE_TYPE_SNA";
VAL_ 541 CP_evseChargeType_UI 2 "AC_CHARGER_PRESENT" 1 "DC_CHARGER_PRESENT" 0 "NO_CHARGER_PRESENT";
VAL_ 541 CP_gbState 10 "GBDC_CHARGE_DISABLING" 5 "GBDC_CHARGE_PARAM_CONFIG" 8 "GBDC_CHARGING" 2 "GBDC_COMMS_RECEIVED" 11 "GBDC_END_OF_CHARGE" 12 "GBDC_ERROR_HANDLING" 14 "GBDC_FAULTED" 3 "GBDC_HANDSHAKING_EXT_ISO" 0 "GBDC_INACTIVE" 7 "GBDC_READY_TO_CHARGE" 4 "GBDC_RECOGNITION" 13 "GBDC_RETRY_CHARGE" 9 "GBDC_STOP_CHARGE_REQUESTED" 15 "GBDC_TESTER_PRESENT" 6 "GBDC_VEH_PACK_PRECHARGE" 1 "GBDC_WAIT_FOR_COMMS";
VAL_ 541 CP_gbdcFailureReason 1 "GBDC_ATTEMPTS_EXPIRED" 3 "GBDC_CRITICAL_FAILURE" 0 "GBDC_FAILURE_NONE" 2 "GBDC_SHUTDOWN_FAILURE";
VAL_ 541 CP_gbdcStopChargeReason 3 "GBDC_COMMS_TIMEOUT" 5 "GBDC_EVSE_CRITICAL_FAULT" 4 "GBDC_EVSE_FAULT" 2 "GBDC_EVSE_REQUESTED" 6 "GBDC_LIVE_DISCONNECT" 0 "GBDC_STOP_REASON_NONE" 7 "GBDC_SUPERCHARGER_COMMS_TIMEOUT" 1 "GBDC_VEH_REQUESTED";
VAL_ 541 CP_iecComboState 6 "IEC_COMBO_CABLE_CHECK" 5 "IEC_COMBO_CHARGE_PARAM_DISCOVERY" 1 "IEC_COMBO_CONNECTED" 8 "IEC_COMBO_ENABLED" 10 "IEC_COMBO_END_OF_CHARGE" 11 "IEC_COMBO_FAULT" 0 "IEC_COMBO_INACTIVE" 4 "IEC_COMBO_PAYMENT_SELECTION" 7 "IEC_COMBO_PRECHARGE" 3 "IEC_COMBO_SERVICE_DISCOVERY" 9 "IEC_COMBO_SHUTDOWN" 2 "IEC_COMBO_V2G_SESSION_SETUP" 12 "IEC_COMBO_WAIT_RESTART";
VAL_ 541 CP_pilot 3 "CHG_PILOT_FAST_CHARGE" 1 "CHG_PILOT_FAULTED" 4 "CHG_PILOT_IDLE" 5 "CHG_PILOT_INVALID" 2 "CHG_PILOT_LINE_CHARGE" 0 "CHG_PILOT_NONE" 7 "CHG_PILOT_SNA" 6 "CHG_PILOT_UNUSED_6";
VAL_ 541 CP_proximity 1 "CHG_PROXIMITY_DISCONNECTED" 3 "CHG_PROXIMITY_LATCHED" 0 "CHG_PROXIMITY_SNA" 2 "CHG_PROXIMITY_UNLATCHED";
VAL_ 541 CP_teslaDcState 1 "TESLA_DC_CONNECTED_CHARGE_BLOCKED" 9 "TESLA_DC_EMERGENCY_SHUTDOWN" 6 "TESLA_DC_ENABLED" 7 "TESLA_DC_EVSE_SHUTDOWN" 5 "TESLA_DC_EXT_PRECHARGE_ACTIVE" 3 "TESLA_DC_EXT_TESTS_ENABLED" 4 "TESLA_DC_EXT_TEST_ACTIVE" 10 "TESLA_DC_FAULT" 0 "TESLA_DC_INACTIVE" 2 "TESLA_DC_STANDBY" 8 "TESLA_DC_VEH_SHUTDOWN";
VAL_ 541 CP_teslaSwcanState 1 "TESLA_SWCAN_ACCEPT" 3 "TESLA_SWCAN_ESTABLISHED" 4 "TESLA_SWCAN_FAULT" 5 "TESLA_SWCAN_GO_TO_SLEEP" 0 "TESLA_SWCAN_INACTIVE" 6 "TESLA_SWCAN_OFFBOARD_UPDATE_IN_PROGRESS" 2 "TESLA_SWCAN_RECEIVE";
VAL_ 1859 VCRIGHT_mirrorRecallStatus 2 "RECALL_COMPLETE" 3 "RECALL_INTERRUPTED" 1 "RECALL_IN_PROGRESS" 0 "RECALL_SNA";
VAL_ 1859 VCRIGHT_seatRecallStatus 2 "RECALL_COMPLETE" 3 "RECALL_INTERRUPTED" 1 "RECALL_IN_PROGRESS" 0 "RECALL_SNA";
VAL_ 1859 VCRIGHT_systemRecallStatus 2 "RECALL_COMPLETE" 3 "RECALL_INTERRUPTED" 1 "RECALL_IN_PROGRESS" 0 "RECALL_SNA";
VAL_ 1885 CP_sensorDataSelect 2 "CP_SENSOR_DOOR" 0 "CP_SENSOR_DOOR_COUNTS" 4 "CP_SENSOR_INDUCTIVE_DOOR" 12 "CP_SENSOR_INLET_HARNESS_ID" 3 "CP_SENSOR_LATCH" 9 "CP_SENSOR_PILOT" 10 "CP_SENSOR_PILOT2" 1 "CP_SENSOR_PIN_TEMP" 8 "CP_SENSOR_PROX" 11 "CP_SENSOR_PROX_GB" 7 "CP_SENSOR_RAILS" 5 "CP_SENSOR_SAFETY" 6 "CP_SENSOR_UHF";
VAL_ 1885 CP_inlet1HarnessIdState 1 "HARNESS_PEDIGREE_INVALID" 0 "HARNESS_PEDIGREE_UNKNOWN_SNA" 2 "HARNESS_PEDIGREE_VALID";
VAL_ 1885 CP_inlet2HarnessIdState 1 "HARNESS_PEDIGREE_INVALID" 0 "HARNESS_PEDIGREE_UNKNOWN_SNA" 2 "HARNESS_PEDIGREE_VALID";
VAL_ 1962 HVP_debugMessageMultiplexer 0 "Mux0" 1 "Mux1" 2 "Mux2" 3 "Mux3" 4 "Mux4" 5 "Mux5" 6 "Mux6";
VAL_ 1962 HVP_shuntAsicTempDbg 32768 "SHUNT_TEMPERATURE_SNA";
VAL_ 1962 HVP_shuntAsicTempStatus 1 "SHUNT_DATA_INVALID" 0 "SHUNT_DATA_NOT_AVAILABLE" 3 "SHUNT_DATA_STALE" 2 "SHUNT_DATA_VALID";
VAL_ 1962 HVP_shuntAuxCurrentStatus 1 "SHUNT_DATA_INVALID" 0 "SHUNT_DATA_NOT_AVAILABLE" 3 "SHUNT_DATA_STALE" 2 "SHUNT_DATA_VALID";
VAL_ 1962 HVP_shuntBarTempDbg 32768 "SHUNT_TEMPERATURE_SNA";
VAL_ 1962 HVP_shuntBarTempStatus 1 "SHUNT_DATA_INVALID" 0 "SHUNT_DATA_NOT_AVAILABLE" 3 "SHUNT_DATA_STALE" 2 "SHUNT_DATA_VALID";
VAL_ 819 UI_acChargeCurrentLimit 127 "SNA";
VAL_ 820 UI_limitMode 2 "LIMIT_FACTORY" 0 "LIMIT_NORMAL" 3 "LIMIT_SERVICE" 1 "LIMIT_VALET";
VAL_ 820 UI_motorOnMode 1 "MOTORONMODE_FRONT_ONLY" 0 "MOTORONMODE_NORMAL" 2 "MOTORONMODE_REAR_ONLY";
VAL_ 820 UI_pedalMap 0 "CHILL" 2 "PERFORMANCE" 1 "SPORT";
VAL_ 820 UI_speedLimit 255 "SNA";
VAL_ 820 UI_stoppingMode 1 "CREEP" 2 "HOLD" 0 "STANDARD";
VAL_ 820 UI_systemPowerLimit 31 "SNA";
VAL_ 820 UI_systemTorqueLimit 63 "SNA";
VAL_ 820 UI_wasteMode 2 "WASTE_TYPE_FULL" 0 "WASTE_TYPE_NONE" 1 "WASTE_TYPE_PARTIAL";
VAL_ 820 UI_wasteModeRegenLimit 3 "MAX_REGEN_CURRENT_0A" 2 "MAX_REGEN_CURRENT_10A" 1 "MAX_REGEN_CURRENT_30A" 0 "MAX_REGEN_CURRENT_MAX";
VAL_ 820 UI_closureConfirmed 1 "CONFIRMED_FRUNK" 0 "CONFIRMED_NONE" 2 "CONFIRMED_PROX";
VAL_ 577 VCFRONT_coolantAirPurgeBatState 1 "AIR_PURGE_STATE_ACTIVE" 2 "AIR_PURGE_STATE_COMPLETE" 0 "AIR_PURGE_STATE_INACTIVE" 3 "AIR_PURGE_STATE_INTERRUPTED" 4 "AIR_PURGE_STATE_PENDING";
VAL_ 577 VCFRONT_coolantFlowBatReason 4 "ACTIVE_MANAGER_BATT" 9 "ACTIVE_MANAGER_PT" 6 "BMS_FLOW_REQ" 1 "COOLANT_AIR_PURGE" 7 "DAS_FLOW_REQ" 13 "DIS_FLOW_REQ" 12 "DI_FLOW_REQ" 14 "HP_FLOW_REQ" 0 "NONE" 2 "NO_FLOW_REQ" 3 "OVERRIDE_BATT" 8 "OVERRIDE_PT" 5 "PASSIVE_MANAGER_BATT" 10 "PASSIVE_MANAGER_PT" 11 "PCS_FLOW_REQ";
VAL_ 577 VCFRONT_coolantFlowPTReason 4 "ACTIVE_MANAGER_BATT" 9 "ACTIVE_MANAGER_PT" 6 "BMS_FLOW_REQ" 1 "COOLANT_AIR_PURGE" 7 "DAS_FLOW_REQ" 13 "DIS_FLOW_REQ" 12 "DI_FLOW_REQ" 14 "HP_FLOW_REQ" 0 "NONE" 2 "NO_FLOW_REQ" 3 "OVERRIDE_BATT" 8 "OVERRIDE_PT" 5 "PASSIVE_MANAGER_BATT" 10 "PASSIVE_MANAGER_PT" 11 "PCS_FLOW_REQ";
VAL_ 577 VCFRONT_wasteHeatRequestType 2 "WASTE_TYPE_FULL" 0 "WASTE_TYPE_NONE" 1 "WASTE_TYPE_PARTIAL";
VAL_ 708 PCS_logMessageSelect 3 "PCS_LOG_CHG_1" 4 "PCS_LOG_CHG_2" 5 "PCS_LOG_CHG_3" 13 "PCS_LOG_CHG_4" 21 "PCS_LOG_CHG_LINE_OFFSET" 23 "PCS_LOG_CHG_MACHINEMODEL" 20 "PCS_LOG_CHG_NO_FLOW" 6 "PCS_LOG_DCDC_1" 7 "PCS_LOG_DCDC_2" 8 "PCS_LOG_DCDC_3" 18 "PCS_LOG_DCDC_4" 19 "PCS_LOG_DCDC_5" 24 "PCS_LOG_DCDC_HVBUS_PCHG_DATA" 25 "PCS_LOG_DCDC_IMPEDANCE_EST" 22 "PCS_LOG_DCDC_STATISTICS" 14 "PCS_LOG_DLOG_1" 15 "PCS_LOG_DLOG_2" 16 "PCS_LOG_DLOG_3" 17 "PCS_LOG_DLOG_4" 26 "PCS_LOG_NUM_MSGS" 0 "PCS_LOG_PHA_1" 10 "PCS_LOG_PHA_2" 1 "PCS_LOG_PHB_1" 11 "PCS_LOG_PHB_2" 2 "PCS_LOG_PHC_1" 12 "PCS_LOG_PHC_2" 9 "PCS_LOG_SYSTEM_1";
VAL_ 708 PCS_acChargeSelfTestState 0 "PCS_SELF_TEST_IDLE" 1 "PCS_SELF_TEST_STARTED";
VAL_ 708 PCS_chgAcpwHeartbeatState 2 "PCS_ACPW_HEARTBEAT_STATE_DETECTED_OFFGRID" 3 "PCS_ACPW_HEARTBEAT_STATE_DETECTED_ONGRID" 1 "PCS_ACPW_HEARTBEAT_STATE_NOT_DETECTED" 4 "PCS_ACPW_HEARTBEAT_STATE_NUM" 0 "PCS_ACPW_HEARTBEAT_STATE_UNKNOWN";
VAL_ 708 PCS_chgInputFrequencyL1N 0 "FREQUENCY_UNKNOWN";
VAL_ 708 PCS_chgInputFrequencyL2N 0 "FREQUENCY_UNKNOWN";
VAL_ 708 PCS_chgInputFrequencyL3N 0 "FREQUENCY_UNKNOWN";
VAL_ 708 PCS_chgInternalPhaseConfig 5 "PHASE_CONFIG_MFG_TEST_CONFIG_1" 6 "PHASE_CONFIG_MFG_TEST_CONFIG_2" 7 "PHASE_CONFIG_RELIABILITY_SINGLE_PHASE" 1 "PHASE_CONFIG_SINGLE_PHASE" 8 "PHASE_CONFIG_SINGLE_PHASE_EVSE_PARALLEL" 4 "PHASE_CONFIG_SINGLE_PHASE_IEC_GB" 0 "PHASE_CONFIG_SNA" 2 "PHASE_CONFIG_THREE_PHASE" 3 "PHASE_CONFIG_THREE_PHASE_DELTA" 9 "PHASE_CONFIG_TOTAL_NUM";
VAL_ 708 PCS_chgPhALastShutdownReason 12 "PCS_PH_SHUTDOWN_CONTROL_REGULATION_FAULT" 16 "PCS_PH_SHUTDOWN_FREQ_OUT_OF_RANGE" 2 "PCS_PH_SHUTDOWN_HW_ENABLE" 4 "PCS_PH_SHUTDOWN_HW_FAULT" 7 "PCS_PH_SHUTDOWN_INPUT_OV" 6 "PCS_PH_SHUTDOWN_INPUT_UV" 11 "PCS_PH_SHUTDOWN_INT_BUS_UV" 17 "PCS_PH_SHUTDOWN_LINE_TRANSIENT_FAULT" 9 "PCS_PH_SHUTDOWN_OUTPUT_OV" 8 "PCS_PH_SHUTDOWN_OUTPUT_UV" 13 "PCS_PH_SHUTDOWN_OVER_TEMPERATURE" 5 "PCS_PH_SHUTDOWN_PLL_NOT_LOCKED" 10 "PCS_PH_SHUTDOWN_PRECHARGE_TIMEOUT" 0 "PCS_PH_SHUTDOWN_REASON_NONE" 15 "PCS_PH_SHUTDOWN_SENSOR_IRRATIONAL" 1 "PCS_PH_SHUTDOWN_SW_ENABLE" 3 "PCS_PH_SHUTDOWN_SW_FAULT" 14 "PCS_PH_SHUTDOWN_TEMP_IRRATIONAL";
VAL_ 708 PCS_chgPhAState 5 "PCS_PH_STATE_CLEAR_FAULTS" 3 "PCS_PH_STATE_ENABLE" 4 "PCS_PH_STATE_FAULT" 1 "PCS_PH_STATE_IDLE" 0 "PCS_PH_STATE_INIT" 2 "PCS_PH_STATE_PRECHARGE" 6 "PCS_PH_STATE_SHUTTING_DOWN";
VAL_ 708 PCS_chgPhBLastShutdownReason 12 "PCS_PH_SHUTDOWN_CONTROL_REGULATION_FAULT" 16 "PCS_PH_SHUTDOWN_FREQ_OUT_OF_RANGE" 2 "PCS_PH_SHUTDOWN_HW_ENABLE" 4 "PCS_PH_SHUTDOWN_HW_FAULT" 7 "PCS_PH_SHUTDOWN_INPUT_OV" 6 "PCS_PH_SHUTDOWN_INPUT_UV" 11 "PCS_PH_SHUTDOWN_INT_BUS_UV" 17 "PCS_PH_SHUTDOWN_LINE_TRANSIENT_FAULT" 9 "PCS_PH_SHUTDOWN_OUTPUT_OV" 8 "PCS_PH_SHUTDOWN_OUTPUT_UV" 13 "PCS_PH_SHUTDOWN_OVER_TEMPERATURE" 5 "PCS_PH_SHUTDOWN_PLL_NOT_LOCKED" 10 "PCS_PH_SHUTDOWN_PRECHARGE_TIMEOUT" 0 "PCS_PH_SHUTDOWN_REASON_NONE" 15 "PCS_PH_SHUTDOWN_SENSOR_IRRATIONAL" 1 "PCS_PH_SHUTDOWN_SW_ENABLE" 3 "PCS_PH_SHUTDOWN_SW_FAULT" 14 "PCS_PH_SHUTDOWN_TEMP_IRRATIONAL";
VAL_ 708 PCS_chgPhBState 5 "PCS_PH_STATE_CLEAR_FAULTS" 3 "PCS_PH_STATE_ENABLE" 4 "PCS_PH_STATE_FAULT" 1 "PCS_PH_STATE_IDLE" 0 "PCS_PH_STATE_INIT" 2 "PCS_PH_STATE_PRECHARGE" 6 "PCS_PH_STATE_SHUTTING_DOWN";
VAL_ 708 PCS_chgPhCLastShutdownReason 12 "PCS_PH_SHUTDOWN_CONTROL_REGULATION_FAULT" 16 "PCS_PH_SHUTDOWN_FREQ_OUT_OF_RANGE" 2 "PCS_PH_SHUTDOWN_HW_ENABLE" 4 "PCS_PH_SHUTDOWN_HW_FAULT" 7 "PCS_PH_SHUTDOWN_INPUT_OV" 6 "PCS_PH_SHUTDOWN_INPUT_UV" 11 "PCS_PH_SHUTDOWN_INT_BUS_UV" 17 "PCS_PH_SHUTDOWN_LINE_TRANSIENT_FAULT" 9 "PCS_PH_SHUTDOWN_OUTPUT_OV" 8 "PCS_PH_SHUTDOWN_OUTPUT_UV" 13 "PCS_PH_SHUTDOWN_OVER_TEMPERATURE" 5 "PCS_PH_SHUTDOWN_PLL_NOT_LOCKED" 10 "PCS_PH_SHUTDOWN_PRECHARGE_TIMEOUT" 0 "PCS_PH_SHUTDOWN_REASON_NONE" 15 "PCS_PH_SHUTDOWN_SENSOR_IRRATIONAL" 1 "PCS_PH_SHUTDOWN_SW_ENABLE" 3 "PCS_PH_SHUTDOWN_SW_FAULT" 14 "PCS_PH_SHUTDOWN_TEMP_IRRATIONAL";
VAL_ 708 PCS_chgPhCState 5 "PCS_PH_STATE_CLEAR_FAULTS" 3 "PCS_PH_STATE_ENABLE" 4 "PCS_PH_STATE_FAULT" 1 "PCS_PH_STATE_IDLE" 0 "PCS_PH_STATE_INIT" 2 "PCS_PH_STATE_PRECHARGE" 6 "PCS_PH_STATE_SHUTTING_DOWN";
VAL_ 708 PCS_chgPhasesPriority 36 "PHASES_PRIORITY_ABC" 24 "PHASES_PRIORITY_ACB" 33 "PHASES_PRIORITY_BAC" 9 "PHASES_PRIORITY_BCA" 18 "PHASES_PRIORITY_CAB" 6 "PHASES_PRIORITY_CBA" 0 "UNDEFINED_PHASES_PRIORITY";
VAL_ 708 PCS_cpu2BootState 2 "CPU2_STATE_APPLICATION" 1 "CPU2_STATE_BOOTLOADER" 0 "CPU2_STATE_BOOTROM" 3 "CPU2_STATE_ERROR";
VAL_ 708 PCS_dLogPhAChannel1Content 1 "PCS_DLOG_INPUT_CURRENT" 0 "PCS_DLOG_INPUT_VOLTAGE" 3 "PCS_DLOG_INT_BUS_VOLTAGE" 2 "PCS_DLOG_OUTPUT_CURRENT";
VAL_ 708 PCS_dLogPhAChannel2Content 1 "PCS_DLOG_INPUT_CURRENT" 0 "PCS_DLOG_INPUT_VOLTAGE" 3 "PCS_DLOG_INT_BUS_VOLTAGE" 2 "PCS_DLOG_OUTPUT_CURRENT";
VAL_ 708 PCS_dLogPhAChannel3Content 1 "PCS_DLOG_INPUT_CURRENT" 0 "PCS_DLOG_INPUT_VOLTAGE" 3 "PCS_DLOG_INT_BUS_VOLTAGE" 2 "PCS_DLOG_OUTPUT_CURRENT";
VAL_ 708 PCS_dLogPhAChannel4Content 1 "PCS_DLOG_INPUT_CURRENT" 0 "PCS_DLOG_INPUT_VOLTAGE" 3 "PCS_DLOG_INT_BUS_VOLTAGE" 2 "PCS_DLOG_OUTPUT_CURRENT";
VAL_ 708 PCS_dLogPhBChannel1Content 1 "PCS_DLOG_INPUT_CURRENT" 0 "PCS_DLOG_INPUT_VOLTAGE" 3 "PCS_DLOG_INT_BUS_VOLTAGE" 2 "PCS_DLOG_OUTPUT_CURRENT";
VAL_ 708 PCS_dLogPhBChannel2Content 1 "PCS_DLOG_INPUT_CURRENT" 0 "PCS_DLOG_INPUT_VOLTAGE" 3 "PCS_DLOG_INT_BUS_VOLTAGE" 2 "PCS_DLOG_OUTPUT_CURRENT";
VAL_ 708 PCS_dLogPhBChannel3Content 1 "PCS_DLOG_INPUT_CURRENT" 0 "PCS_DLOG_INPUT_VOLTAGE" 3 "PCS_DLOG_INT_BUS_VOLTAGE" 2 "PCS_DLOG_OUTPUT_CURRENT";
VAL_ 708 PCS_dLogPhBChannel4Content 1 "PCS_DLOG_INPUT_CURRENT" 0 "PCS_DLOG_INPUT_VOLTAGE" 3 "PCS_DLOG_INT_BUS_VOLTAGE" 2 "PCS_DLOG_OUTPUT_CURRENT";
VAL_ 708 PCS_dLogPhCChannel1Content 1 "PCS_DLOG_INPUT_CURRENT" 0 "PCS_DLOG_INPUT_VOLTAGE" 3 "PCS_DLOG_INT_BUS_VOLTAGE" 2 "PCS_DLOG_OUTPUT_CURRENT";
VAL_ 708 PCS_dLogPhCChannel2Content 1 "PCS_DLOG_INPUT_CURRENT" 0 "PCS_DLOG_INPUT_VOLTAGE" 3 "PCS_DLOG_INT_BUS_VOLTAGE" 2 "PCS_DLOG_OUTPUT_CURRENT";
VAL_ 708 PCS_dLogPhCChannel3Content 1 "PCS_DLOG_INPUT_CURRENT" 0 "PCS_DLOG_INPUT_VOLTAGE" 3 "PCS_DLOG_INT_BUS_VOLTAGE" 2 "PCS_DLOG_OUTPUT_CURRENT";
VAL_ 708 PCS_dLogPhCChannel4Content 1 "PCS_DLOG_INPUT_CURRENT" 0 "PCS_DLOG_INPUT_VOLTAGE" 3 "PCS_DLOG_INT_BUS_VOLTAGE" 2 "PCS_DLOG_OUTPUT_CURRENT";
VAL_ 708 PCS_dcdcTankVoltage 1024 "TANK_VOLTAGE_SNA";
VAL_ 1493 DI_IGBTJunctTemp 255 "SNA";
VAL_ 1493 DI_torqueWearTotal 255 "SNA";
VAL_ 1366 DIF_IGBTJunctTemp 255 "SNA";
VAL_ 1366 DIF_torqueWearTotal 255 "SNA";
VAL_ 2005 DIR_aebFaultReason 9 "DI_AEB_FAULT_ACCEL_OUT_OF_BOUNDS" 14 "DI_AEB_FAULT_ACCEL_REQ_INVALID" 5 "DI_AEB_FAULT_DAS_CONTROL_MIA" 15 "DI_AEB_FAULT_DAS_REQ_DI_UNAVAIL" 6 "DI_AEB_FAULT_DAS_SNA" 3 "DI_AEB_FAULT_EBR_FAULT" 1 "DI_AEB_FAULT_EPB_MIA" 10 "DI_AEB_FAULT_EPB_NOT_PARKED" 11 "DI_AEB_FAULT_ESP_FAULT" 12 "DI_AEB_FAULT_ESP_MIA" 13 "DI_AEB_FAULT_MIN_TIME_BTWN_EVENTS" 0 "DI_AEB_FAULT_NONE" 2 "DI_AEB_FAULT_PM_MIA" 8 "DI_AEB_FAULT_PM_REQUEST" 4 "DI_AEB_FAULT_SPEED_DELTA" 7 "DI_AEB_FAULT_VEL_EST_ABNORMAL";
VAL_ 2005 DIR_aebUnavailableReason 1 "DI_AEB_UNAVAILABLE_CLOSURE" 5 "DI_AEB_UNAVAILABLE_DI_STATE" 6 "DI_AEB_UNAVAILABLE_EBR_UNAVAILABLE" 7 "DI_AEB_UNAVAILABLE_EPB" 2 "DI_AEB_UNAVAILABLE_GEAR" 8 "DI_AEB_UNAVAILABLE_HYSTERESIS" 4 "DI_AEB_UNAVAILABLE_NEGATIVE_SPEED" 0 "DI_AEB_UNAVAILABLE_NONE" 10 "DI_AEB_UNAVAILABLE_REVERSE_SPEED" 3 "DI_AEB_UNAVAILABLE_SKID" 9 "DI_AEB_UNAVAILABLE_TRACK_MODE";
VAL_ 2005 DIR_brkStState 6 "BRKST_STATE_FINISHED" 1 "BRKST_STATE_IDLE" 5 "BRKST_STATE_INTERRUPTED" 4 "BRKST_STATE_RUNNING_PRESSED" 3 "BRKST_STATE_RUNNING_PRESSING" 2 "BRKST_STATE_RUNNING_UNPRESSED" 0 "BRKST_STATE_UNAVAILABLE";
VAL_ 2005 DIR_fluxState 5 "DI_FLUXSTATE_ENABLED" 9 "DI_FLUXSTATE_FAULT" 4 "DI_FLUXSTATE_FLUX_DOWN" 3 "DI_FLUXSTATE_FLUX_UP" 6 "DI_FLUXSTATE_ICONTROL" 2 "DI_FLUXSTATE_STANDBY" 0 "DI_FLUXSTATE_START" 10 "DI_FLUXSTATE_STATIONARY_WASTE" 1 "DI_FLUXSTATE_TEST" 7 "DI_FLUXSTATE_VCONTROL";
VAL_ 2005 DIR_gateDriveState 3 "PSTG_GD_STATE_CONFIGURED" 2 "PSTG_GD_STATE_CONFIGURING" 0 "PSTG_GD_STATE_INIT" 4 "PSTG_GD_STATE_NOT_CONFIGURED" 1 "PSTG_GD_STATE_SELFTEST";
VAL_ 2005 DIR_gateDriveSupplyState 0 "PSTG_GD_SUPPLY_DOWN" 3 "PSTG_GD_SUPPLY_FALLING" 1 "PSTG_GD_SUPPLY_RISING" 2 "PSTG_GD_SUPPLY_UP";
VAL_ 2005 DIR_immobilizerCondition 1 "DI_IMM_CONDITION_LEARNED" 0 "DI_IMM_CONDITION_VIRGIN_SNA";
VAL_ 2005 DIR_magnetTempEst 0 "SNA";
VAL_ 2005 DIR_motorType 8 "DI_MOTOR_F1A" 10 "DI_MOTOR_F1AC" 11 "DI_MOTOR_F2AB" 12 "DI_MOTOR_F2AC" 13 "DI_MOTOR_F2AD" 14 "DI_MOTOR_F2AE" 26 "DI_MOTOR_F2AE_AL" 15 "DI_MOTOR_F2APMSRM" 17 "DI_MOTOR_IM100A" 19 "DI_MOTOR_IM100B" 22 "DI_MOTOR_IM130C" 24 "DI_MOTOR_IM130D" 25 "DI_MOTOR_IM130D_AL" 27 "DI_MOTOR_IM130D_AL_POSCO" 20 "DI_MOTOR_IM216A" 3 "DI_MOTOR_M7M3" 4 "DI_MOTOR_M7M4" 5 "DI_MOTOR_M7M5" 7 "DI_MOTOR_M7M6" 6 "DI_MOTOR_M8A" 16 "DI_MOTOR_PM216A" 18 "DI_MOTOR_PM216B" 21 "DI_MOTOR_PM216C" 23 "DI_MOTOR_PM216D" 28 "DI_MOTOR_PM275B" 1 "DI_MOTOR_ROADSTER_BASE" 2 "DI_MOTOR_ROADSTER_SPORT" 0 "DI_MOTOR_SNA" 9 "DI_MOTOR_SSR1A";
VAL_ 2005 DIR_oilPumpPhaseVoltage 255 "SNA";
VAL_ 2005 DIR_oilPumpPressureEstimateMax 255 "SNA";
VAL_ 2005 DIR_oilPumpPressureExpectedMin 255 "SNA";
VAL_ 2005 DIR_opdUnavailableReason 1 "DI_OPD_UNAVAILABLE_DISABLED" 4 "DI_OPD_UNAVAILABLE_DI_SYS_STATE" 7 "DI_OPD_UNAVAILABLE_EPB_FAULT" 3 "DI_OPD_UNAVAILABLE_GEAR" 11 "DI_OPD_UNAVAILABLE_GRADE_ESTIMATE" 5 "DI_OPD_UNAVAILABLE_INVALID_BRAKE_SENSE" 14 "DI_OPD_UNAVAILABLE_INVALID_MSPD" 15 "DI_OPD_UNAVAILABLE_MOTOR_HOLD_TIMEOUT" 0 "DI_OPD_UNAVAILABLE_NONE" 13 "DI_OPD_UNAVAILABLE_PARKED" 2 "DI_OPD_UNAVAILABLE_PM_FAULT" 6 "DI_OPD_UNAVAILABLE_SKID" 12 "DI_OPD_UNAVAILABLE_TORQUE_LIMIT" 8 "DI_OPD_UNAVAILABLE_TRACK_MODE" 10 "DI_OPD_UNAVAILABLE_TRACTION_CONTROL" 9 "DI_OPD_UNAVAILABLE_VELOCITY_ESTIMATE";
VAL_ 2005 DIR_powerStageSafeState 2 "PSTG_SAFESTATE_3PS_HIGH" 3 "PSTG_SAFESTATE_3PS_LOW" 1 "PSTG_SAFESTATE_ALL_OFF" 0 "PSTG_SAFESTATE_NONE";
VAL_ 2005 DIR_rotorOffsetLearningState 9 "ROL_NUM_STATES" 2 "ROL_STATE_ACCELERATE" 5 "ROL_STATE_CORRECT" 8 "ROL_STATE_DONE" 0 "ROL_STATE_INIT" 4 "ROL_STATE_MEASURE" 3 "ROL_STATE_SHIFT" 6 "ROL_STATE_VERIFY" 1 "ROL_STATE_WAIT" 7 "ROL_STATE_WRITE";
VAL_ 2005 DIR_ssmState 5 "SSM_STATE_ABORT" 4 "SSM_STATE_ENABLE" 8 "SSM_STATE_FAULT" 2 "SSM_STATE_IDLE" 7 "SSM_STATE_RETRY" 3 "SSM_STATE_STANDBY" 0 "SSM_STATE_START" 1 "SSM_STATE_UNAVAILABLE" 6 "SSM_STATE_WAIT_FOR_RETRY";
VAL_ 2005 DIR_tcMaxRequest 255 "SNA";
VAL_ 2005 DIR_tcMinRequest 255 "SNA";
VAL_ 2005 DIR_usmState 3 "USM_STATE_ABORT" 4 "USM_STATE_ENABLE" 5 "USM_STATE_FAULT" 2 "USM_STATE_RETRY" 1 "USM_STATE_STANDBY" 0 "USM_STATE_START" 6 "USM_STATE_UNAVAILABLE" 7 "USM_STATE_WAIT_FOR_RETRY";
VAL_ 2005 DIR_velocityEstimatorState 4 "VE_STATE_BACKUP_MOTOR" 2 "VE_STATE_BACKUP_WHEELS_A" 3 "VE_STATE_BACKUP_WHEELS_B" 0 "VE_STATE_NOT_INITIALIZED" 1 "VE_STATE_WHEELS_NORMAL";
VAL_ 1879 DIF_aebFaultReason 9 "DI_AEB_FAULT_ACCEL_OUT_OF_BOUNDS" 14 "DI_AEB_FAULT_ACCEL_REQ_INVALID" 5 "DI_AEB_FAULT_DAS_CONTROL_MIA" 15 "DI_AEB_FAULT_DAS_REQ_DI_UNAVAIL" 6 "DI_AEB_FAULT_DAS_SNA" 3 "DI_AEB_FAULT_EBR_FAULT" 1 "DI_AEB_FAULT_EPB_MIA" 10 "DI_AEB_FAULT_EPB_NOT_PARKED" 11 "DI_AEB_FAULT_ESP_FAULT" 12 "DI_AEB_FAULT_ESP_MIA" 13 "DI_AEB_FAULT_MIN_TIME_BTWN_EVENTS" 0 "DI_AEB_FAULT_NONE" 2 "DI_AEB_FAULT_PM_MIA" 8 "DI_AEB_FAULT_PM_REQUEST" 4 "DI_AEB_FAULT_SPEED_DELTA" 7 "DI_AEB_FAULT_VEL_EST_ABNORMAL";
VAL_ 1879 DIF_aebUnavailableReason 1 "DI_AEB_UNAVAILABLE_CLOSURE" 5 "DI_AEB_UNAVAILABLE_DI_STATE" 6 "DI_AEB_UNAVAILABLE_EBR_UNAVAILABLE" 7 "DI_AEB_UNAVAILABLE_EPB" 2 "DI_AEB_UNAVAILABLE_GEAR" 8 "DI_AEB_UNAVAILABLE_HYSTERESIS" 4 "DI_AEB_UNAVAILABLE_NEGATIVE_SPEED" 0 "DI_AEB_UNAVAILABLE_NONE" 10 "DI_AEB_UNAVAILABLE_REVERSE_SPEED" 3 "DI_AEB_UNAVAILABLE_SKID" 9 "DI_AEB_UNAVAILABLE_TRACK_MODE";
VAL_ 1879 DIF_brkStState 6 "BRKST_STATE_FINISHED" 1 "BRKST_STATE_IDLE" 5 "BRKST_STATE_INTERRUPTED" 4 "BRKST_STATE_RUNNING_PRESSED" 3 "BRKST_STATE_RUNNING_PRESSING" 2 "BRKST_STATE_RUNNING_UNPRESSED" 0 "BRKST_STATE_UNAVAILABLE";
VAL_ 1879 DIF_fluxState 5 "DI_FLUXSTATE_ENABLED" 9 "DI_FLUXSTATE_FAULT" 4 "DI_FLUXSTATE_FLUX_DOWN" 3 "DI_FLUXSTATE_FLUX_UP" 6 "DI_FLUXSTATE_ICONTROL" 2 "DI_FLUXSTATE_STANDBY" 0 "DI_FLUXSTATE_START" 10 "DI_FLUXSTATE_STATIONARY_WASTE" 1 "DI_FLUXSTATE_TEST" 7 "DI_FLUXSTATE_VCONTROL";
VAL_ 1879 DIF_gateDriveState 3 "PSTG_GD_STATE_CONFIGURED" 2 "PSTG_GD_STATE_CONFIGURING" 0 "PSTG_GD_STATE_INIT" 4 "PSTG_GD_STATE_NOT_CONFIGURED" 1 "PSTG_GD_STATE_SELFTEST";
VAL_ 1879 DIF_gateDriveSupplyState 0 "PSTG_GD_SUPPLY_DOWN" 3 "PSTG_GD_SUPPLY_FALLING" 1 "PSTG_GD_SUPPLY_RISING" 2 "PSTG_GD_SUPPLY_UP";
VAL_ 1879 DIF_immobilizerCondition 1 "DI_IMM_CONDITION_LEARNED" 0 "DI_IMM_CONDITION_VIRGIN_SNA";
VAL_ 1879 DIF_magnetTempEst 0 "SNA";
VAL_ 1879 DIF_motorType 8 "DI_MOTOR_F1A" 10 "DI_MOTOR_F1AC" 11 "DI_MOTOR_F2AB" 12 "DI_MOTOR_F2AC" 13 "DI_MOTOR_F2AD" 14 "DI_MOTOR_F2AE" 26 "DI_MOTOR_F2AE_AL" 15 "DI_MOTOR_F2APMSRM" 17 "DI_MOTOR_IM100A" 19 "DI_MOTOR_IM100B" 22 "DI_MOTOR_IM130C" 24 "DI_MOTOR_IM130D" 25 "DI_MOTOR_IM130D_AL" 27 "DI_MOTOR_IM130D_AL_POSCO" 20 "DI_MOTOR_IM216A" 3 "DI_MOTOR_M7M3" 4 "DI_MOTOR_M7M4" 5 "DI_MOTOR_M7M5" 7 "DI_MOTOR_M7M6" 6 "DI_MOTOR_M8A" 16 "DI_MOTOR_PM216A" 18 "DI_MOTOR_PM216B" 21 "DI_MOTOR_PM216C" 23 "DI_MOTOR_PM216D" 28 "DI_MOTOR_PM275B" 1 "DI_MOTOR_ROADSTER_BASE" 2 "DI_MOTOR_ROADSTER_SPORT" 0 "DI_MOTOR_SNA" 9 "DI_MOTOR_SSR1A";
VAL_ 1879 DIF_oilPumpPhaseVoltage 255 "SNA";
VAL_ 1879 DIF_oilPumpPressureEstimateMax 255 "SNA";
VAL_ 1879 DIF_oilPumpPressureExpectedMin 255 "SNA";
VAL_ 1879 DIF_opdUnavailableReason 1 "DI_OPD_UNAVAILABLE_DISABLED" 4 "DI_OPD_UNAVAILABLE_DI_SYS_STATE" 7 "DI_OPD_UNAVAILABLE_EPB_FAULT" 3 "DI_OPD_UNAVAILABLE_GEAR" 11 "DI_OPD_UNAVAILABLE_GRADE_ESTIMATE" 5 "DI_OPD_UNAVAILABLE_INVALID_BRAKE_SENSE" 14 "DI_OPD_UNAVAILABLE_INVALID_MSPD" 15 "DI_OPD_UNAVAILABLE_MOTOR_HOLD_TIMEOUT" 0 "DI_OPD_UNAVAILABLE_NONE" 13 "DI_OPD_UNAVAILABLE_PARKED" 2 "DI_OPD_UNAVAILABLE_PM_FAULT" 6 "DI_OPD_UNAVAILABLE_SKID" 12 "DI_OPD_UNAVAILABLE_TORQUE_LIMIT" 8 "DI_OPD_UNAVAILABLE_TRACK_MODE" 10 "DI_OPD_UNAVAILABLE_TRACTION_CONTROL" 9 "DI_OPD_UNAVAILABLE_VELOCITY_ESTIMATE";
VAL_ 1879 DIF_powerStageSafeState 2 "PSTG_SAFESTATE_3PS_HIGH" 3 "PSTG_SAFESTATE_3PS_LOW" 1 "PSTG_SAFESTATE_ALL_OFF" 0 "PSTG_SAFESTATE_NONE";
VAL_ 1879 DIF_rotorOffsetLearningState 9 "ROL_NUM_STATES" 2 "ROL_STATE_ACCELERATE" 5 "ROL_STATE_CORRECT" 8 "ROL_STATE_DONE" 0 "ROL_STATE_INIT" 4 "ROL_STATE_MEASURE" 3 "ROL_STATE_SHIFT" 6 "ROL_STATE_VERIFY" 1 "ROL_STATE_WAIT" 7 "ROL_STATE_WRITE";
VAL_ 1879 DIF_ssmState 5 "SSM_STATE_ABORT" 4 "SSM_STATE_ENABLE" 8 "SSM_STATE_FAULT" 2 "SSM_STATE_IDLE" 7 "SSM_STATE_RETRY" 3 "SSM_STATE_STANDBY" 0 "SSM_STATE_START" 1 "SSM_STATE_UNAVAILABLE" 6 "SSM_STATE_WAIT_FOR_RETRY";
VAL_ 1879 DIF_tcMaxRequest 255 "SNA";
VAL_ 1879 DIF_tcMinRequest 255 "SNA";
VAL_ 1879 DIF_usmState 3 "USM_STATE_ABORT" 4 "USM_STATE_ENABLE" 5 "USM_STATE_FAULT" 2 "USM_STATE_RETRY" 1 "USM_STATE_STANDBY" 0 "USM_STATE_START" 6 "USM_STATE_UNAVAILABLE" 7 "USM_STATE_WAIT_FOR_RETRY";
VAL_ 1879 DIF_velocityEstimatorState 4 "VE_STATE_BACKUP_MOTOR" 2 "VE_STATE_BACKUP_WHEELS_A" 3 "VE_STATE_BACKUP_WHEELS_B" 0 "VE_STATE_NOT_INITIALIZED" 1 "VE_STATE_WHEELS_NORMAL";
VAL_ 694 DI_ptcStateUI 0 "FAULTED" 1 "BACKUP" 2 "ON" 3 "SNA";
VAL_ 694 DI_tractionControlModeUI 0 "NORMAL" 1 "SLIP_START" 2 "DEV_MODE_1" 3 "DEV_MODE_2" 4 "ROLLS_MODE" 5 "DYNO_MODE" 6 "OFFROAD_ASSIST";
